BU_:  Airbag BAP_Tester ICAS1_Gateway ICAS1_KommunikationsServer LE1 LE2 Motor_BEV Schaltbetaetigung

BU_:  Airbag BAP_Tester ICAS1_Gateway ICAS1_KommunikationsServer LE1 LE2 Motor_BEV Schaltbetaetigung

BO_ 252 ESC_51: 48 ICAS1_Gateway
 SG_ ESC_51_CRC  : 0|8@1+ (1.000000,0.000000) [0.000000|255.000000] "" Motor_BEV
 SG_ ESC_51_BZ  : 8|4@1+ (1.000000,0.000000) [0.000000|15.000000] "" Motor_BEV
 SG_ ESC_aktBr_Modus  : 12|2@1+ (1.000000,0.000000) [0.000000|3.000000] "" Vector__XXX
 SG_ ESC_Blending_Solldruck  : 14|10@1+ (0.250000,0.000000) [0.000000|250.000000] "Unit_Bar" Vector__XXX
 SG_ ESC_aktBr_Volumenstrom  : 24|16@1+ (0.007812,-252.000000) [-252.000000|252.000000] "Unit_MilliLiterPerSec" Vector__XXX
 SG_ ESC_EBKV_Kraftblending_Modus  : 40|2@1+ (1.000000,0.000000) [0.000000|3.000000] "" Vector__XXX
 SG_ ESC_Bremsdruck_Modell  : 42|10@1+ (0.250000,0.000000) [0.000000|250.000000] "Unit_Bar" Motor_BEV
 SG_ ESC_Bremsdruck_02  : 52|10@1+ (0.300000,-30.000000) [-30.000000|276.600000] "Unit_Bar" Vector__XXX
 SG_ ESC_QBit_Bremsdruck_02  : 62|1@1+ (1.000000,0.000000) [0.000000|1.000000] "" Vector__XXX
 SG_ ESP_HL_Radgeschw_02  : 64|16@1+ (0.007500,0.000000) [0.000000|491.490000] "Unit_KiloMeterPerHour" Airbag LE1 LE2 Motor_BEV
 SG_ ESP_HR_Radgeschw_02  : 80|16@1+ (0.007500,0.000000) [0.000000|491.490000] "Unit_KiloMeterPerHour" Airbag LE1 LE2 Motor_BEV
 SG_ ESP_VL_Radgeschw_02  : 96|16@1+ (0.007500,0.000000) [0.000000|491.490000] "Unit_KiloMeterPerHour" Airbag LE1 LE2 Motor_BEV
 SG_ ESP_VR_Radgeschw_02  : 112|16@1+ (0.007500,0.000000) [0.000000|491.490000] "Unit_KiloMeterPerHour" Airbag LE1 LE2 Motor_BEV
 SG_ ESP_FZR_uebersteuern  : 128|8@1+ (0.004000,0.000000) [0.000000|1.000000] "" Vector__XXX
 SG_ ESP_FZR_untersteuern  : 136|8@1+ (0.004000,0.000000) [0.000000|1.000000] "" Vector__XXX
 SG_ ESC_Anf_Mindestreku  : 144|1@1+ (1.000000,0.000000) [0.000000|1.000000] "" Motor_BEV
 SG_ ESC_GMV_aktiv  : 145|3@1+ (1.000000,0.000000) [0.000000|7.000000] "" Vector__XXX
 SG_ ESC_GMV_nicht_verfuegbar  : 148|1@1+ (1.000000,0.000000) [0.000000|1.000000] "" Vector__XXX
 SG_ ESC_Status_vRef_Stuetzeingriff  : 149|1@1+ (1.000000,0.000000) [0.000000|1.000000] "" Motor_BEV
 SG_ FDR_Allradverteilung_aktiv  : 150|1@1+ (1.000000,0.000000) [0.000000|1.000000] "" Vector__XXX
 SG_ FDR_Anf_Allradbetrieb  : 151|1@1+ (1.000000,0.000000) [0.000000|1.000000] "" Vector__XXX
 SG_ ESP_HL_Bremsmoment  : 152|8@1+ (20.000000,0.000000) [0.000000|5060.000000] "Unit_NewtoMeter" Motor_BEV
 SG_ ESP_HR_Bremsmoment  : 160|8@1+ (20.000000,0.000000) [0.000000|5060.000000] "Unit_NewtoMeter" Motor_BEV
 SG_ ESP_VR_Bremsmoment  : 168|8@1+ (40.000000,0.000000) [0.000000|10120.000000] "Unit_NewtoMeter" Motor_BEV
 SG_ ESP_VL_Bremsmoment  : 176|8@1+ (40.000000,0.000000) [0.000000|10120.000000] "Unit_NewtoMeter" Motor_BEV
 SG_ ESP_FDR_uebersteuern  : 184|8@1+ (0.004000,0.000000) [0.000000|1.000000] "" Motor_BEV
 SG_ ESP_FDR_untersteuern  : 192|8@1+ (0.004000,0.000000) [0.000000|1.000000] "" Motor_BEV
 SG_ TSMomBegrenzung  : 268|12@1+ (3.000000,-12279.000000) [-12279.000000|0.000000] "" Motor_BEV
 SG_ ESC_Allrad_Anteil_max_sek  : 280|9@1+ (0.200000,0.000000) [0.000000|100.000000] "Unit_PerCent" Motor_BEV
 SG_ ESC_Allrad_Anteil_min_sek  : 289|9@1+ (0.200000,0.000000) [0.000000|100.000000] "Unit_PerCent" Motor_BEV
 SG_ ESC_Status_Eingriff  : 298|2@1+ (1.000000,0.000000) [0.000000|3.000000] "" Motor_BEV
 SG_ ESC_Status_Eingriff_sek  : 300|2@1+ (1.000000,0.000000) [0.000000|3.000000] "" Motor_BEV
 SG_ ESC_MomRad_Eingriff  : 302|13@1+ (3.000000,-12279.000000) [-12279.000000|12279.000000] "Unit_None" Motor_BEV
 SG_ ESC_MomRad_Eingriff_sek  : 315|13@1+ (3.000000,-12279.000000) [-12279.000000|12279.000000] "Unit_None" Motor_BEV
 SG_ ESC_Achsdrehzahl_Max  : 328|14@1+ (0.400000,-800.000000) [-800.000000|5752.400000] "Unit_MinutInver" Motor_BEV
 SG_ ESC_Achsdrehzahl_Min  : 342|14@1+ (0.400000,-800.000000) [-800.000000|5752.400000] "Unit_MinutInver" Motor_BEV
 SG_ ESC_Achsdrehzahl_Max_sek  : 356|14@1+ (0.400000,-800.000000) [-800.000000|5752.400000] "Unit_MinutInver" Motor_BEV
 SG_ ESC_Achsdrehzahl_Min_sek  : 370|14@1+ (0.400000,-800.000000) [-800.000000|5752.400000] "Unit_MinutInver" Motor_BEV

BO_ 2463978647 ESC_52: 16 ICAS1_Gateway
 SG_ ESP_ACC_LDE  : 12|1@1+ (1.000000,0.000000) [0.000000|1.000000] "" Vector__XXX
 SG_ ESP_Allrad_Antrieb  : 13|1@1+ (1.000000,0.000000) [0.000000|1.000000] "" Vector__XXX
 SG_ ESP_Codierung_ADS  : 14|2@1+ (1.000000,0.000000) [0.000000|3.000000] "" Vector__XXX
 SG_ ESP_RTA_HL  : 16|8@1+ (0.048828,-6.201170) [-6.201170|6.152346] "Unit_PerCent" Motor_BEV
 SG_ ESP_RTA_HR  : 24|8@1+ (0.048828,-6.201170) [-6.201170|6.152346] "Unit_PerCent" Motor_BEV
 SG_ ESP_RTA_VR  : 32|8@1+ (0.048828,-6.201170) [-6.201170|6.152346] "Unit_PerCent" Motor_BEV
 SG_ OBD_Fehler_Radsensor_HL  : 40|4@1+ (1.000000,0.000000) [0.000000|15.000000] "" Motor_BEV
 SG_ OBD_Fehler_Radsensor_HR  : 44|4@1+ (1.000000,0.000000) [0.000000|15.000000] "" Motor_BEV
 SG_ OBD_Fehler_Radsensor_VL  : 48|4@1+ (1.000000,0.000000) [0.000000|15.000000] "" Motor_BEV
 SG_ OBD_Fehler_Radsensor_VR  : 52|4@1+ (1.000000,0.000000) [0.000000|15.000000] "" Motor_BEV
 SG_ ESP_Qualifizierung_Antriebsart  : 56|1@1+ (1.000000,0.000000) [0.000000|1.000000] "" Vector__XXX
 SG_ ESP_Offroad_Modus  : 57|1@1+ (1.000000,0.000000) [0.000000|1.000000] "" Vector__XXX
 SG_ ESP_MKB_ausloesbar  : 58|1@1+ (1.000000,0.000000) [0.000000|1.000000] "" Vector__XXX
 SG_ ESP_Stat_FallBack_eBKV  : 59|1@1+ (1.000000,0.000000) [0.000000|1.000000] "" Vector__XXX
 SG_ ESP_CM_Variante  : 60|1@1+ (1.000000,0.000000) [0.000000|1.000000] "" Vector__XXX
 SG_ ESP_OBD_Status  : 61|1@1+ (1.000000,0.000000) [0.000000|1.000000] "" Motor_BEV
 SG_ ESP_Rollenmodus_Deaktivieren  : 62|1@1+ (1.000000,0.000000) [0.000000|1.000000] "" Motor_BEV
 SG_ ESP_nachtr_Stopp_Anf  : 63|1@1+ (1.000000,0.000000) [0.000000|1.000000] "" Vector__XXX

BO_ 2527679683 ESC_ASM_01: 8 ICAS1_Gateway
 SG_ ESC_ASM_Ereignis  : 0|8@1+ (1.000000,0.000000) [1.000000|254.000000] "Unit_None" Airbag
 SG_ ESC_ASM_Zeitstempel  : 8|8@1+ (0.080000,0.000000) [0.000000|20.320000] "Unit_Secon" Airbag
 SG_ ESC_ASM_Data_1  : 16|8@1+ (1.000000,0.000000) [0.000000|255.000000] "" Airbag
 SG_ ESC_ASM_Data_2  : 24|8@1+ (1.000000,0.000000) [0.000000|255.000000] "" Airbag
 SG_ ESC_ASM_Data_3  : 32|8@1+ (1.000000,0.000000) [0.000000|255.000000] "" Airbag
 SG_ ESC_ASM_Data_4  : 40|8@1+ (1.000000,0.000000) [0.000000|255.000000] "" Airbag
 SG_ ESC_ASM_Data_5  : 48|8@1+ (1.000000,0.000000) [0.000000|255.000000] "" Airbag
 SG_ ESC_ASM_Data_6  : 56|8@1+ (1.000000,0.000000) [0.000000|255.000000] "" Airbag

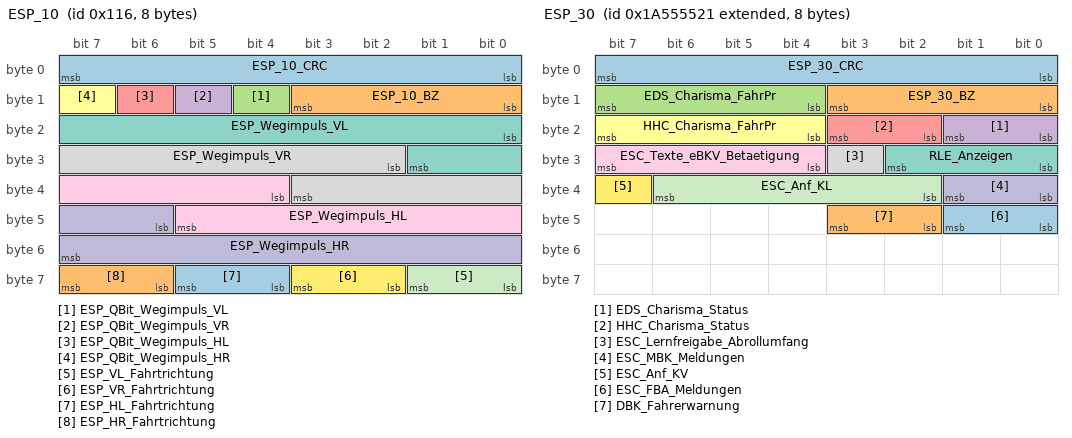
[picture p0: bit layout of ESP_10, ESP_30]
BO_ 278 ESP_10: 8 ICAS1_Gateway
 SG_ ESP_10_CRC  : 0|8@1+ (1.000000,0.000000) [0.000000|255.000000] "" Vector__XXX
 SG_ ESP_10_BZ  : 8|4@1+ (1.000000,0.000000) [0.000000|15.000000] "" Vector__XXX
 SG_ ESP_QBit_Wegimpuls_VL  : 12|1@1+ (1.000000,0.000000) [0.000000|1.000000] "" Motor_BEV
 SG_ ESP_QBit_Wegimpuls_VR  : 13|1@1+ (1.000000,0.000000) [0.000000|1.000000] "" Motor_BEV
 SG_ ESP_QBit_Wegimpuls_HL  : 14|1@1+ (1.000000,0.000000) [0.000000|1.000000] "" Motor_BEV
 SG_ ESP_QBit_Wegimpuls_HR  : 15|1@1+ (1.000000,0.000000) [0.000000|1.000000] "" Motor_BEV
 SG_ ESP_Wegimpuls_VL  : 16|10@1+ (1.000000,0.000000) [0.000000|1000.000000] "" Motor_BEV
 SG_ ESP_Wegimpuls_VR  : 26|10@1+ (1.000000,0.000000) [0.000000|1000.000000] "" Motor_BEV
 SG_ ESP_Wegimpuls_HL  : 36|10@1+ (1.000000,0.000000) [0.000000|1000.000000] "" Motor_BEV
 SG_ ESP_Wegimpuls_HR  : 46|10@1+ (1.000000,0.000000) [0.000000|1000.000000] "" Motor_BEV
 SG_ ESP_VL_Fahrtrichtung  : 56|2@1+ (1.000000,0.000000) [0.000000|3.000000] "" Motor_BEV
 SG_ ESP_VR_Fahrtrichtung  : 58|2@1+ (1.000000,0.000000) [0.000000|3.000000] "" Motor_BEV
 SG_ ESP_HL_Fahrtrichtung  : 60|2@1+ (1.000000,0.000000) [0.000000|3.000000] "" Motor_BEV
 SG_ ESP_HR_Fahrtrichtung  : 62|2@1+ (1.000000,0.000000) [0.000000|3.000000] "" Motor_BEV

BO_ 1629 ESP_20: 8 ICAS1_Gateway
 SG_ ESP_20_CRC  : 0|8@1+ (1.000000,0.000000) [0.000000|255.000000] "" Vector__XXX
 SG_ ESP_20_BZ  : 8|4@1+ (1.000000,0.000000) [0.000000|15.000000] "" Vector__XXX
 SG_ BR_Systemart  : 12|2@1+ (1.000000,0.000000) [0.000000|3.000000] "" Vector__XXX
 SG_ ESP_SpannungsAnf_02  : 14|2@1+ (1.000000,0.000000) [0.000000|3.000000] "" Vector__XXX
 SG_ ESP_Zaehnezahl  : 16|8@1+ (1.000000,0.000000) [0.000000|255.000000] "" Vector__XXX
 SG_ ESP_Charisma_FahrPr  : 24|4@1+ (1.000000,0.000000) [0.000000|15.000000] "" Vector__XXX
 SG_ ESP_Charisma_Status  : 28|2@1+ (1.000000,0.000000) [0.000000|3.000000] "" Vector__XXX
 SG_ ESP_Wiederstart_Anz_01  : 30|1@1+ (1.000000,0.000000) [0.000000|1.000000] "" Vector__XXX
 SG_ ESP_Wiederstart_Anz_02  : 31|1@1+ (1.000000,0.000000) [0.000000|1.000000] "" Vector__XXX
 SG_ ESP_Wiederstart_Anz_03  : 32|1@1+ (1.000000,0.000000) [0.000000|1.000000] "" Vector__XXX
 SG_ ESP_Wiederstart_Anz_04  : 33|1@1+ (1.000000,0.000000) [0.000000|1.000000] "" Vector__XXX
 SG_ ESP_Stoppverbot_Anz_01  : 34|1@1+ (1.000000,0.000000) [0.000000|1.000000] "" Vector__XXX
 SG_ ESP_Stoppverbot_Anz_02  : 35|1@1+ (1.000000,0.000000) [0.000000|1.000000] "" Vector__XXX
 SG_ ESP_Stoppverbot_Anz_03  : 36|1@1+ (1.000000,0.000000) [0.000000|1.000000] "" Vector__XXX
 SG_ ESP_Stoppverbot_Anz_04  : 37|1@1+ (1.000000,0.000000) [0.000000|1.000000] "" Vector__XXX
 SG_ ESP_Stoppverbot_Anz_05  : 38|1@1+ (1.000000,0.000000) [0.000000|1.000000] "" Vector__XXX
 SG_ ESP_Stoppverbot_Anz_06  : 39|1@1+ (1.000000,0.000000) [0.000000|1.000000] "" Vector__XXX
 SG_ ESP_Stoppverbot_Anz_07  : 40|1@1+ (1.000000,0.000000) [0.000000|1.000000] "" Vector__XXX
 SG_ ESP_Stoppverbot_Anz_Std  : 41|1@1+ (1.000000,0.000000) [0.000000|1.000000] "" Vector__XXX
 SG_ ESP_Dachrelingsensor  : 42|2@1+ (1.000000,0.000000) [0.000000|3.000000] "" Vector__XXX
 SG_ ESP_Stoppverbot_Anz_08  : 44|1@1+ (1.000000,0.000000) [0.000000|1.000000] "" Vector__XXX
 SG_ HDC_Charisma_FahrPr  : 45|4@1+ (1.000000,0.000000) [0.000000|15.000000] "" Vector__XXX
 SG_ HDC_Charisma_Status  : 49|2@1+ (1.000000,0.000000) [0.000000|3.000000] "" Vector__XXX
 SG_ BR_QBit_Reifenumfang  : 51|1@1+ (1.000000,0.000000) [0.000000|1.000000] "" LE1 LE2
 SG_ BR_Reifenumfang  : 52|12@1+ (1.000000,0.000000) [0.000000|4095.000000] "Unit_MilliMeter" LE1 LE2

BO_ 253 ESP_21: 8 ICAS1_Gateway
 SG_ ESP_21_CRC  : 0|8@1+ (1.000000,0.000000) [0.000000|255.000000] "" Airbag LE1 LE2 Motor_BEV
 SG_ ESP_21_BZ  : 8|4@1+ (1.000000,0.000000) [0.000000|15.000000] "" Airbag LE1 LE2 Motor_BEV
 SG_ BR_Eingriffsmoment  : 12|10@1+ (1.000000,-509.000000) [-509.000000|509.000000] "" Vector__XXX
 SG_ ESP_PLA_Bremseingriff  : 22|1@1+ (1.000000,0.000000) [0.000000|1.000000] "" Vector__XXX
 SG_ ESP_Diagnose  : 23|1@1+ (1.000000,0.000000) [0.000000|1.000000] "" Vector__XXX
 SG_ ESC_Reku_Freigabe  : 24|1@1+ (1.000000,0.000000) [0.000000|1.000000] "" Motor_BEV
 SG_ ESC_v_Signal_Qualifier_High_Low  : 25|3@1+ (1.000000,0.000000) [0.000000|7.000000] "" Airbag
 SG_ ESP_Vorsteuerung  : 28|1@1+ (1.000000,0.000000) [0.000000|1.000000] "" Motor_BEV
 SG_ ESP_AWV3_Brems_aktiv  : 29|1@1+ (1.000000,0.000000) [0.000000|1.000000] "" Vector__XXX
 SG_ OBD_Schlechtweg  : 30|1@1+ (1.000000,0.000000) [0.000000|1.000000] "" Vector__XXX
 SG_ OBD_QBit_Schlechtweg  : 31|1@1+ (1.000000,0.000000) [0.000000|1.000000] "" Vector__XXX
 SG_ ESP_v_Signal  : 32|16@1+ (0.010000,0.000000) [0.000000|655.320000] "Unit_KiloMeterPerHour" Airbag LE1 LE2 Motor_BEV
 SG_ ASR_Tastung_passiv  : 48|1@1+ (1.000000,0.000000) [0.000000|1.000000] "" Airbag Motor_BEV
 SG_ ESP_Tastung_passiv  : 49|1@1+ (1.000000,0.000000) [0.000000|1.000000] "" Airbag Motor_BEV
 SG_ ESP_Systemstatus  : 50|1@1+ (1.000000,0.000000) [0.000000|1.000000] "" Motor_BEV
 SG_ ASR_Schalteingriff  : 51|2@1+ (1.000000,0.000000) [0.000000|3.000000] "" Vector__XXX
 SG_ ESP_Haltebestaetigung  : 53|1@1+ (1.000000,0.000000) [0.000000|1.000000] "" Vector__XXX
 SG_ ESP_MKB_Abbruch_Geschw  : 54|1@1+ (1.000000,0.000000) [0.000000|1.000000] "" Vector__XXX
 SG_ ESP_QBit_v_Signal  : 55|1@1+ (1.000000,0.000000) [0.000000|1.000000] "" LE1 LE2 Motor_BEV
 SG_ ABS_Bremsung  : 56|1@1+ (1.000000,0.000000) [0.000000|1.000000] "" Airbag Motor_BEV
 SG_ ASR_Anf  : 57|1@1+ (1.000000,0.000000) [0.000000|1.000000] "" Vector__XXX
 SG_ MSR_Anf  : 58|1@1+ (1.000000,0.000000) [0.000000|1.000000] "" Vector__XXX
 SG_ EBV_Eingriff  : 59|1@1+ (1.000000,0.000000) [0.000000|1.000000] "" Vector__XXX
 SG_ EDS_Eingriff  : 60|1@1+ (1.000000,0.000000) [0.000000|1.000000] "" Motor_BEV
 SG_ ESP_Eingriff  : 61|1@1+ (1.000000,0.000000) [0.000000|1.000000] "" Airbag Motor_BEV
 SG_ ESP_ASP  : 62|1@1+ (1.000000,0.000000) [0.000000|1.000000] "" Vector__XXX
 SG_ ESP_Anhaltevorgang_ACC_aktiv  : 63|1@1+ (1.000000,0.000000) [0.000000|1.000000] "" Vector__XXX

BO_ 795 ESP_24: 8 ICAS1_Gateway
 SG_ ESP_24_CRC  : 0|8@1+ (1.000000,0.000000) [0.000000|255.000000] "" Vector__XXX
 SG_ ESP_24_BZ  : 8|4@1+ (1.000000,0.000000) [0.000000|15.000000] "" Vector__XXX
 SG_ ESP_Lampe  : 12|1@1+ (1.000000,0.000000) [0.000000|1.000000] "" Motor_BEV
 SG_ ABS_Lampe  : 13|1@1+ (1.000000,0.000000) [0.000000|1.000000] "" Vector__XXX
 SG_ BK_Lampe_02  : 14|2@1+ (1.000000,0.000000) [0.000000|3.000000] "" Vector__XXX
 SG_ TC_Lampe  : 16|1@1+ (1.000000,0.000000) [0.000000|1.000000] "" Vector__XXX
 SG_ ESP_m_Raddrehz  : 17|15@1+ (0.002000,0.000000) [0.000000|65.278000] "Unit_Hertz" Vector__XXX
 SG_ ESP_Textanzeigen_03  : 32|5@1+ (1.000000,0.000000) [0.000000|31.000000] "" Vector__XXX
 SG_ ESP_Meldungen  : 37|3@1+ (1.000000,0.000000) [0.000000|7.000000] "" Vector__XXX
 SG_ ESP_Wegimp_VA  : 40|11@1+ (1.000000,0.000000) [0.000000|2047.000000] "" Vector__XXX
 SG_ ESP_Fehlerstatus_Wegimp  : 51|1@1+ (1.000000,0.000000) [0.000000|1.000000] "" Vector__XXX
 SG_ ESP_Wegimp_Ueberlauf  : 52|1@1+ (1.000000,0.000000) [0.000000|1.000000] "" Vector__XXX
 SG_ ESP_QBit_Wegimp_VA  : 53|1@1+ (1.000000,0.000000) [0.000000|1.000000] "" Vector__XXX
 SG_ ESP_HDC_FktLampe  : 54|1@1+ (1.000000,0.000000) [0.000000|1.000000] "" Vector__XXX
 SG_ ESP_Off_Lampe  : 55|1@1+ (1.000000,0.000000) [0.000000|1.000000] "" Airbag
 SG_ ESP_HDC_Regelgeschw  : 56|7@1+ (0.320000,0.000000) [0.320000|39.680000] "Unit_KiloMeterPerHour" Vector__XXX
 SG_ ESP_BKV_Warnung  : 63|1@1+ (1.000000,0.000000) [0.000000|1.000000] "" Vector__XXX

BO_ 2589283617 ESP_30: 8 ICAS1_Gateway
 SG_ ESP_30_CRC  : 0|8@1+ (1.000000,0.000000) [0.000000|255.000000] "" Vector__XXX
 SG_ ESP_30_BZ  : 8|4@1+ (1.000000,0.000000) [0.000000|15.000000] "" Vector__XXX
 SG_ EDS_Charisma_FahrPr  : 12|4@1+ (1.000000,0.000000) [0.000000|15.000000] "" Vector__XXX
 SG_ EDS_Charisma_Status  : 16|2@1+ (1.000000,0.000000) [0.000000|3.000000] "" Vector__XXX
 SG_ HHC_Charisma_Status  : 18|2@1+ (1.000000,0.000000) [0.000000|3.000000] "" Vector__XXX
 SG_ HHC_Charisma_FahrPr  : 20|4@1+ (1.000000,0.000000) [0.000000|15.000000] "" Vector__XXX
 SG_ RLE_Anzeigen  : 24|3@1+ (1.000000,0.000000) [0.000000|7.000000] "" Vector__XXX
 SG_ ESC_Lernfreigabe_Abrollumfang  : 27|1@1+ (1.000000,0.000000) [0.000000|1.000000] "" Vector__XXX
 SG_ ESC_Texte_eBKV_Betaetigung  : 28|4@1+ (1.000000,0.000000) [0.000000|15.000000] "" Vector__XXX
 SG_ ESC_MBK_Meldungen  : 32|2@1+ (1.000000,0.000000) [0.000000|3.000000] "" Vector__XXX
 SG_ ESC_Anf_KL  : 34|5@1+ (3.225806,0.000000) [0.000000|100.000000] "Unit_PerCent" Motor_BEV
 SG_ ESC_Anf_KV  : 39|1@1+ (1.000000,0.000000) [0.000000|1.000000] "" Motor_BEV
 SG_ ESC_FBA_Meldungen  : 40|2@1+ (1.000000,0.000000) [0.000000|3.000000] "" Vector__XXX
 SG_ DBK_Fahrerwarnung  : 42|2@1+ (1.000000,0.000000) [0.000000|3.000000] "" Vector__XXX

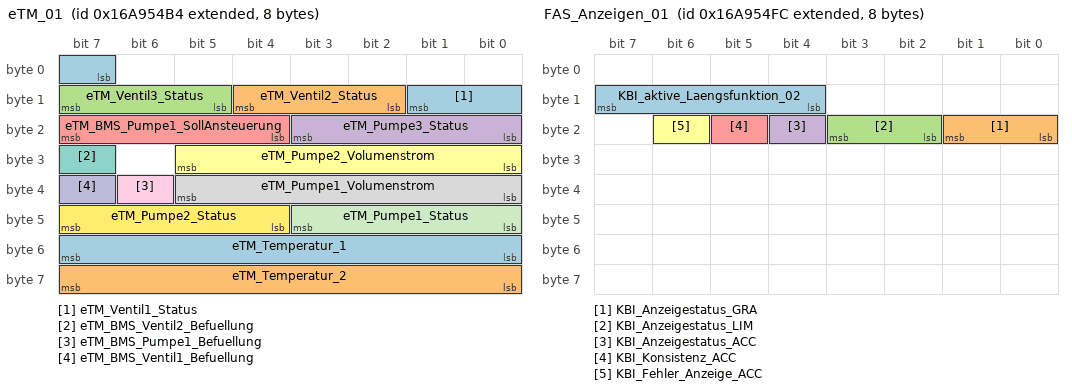
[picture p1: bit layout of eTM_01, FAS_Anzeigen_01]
BO_ 2527679668 eTM_01: 8 Motor_BEV
 SG_ eTM_Ventil1_Status  : 7|3@1+ (1.000000,0.000000) [0.000000|7.000000] "" ICAS1_Gateway
 SG_ eTM_Ventil2_Status  : 10|3@1+ (1.000000,0.000000) [0.000000|7.000000] "" ICAS1_Gateway
 SG_ eTM_Ventil3_Status  : 13|3@1+ (1.000000,0.000000) [0.000000|7.000000] "" ICAS1_Gateway
 SG_ eTM_Pumpe3_Status  : 16|4@1+ (10.000000,0.000000) [0.000000|130.000000] "Unit_PerCent" ICAS1_Gateway
 SG_ eTM_BMS_Pumpe1_SollAnsteuerung  : 20|4@1+ (10.000000,0.000000) [0.000000|130.000000] "Unit_PerCent" ICAS1_Gateway
 SG_ eTM_Pumpe2_Volumenstrom  : 24|6@1+ (0.500000,0.000000) [0.000000|30.500000] "Unit_LiterPerMinut" ICAS1_Gateway LE1 LE2
 SG_ eTM_BMS_Ventil2_Befuellung  : 31|1@1+ (1.000000,0.000000) [0.000000|1.000000] "" ICAS1_Gateway
 SG_ eTM_Pumpe1_Volumenstrom  : 32|6@1+ (0.500000,0.000000) [0.000000|30.500000] "Unit_LiterPerMinut" ICAS1_Gateway LE1 LE2
 SG_ eTM_BMS_Pumpe1_Befuellung  : 38|1@1+ (1.000000,0.000000) [0.000000|1.000000] "" ICAS1_Gateway
 SG_ eTM_BMS_Ventil1_Befuellung  : 39|1@1+ (1.000000,0.000000) [0.000000|1.000000] "" ICAS1_Gateway
 SG_ eTM_Pumpe1_Status  : 40|4@1+ (10.000000,0.000000) [0.000000|130.000000] "Unit_PerCent" ICAS1_Gateway LE1 LE2
 SG_ eTM_Pumpe2_Status  : 44|4@1+ (10.000000,0.000000) [0.000000|130.000000] "Unit_PerCent" ICAS1_Gateway LE1 LE2
 SG_ eTM_Temperatur_1  : 48|8@1+ (0.750000,-40.000000) [-40.000000|149.750000] "Unit_DegreCelsi" ICAS1_Gateway LE1 LE2
 SG_ eTM_Temperatur_2  : 56|8@1+ (0.750000,-40.000000) [-40.000000|149.750000] "Unit_DegreCelsi" ICAS1_Gateway LE1 LE2

BO_ 2527679740 FAS_Anzeigen_01: 8 ICAS1_KommunikationsServer
 SG_ KBI_aktive_Laengsfunktion_02  : 12|4@1+ (1.000000,0.000000) [0.000000|15.000000] "" Motor_BEV
 SG_ KBI_Anzeigestatus_GRA  : 16|2@1+ (1.000000,0.000000) [0.000000|3.000000] "" Motor_BEV
 SG_ KBI_Anzeigestatus_LIM  : 18|2@1+ (1.000000,0.000000) [0.000000|3.000000] "" Motor_BEV
 SG_ KBI_Anzeigestatus_ACC  : 20|1@1+ (1.000000,0.000000) [0.000000|1.000000] "" Vector__XXX
 SG_ KBI_Konsistenz_ACC  : 21|1@1+ (1.000000,0.000000) [0.000000|1.000000] "" Vector__XXX
 SG_ KBI_Fehler_Anzeige_ACC  : 22|1@1+ (1.000000,0.000000) [0.000000|1.000000] "" Vector__XXX

BO_ 2589283684 FoD_01: 8 ICAS1_Gateway
 SG_ GRA_FoD_Status  : 58|2@1+ (1.000000,0.000000) [0.000000|3.000000] "" Vector__XXX
 SG_ FoD_Transmission_Info  : 60|2@1+ (1.000000,0.000000) [0.000000|3.000000] "" Motor_BEV

BO_ 2549875574 FoD_MO_01_Req: 8 ICAS1_Gateway
 SG_ FoD_MO_01_Req_Data  : 0|64@1+ (1.000000,0.000000) [0.000000|18446744073709551616.000000] "" Motor_BEV

BO_ 2550006646 FoD_MO_01_Resp: 8 Motor_BEV
 SG_ FoD_MO_01_Resp_Data  : 0|64@1+ (1.000000,0.000000) [0.000000|18446744073709551616.000000] "" ICAS1_Gateway

BO_ 987 Gateway_72: 8 ICAS1_Gateway
 SG_ BCM_01_alt  : 0|1@1+ (1.000000,0.000000) [0.000000|1.000000] "" Airbag
 SG_ SMLS_01_alt  : 1|1@1+ (1.000000,0.000000) [0.000000|1.000000] "" Vector__XXX
 SG_ ZV_02_alt  : 2|1@1+ (1.000000,0.000000) [0.000000|1.000000] "" Vector__XXX
 SG_ Wischer_01_alt  : 3|1@1+ (1.000000,0.000000) [0.000000|1.000000] "" Vector__XXX
 SG_ Anhaenger_01_alt  : 4|1@1+ (1.000000,0.000000) [0.000000|1.000000] "" Airbag
 SG_ Klima_Sensor_02_alt  : 5|1@1+ (1.000000,0.000000) [0.000000|1.000000] "" Vector__XXX
 SG_ Verdeck_01_alt  : 6|1@1+ (1.000000,0.000000) [0.000000|1.000000] "" Vector__XXX
 SG_ Klima_11_alt  : 7|1@1+ (1.000000,0.000000) [0.000000|1.000000] "" Vector__XXX
 SG_ WFS_01_alt  : 8|1@1+ (1.000000,0.000000) [0.000000|1.000000] "" Vector__XXX
 SG_ Licht_Anf_01_alt  : 9|1@1+ (1.000000,0.000000) [0.000000|1.000000] "" Vector__XXX
 SG_ ZV_verriegelt_extern_soll  : 10|1@1+ (1.000000,0.000000) [0.000000|1.000000] "" Vector__XXX
 SG_ BH_Lichthupe  : 11|1@1+ (1.000000,0.000000) [0.000000|1.000000] "" Vector__XXX
 SG_ WFS_Klemmenfreigabe  : 12|1@1+ (1.000000,0.000000) [0.000000|1.000000] "" Vector__XXX
 SG_ ZV_Tankklappe_offen  : 13|1@1+ (1.000000,0.000000) [0.000000|1.000000] "" Vector__XXX
 SG_ AAG_Anhaenger_abgesteckt  : 14|1@1+ (1.000000,0.000000) [0.000000|1.000000] "" Vector__XXX
 SG_ BCM1_LDS_Stellung  : 15|3@1+ (1.000000,0.000000) [0.000000|7.000000] "" Vector__XXX
 SG_ VS_Verdeck_Anf  : 18|1@1+ (1.000000,0.000000) [0.000000|1.000000] "" Vector__XXX
 SG_ VS_VD_entriegelt  : 19|1@1+ (1.000000,0.000000) [0.000000|1.000000] "" Vector__XXX
 SG_ ZV_HFS_offen  : 20|1@1+ (1.000000,0.000000) [0.000000|1.000000] "" Vector__XXX
 SG_ ZV_HBFS_offen  : 21|1@1+ (1.000000,0.000000) [0.000000|1.000000] "" Vector__XXX
 SG_ VS_VD_offen_ver  : 22|1@1+ (1.000000,0.000000) [0.000000|1.000000] "" Vector__XXX
 SG_ VS_VD_zu_ver  : 23|1@1+ (1.000000,0.000000) [0.000000|1.000000] "" Vector__XXX
 SG_ ZV_BT_offen  : 24|1@1+ (1.000000,0.000000) [0.000000|1.000000] "" Vector__XXX
 SG_ BCM1_Rueckfahrlicht_Schalter  : 25|1@1+ (1.000000,0.000000) [0.000000|1.000000] "" Airbag Motor_BEV
 SG_ ZV_FT_offen  : 26|1@1+ (1.000000,0.000000) [0.000000|1.000000] "" Vector__XXX
 SG_ Wischer_vorne_aktiv  : 27|1@1+ (1.000000,0.000000) [0.000000|1.000000] "" Vector__XXX
 SG_ AAG_Anhaenger_erkannt  : 28|1@1+ (1.000000,0.000000) [0.000000|1.000000] "" Airbag
 SG_ BCM1_MH_Schalter  : 29|1@1+ (1.000000,0.000000) [0.000000|1.000000] "" Vector__XXX
 SG_ ZV_HD_offen  : 30|1@1+ (1.000000,0.000000) [0.000000|1.000000] "" Vector__XXX
 SG_ Waschen_vorne_aktiv  : 31|1@1+ (1.000000,0.000000) [0.000000|1.000000] "" Vector__XXX
 SG_ KL_Thermomanagement  : 32|2@1+ (1.000000,0.000000) [0.000000|3.000000] "" Vector__XXX
 SG_ WFS_Schluessel_Fahrberecht  : 34|4@1+ (1.000000,0.000000) [0.000000|15.000000] "" Vector__XXX
 SG_ BCM_Rueckfahrlicht_Anf  : 38|1@1+ (1.000000,0.000000) [0.000000|1.000000] "" Vector__XXX
 SG_ WWSs_01_alt  : 39|1@1+ (1.000000,0.000000) [0.000000|1.000000] "" Vector__XXX
 SG_ BCM_Tankklappensteller_Fehler  : 40|1@1+ (1.000000,0.000000) [0.000000|1.000000] "" Vector__XXX
 SG_ AAG_LED_aktiv  : 41|1@1+ (1.000000,0.000000) [0.000000|1.000000] "" Vector__XXX
 SG_ ZV_verriegelt_soll  : 42|2@1+ (1.000000,0.000000) [0.000000|3.000000] "" Vector__XXX
 SG_ ZV_Schluessel_Zugang  : 44|4@1+ (1.000000,0.000000) [0.000000|15.000000] "" Vector__XXX
 SG_ WFS_ID_Geb_autorisiert_in_Kl15  : 48|1@1+ (1.000000,0.000000) [0.000000|1.000000] "" Vector__XXX
 SG_ BH_Fernlicht  : 49|1@1+ (1.000000,0.000000) [0.000000|1.000000] "" Vector__XXX
 SG_ BH_Blinker_li  : 50|1@1+ (1.000000,0.000000) [0.000000|1.000000] "" Vector__XXX
 SG_ BH_Blinker_re  : 51|1@1+ (1.000000,0.000000) [0.000000|1.000000] "" Vector__XXX
 SG_ BCM1_OBD_FStatus_ATemp  : 52|4@1+ (1.000000,0.000000) [0.000000|15.000000] "" Vector__XXX
 SG_ BCM1_Aussen_Temp_ungef  : 56|8@1+ (0.500000,-50.000000) [-50.000000|76.000000] "Unit_DegreCelsi" Vector__XXX

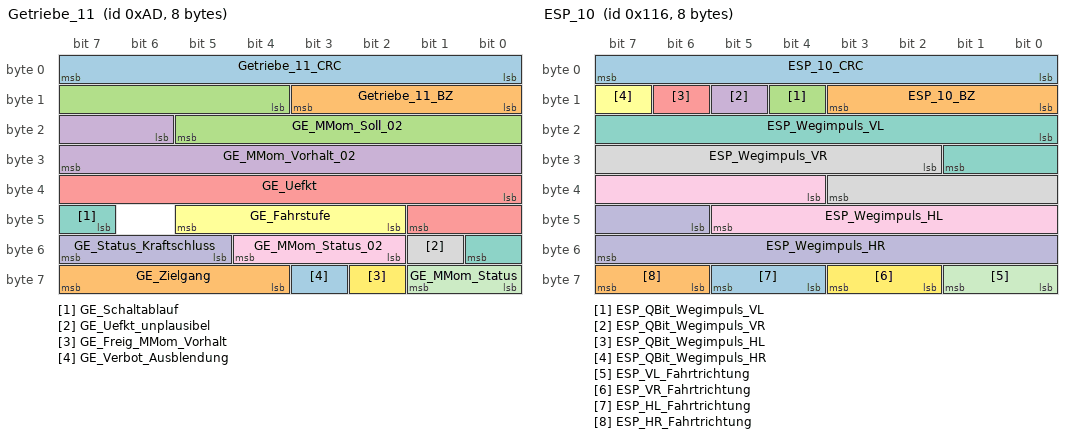
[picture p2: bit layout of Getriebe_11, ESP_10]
BO_ 173 Getriebe_11: 8 Motor_BEV
 SG_ Getriebe_11_CRC  : 0|8@1+ (1.000000,0.000000) [0.000000|255.000000] "" ICAS1_Gateway
 SG_ Getriebe_11_BZ  : 8|4@1+ (1.000000,0.000000) [0.000000|15.000000] "" ICAS1_Gateway
 SG_ GE_MMom_Soll_02  : 12|10@1+ (1.000000,-509.000000) [-509.000000|509.000000] "" ICAS1_Gateway
 SG_ GE_MMom_Vorhalt_02  : 22|10@1+ (1.000000,-509.000000) [-509.000000|509.000000] "" ICAS1_Gateway
 SG_ GE_Uefkt  : 32|10@1+ (0.100000,0.000000) [0.000000|102.200000] "" ICAS1_Gateway
 SG_ GE_Fahrstufe  : 42|4@1+ (1.000000,0.000000) [0.000000|15.000000] "" ICAS1_Gateway
 SG_ GE_Schaltablauf  : 47|2@1+ (1.000000,0.000000) [0.000000|3.000000] "" ICAS1_Gateway
 SG_ GE_Uefkt_unplausibel  : 49|1@1+ (1.000000,0.000000) [0.000000|1.000000] "" ICAS1_Gateway
 SG_ GE_MMom_Status_02  : 50|3@1+ (1.000000,0.000000) [0.000000|7.000000] "" ICAS1_Gateway
 SG_ GE_Status_Kraftschluss  : 53|3@1+ (1.000000,0.000000) [0.000000|7.000000] "" ICAS1_Gateway
 SG_ GE_MMom_Status  : 56|2@1+ (1.000000,0.000000) [0.000000|3.000000] "" ICAS1_Gateway
 SG_ GE_Freig_MMom_Vorhalt  : 58|1@1+ (1.000000,0.000000) [0.000000|1.000000] "" ICAS1_Gateway
 SG_ GE_Verbot_Ausblendung  : 59|1@1+ (1.000000,0.000000) [0.000000|1.000000] "" ICAS1_Gateway
 SG_ GE_Zielgang  : 60|4@1+ (1.000000,0.000000) [0.000000|15.000000] "" ICAS1_Gateway

BU_:  Airbag BAP_Tester ICAS1_Gateway ICAS1_KommunikationsServer LE1 LE2 Motor_BEV Schaltbetaetigung

BO_ 252 ESC_51: 48 ICAS1_Gateway
 SG_ ESC_51_CRC  : 0|8@1+ (1.000000,0.000000) [0.000000|255.000000] "" Motor_BEV
 SG_ ESC_51_BZ  : 8|4@1+ (1.000000,0.000000) [0.000000|15.000000] "" Motor_BEV
 SG_ ESC_aktBr_Modus  : 12|2@1+ (1.000000,0.000000) [0.000000|3.000000] "" Vector__XXX
 SG_ ESC_Blending_Solldruck  : 14|10@1+ (0.250000,0.000000) [0.000000|250.000000] "Unit_Bar" Vector__XXX
 SG_ ESC_aktBr_Volumenstrom  : 24|16@1+ (0.007812,-252.000000) [-252.000000|252.000000] "Unit_MilliLiterPerSec" Vector__XXX
 SG_ ESC_EBKV_Kraftblending_Modus  : 40|2@1+ (1.000000,0.000000) [0.000000|3.000000] "" Vector__XXX
 SG_ ESC_Bremsdruck_Modell  : 42|10@1+ (0.250000,0.000000) [0.000000|250.000000] "Unit_Bar" Motor_BEV
 SG_ ESC_Bremsdruck_02  : 52|10@1+ (0.300000,-30.000000) [-30.000000|276.600000] "Unit_Bar" Vector__XXX
 SG_ ESC_QBit_Bremsdruck_02  : 62|1@1+ (1.000000,0.000000) [0.000000|1.000000] "" Vector__XXX
 SG_ ESP_HL_Radgeschw_02  : 64|16@1+ (0.007500,0.000000) [0.000000|491.490000] "Unit_KiloMeterPerHour" Airbag LE1 LE2 Motor_BEV
 SG_ ESP_HR_Radgeschw_02  : 80|16@1+ (0.007500,0.000000) [0.000000|491.490000] "Unit_KiloMeterPerHour" Airbag LE1 LE2 Motor_BEV
 SG_ ESP_VL_Radgeschw_02  : 96|16@1+ (0.007500,0.000000) [0.000000|491.490000] "Unit_KiloMeterPerHour" Airbag LE1 LE2 Motor_BEV
 SG_ ESP_VR_Radgeschw_02  : 112|16@1+ (0.007500,0.000000) [0.000000|491.490000] "Unit_KiloMeterPerHour" Airbag LE1 LE2 Motor_BEV
 SG_ ESP_FZR_uebersteuern  : 128|8@1+ (0.004000,0.000000) [0.000000|1.000000] "" Vector__XXX
 SG_ ESP_FZR_untersteuern  : 136|8@1+ (0.004000,0.000000) [0.000000|1.000000] "" Vector__XXX
 SG_ ESC_Anf_Mindestreku  : 144|1@1+ (1.000000,0.000000) [0.000000|1.000000] "" Motor_BEV
 SG_ ESC_GMV_aktiv  : 145|3@1+ (1.000000,0.000000) [0.000000|7.000000] "" Vector__XXX
 SG_ ESC_GMV_nicht_verfuegbar  : 148|1@1+ (1.000000,0.000000) [0.000000|1.000000] "" Vector__XXX
 SG_ ESC_Status_vRef_Stuetzeingriff  : 149|1@1+ (1.000000,0.000000) [0.000000|1.000000] "" Motor_BEV
 SG_ FDR_Allradverteilung_aktiv  : 150|1@1+ (1.000000,0.000000) [0.000000|1.000000] "" Vector__XXX
 SG_ FDR_Anf_Allradbetrieb  : 151|1@1+ (1.000000,0.000000) [0.000000|1.000000] "" Vector__XXX
 SG_ ESP_HL_Bremsmoment  : 152|8@1+ (20.000000,0.000000) [0.000000|5060.000000] "Unit_NewtoMeter" Motor_BEV
 SG_ ESP_HR_Bremsmoment  : 160|8@1+ (20.000000,0.000000) [0.000000|5060.000000] "Unit_NewtoMeter" Motor_BEV
 SG_ ESP_VR_Bremsmoment  : 168|8@1+ (40.000000,0.000000) [0.000000|10120.000000] "Unit_NewtoMeter" Motor_BEV
 SG_ ESP_VL_Bremsmoment  : 176|8@1+ (40.000000,0.000000) [0.000000|10120.000000] "Unit_NewtoMeter" Motor_BEV
 SG_ ESP_FDR_uebersteuern  : 184|8@1+ (0.004000,0.000000) [0.000000|1.000000] "" Motor_BEV
 SG_ ESP_FDR_untersteuern  : 192|8@1+ (0.004000,0.000000) [0.000000|1.000000] "" Motor_BEV
 SG_ TSMomBegrenzung  : 268|12@1+ (3.000000,-12279.000000) [-12279.000000|0.000000] "" Motor_BEV
 SG_ ESC_Allrad_Anteil_max_sek  : 280|9@1+ (0.200000,0.000000) [0.000000|100.000000] "Unit_PerCent" Motor_BEV
 SG_ ESC_Allrad_Anteil_min_sek  : 289|9@1+ (0.200000,0.000000) [0.000000|100.000000] "Unit_PerCent" Motor_BEV
 SG_ ESC_Status_Eingriff  : 298|2@1+ (1.000000,0.000000) [0.000000|3.000000] "" Motor_BEV
 SG_ ESC_Status_Eingriff_sek  : 300|2@1+ (1.000000,0.000000) [0.000000|3.000000] "" Motor_BEV
 SG_ ESC_MomRad_Eingriff  : 302|13@1+ (3.000000,-12279.000000) [-12279.000000|12279.000000] "Unit_None" Motor_BEV
 SG_ ESC_MomRad_Eingriff_sek  : 315|13@1+ (3.000000,-12279.000000) [-12279.000000|12279.000000] "Unit_None" Motor_BEV
 SG_ ESC_Achsdrehzahl_Max  : 328|14@1+ (0.400000,-800.000000) [-800.000000|5752.400000] "Unit_MinutInver" Motor_BEV
 SG_ ESC_Achsdrehzahl_Min  : 342|14@1+ (0.400000,-800.000000) [-800.000000|5752.400000] "Unit_MinutInver" Motor_BEV
 SG_ ESC_Achsdrehzahl_Max_sek  : 356|14@1+ (0.400000,-800.000000) [-800.000000|5752.400000] "Unit_MinutInver" Motor_BEV
 SG_ ESC_Achsdrehzahl_Min_sek  : 370|14@1+ (0.400000,-800.000000) [-800.000000|5752.400000] "Unit_MinutInver" Motor_BEV

BO_ 2463978647 ESC_52: 16 ICAS1_Gateway
 SG_ ESP_ACC_LDE  : 12|1@1+ (1.000000,0.000000) [0.000000|1.000000] "" Vector__XXX
 SG_ ESP_Allrad_Antrieb  : 13|1@1+ (1.000000,0.000000) [0.000000|1.000000] "" Vector__XXX
 SG_ ESP_Codierung_ADS  : 14|2@1+ (1.000000,0.000000) [0.000000|3.000000] "" Vector__XXX
 SG_ ESP_RTA_HL  : 16|8@1+ (0.048828,-6.201170) [-6.201170|6.152346] "Unit_PerCent" Motor_BEV
 SG_ ESP_RTA_HR  : 24|8@1+ (0.048828,-6.201170) [-6.201170|6.152346] "Unit_PerCent" Motor_BEV
 SG_ ESP_RTA_VR  : 32|8@1+ (0.048828,-6.201170) [-6.201170|6.152346] "Unit_PerCent" Motor_BEV
 SG_ OBD_Fehler_Radsensor_HL  : 40|4@1+ (1.000000,0.000000) [0.000000|15.000000] "" Motor_BEV
 SG_ OBD_Fehler_Radsensor_HR  : 44|4@1+ (1.000000,0.000000) [0.000000|15.000000] "" Motor_BEV
 SG_ OBD_Fehler_Radsensor_VL  : 48|4@1+ (1.000000,0.000000) [0.000000|15.000000] "" Motor_BEV
 SG_ OBD_Fehler_Radsensor_VR  : 52|4@1+ (1.000000,0.000000) [0.000000|15.000000] "" Motor_BEV
 SG_ ESP_Qualifizierung_Antriebsart  : 56|1@1+ (1.000000,0.000000) [0.000000|1.000000] "" Vector__XXX
 SG_ ESP_Offroad_Modus  : 57|1@1+ (1.000000,0.000000) [0.000000|1.000000] "" Vector__XXX
 SG_ ESP_MKB_ausloesbar  : 58|1@1+ (1.000000,0.000000) [0.000000|1.000000] "" Vector__XXX
 SG_ ESP_Stat_FallBack_eBKV  : 59|1@1+ (1.000000,0.000000) [0.000000|1.000000] "" Vector__XXX
 SG_ ESP_CM_Variante  : 60|1@1+ (1.000000,0.000000) [0.000000|1.000000] "" Vector__XXX
 SG_ ESP_OBD_Status  : 61|1@1+ (1.000000,0.000000) [0.000000|1.000000] "" Motor_BEV
 SG_ ESP_Rollenmodus_Deaktivieren  : 62|1@1+ (1.000000,0.000000) [0.000000|1.000000] "" Motor_BEV
 SG_ ESP_nachtr_Stopp_Anf  : 63|1@1+ (1.000000,0.000000) [0.000000|1.000000] "" Vector__XXX

BO_ 2527679683 ESC_ASM_01: 8 ICAS1_Gateway
 SG_ ESC_ASM_Ereignis  : 0|8@1+ (1.000000,0.000000) [1.000000|254.000000] "Unit_None" Airbag
 SG_ ESC_ASM_Zeitstempel  : 8|8@1+ (0.080000,0.000000) [0.000000|20.320000] "Unit_Secon" Airbag
 SG_ ESC_ASM_Data_1  : 16|8@1+ (1.000000,0.000000) [0.000000|255.000000] "" Airbag
 SG_ ESC_ASM_Data_2  : 24|8@1+ (1.000000,0.000000) [0.000000|255.000000] "" Airbag
 SG_ ESC_ASM_Data_3  : 32|8@1+ (1.000000,0.000000) [0.000000|255.000000] "" Airbag
 SG_ ESC_ASM_Data_4  : 40|8@1+ (1.000000,0.000000) [0.000000|255.000000] "" Airbag
 SG_ ESC_ASM_Data_5  : 48|8@1+ (1.000000,0.000000) [0.000000|255.000000] "" Airbag
 SG_ ESC_ASM_Data_6  : 56|8@1+ (1.000000,0.000000) [0.000000|255.000000] "" Airbag

BO_ 278 ESP_10: 8 ICAS1_Gateway
 SG_ ESP_10_CRC  : 0|8@1+ (1.000000,0.000000) [0.000000|255.000000] "" Vector__XXX
 SG_ ESP_10_BZ  : 8|4@1+ (1.000000,0.000000) [0.000000|15.000000] "" Vector__XXX
 SG_ ESP_QBit_Wegimpuls_VL  : 12|1@1+ (1.000000,0.000000) [0.000000|1.000000] "" Motor_BEV
 SG_ ESP_QBit_Wegimpuls_VR  : 13|1@1+ (1.000000,0.000000) [0.000000|1.000000] "" Motor_BEV
 SG_ ESP_QBit_Wegimpuls_HL  : 14|1@1+ (1.000000,0.000000) [0.000000|1.000000] "" Motor_BEV
 SG_ ESP_QBit_Wegimpuls_HR  : 15|1@1+ (1.000000,0.000000) [0.000000|1.000000] "" Motor_BEV
 SG_ ESP_Wegimpuls_VL  : 16|10@1+ (1.000000,0.000000) [0.000000|1000.000000] "" Motor_BEV
 SG_ ESP_Wegimpuls_VR  : 26|10@1+ (1.000000,0.000000) [0.000000|1000.000000] "" Motor_BEV
 SG_ ESP_Wegimpuls_HL  : 36|10@1+ (1.000000,0.000000) [0.000000|1000.000000] "" Motor_BEV
 SG_ ESP_Wegimpuls_HR  : 46|10@1+ (1.000000,0.000000) [0.000000|1000.000000] "" Motor_BEV
 SG_ ESP_VL_Fahrtrichtung  : 56|2@1+ (1.000000,0.000000) [0.000000|3.000000] "" Motor_BEV
 SG_ ESP_VR_Fahrtrichtung  : 58|2@1+ (1.000000,0.000000) [0.000000|3.000000] "" Motor_BEV
 SG_ ESP_HL_Fahrtrichtung  : 60|2@1+ (1.000000,0.000000) [0.000000|3.000000] "" Motor_BEV
 SG_ ESP_HR_Fahrtrichtung  : 62|2@1+ (1.000000,0.000000) [0.000000|3.000000] "" Motor_BEV

BO_ 1629 ESP_20: 8 ICAS1_Gateway
 SG_ ESP_20_CRC  : 0|8@1+ (1.000000,0.000000) [0.000000|255.000000] "" Vector__XXX
 SG_ ESP_20_BZ  : 8|4@1+ (1.000000,0.000000) [0.000000|15.000000] "" Vector__XXX
 SG_ BR_Systemart  : 12|2@1+ (1.000000,0.000000) [0.000000|3.000000] "" Vector__XXX
 SG_ ESP_SpannungsAnf_02  : 14|2@1+ (1.000000,0.000000) [0.000000|3.000000] "" Vector__XXX
 SG_ ESP_Zaehnezahl  : 16|8@1+ (1.000000,0.000000) [0.000000|255.000000] "" Vector__XXX
 SG_ ESP_Charisma_FahrPr  : 24|4@1+ (1.000000,0.000000) [0.000000|15.000000] "" Vector__XXX
 SG_ ESP_Charisma_Status  : 28|2@1+ (1.000000,0.000000) [0.000000|3.000000] "" Vector__XXX
 SG_ ESP_Wiederstart_Anz_01  : 30|1@1+ (1.000000,0.000000) [0.000000|1.000000] "" Vector__XXX
 SG_ ESP_Wiederstart_Anz_02  : 31|1@1+ (1.000000,0.000000) [0.000000|1.000000] "" Vector__XXX
 SG_ ESP_Wiederstart_Anz_03  : 32|1@1+ (1.000000,0.000000) [0.000000|1.000000] "" Vector__XXX
 SG_ ESP_Wiederstart_Anz_04  : 33|1@1+ (1.000000,0.000000) [0.000000|1.000000] "" Vector__XXX
 SG_ ESP_Stoppverbot_Anz_01  : 34|1@1+ (1.000000,0.000000) [0.000000|1.000000] "" Vector__XXX
 SG_ ESP_Stoppverbot_Anz_02  : 35|1@1+ (1.000000,0.000000) [0.000000|1.000000] "" Vector__XXX
 SG_ ESP_Stoppverbot_Anz_03  : 36|1@1+ (1.000000,0.000000) [0.000000|1.000000] "" Vector__XXX
 SG_ ESP_Stoppverbot_Anz_04  : 37|1@1+ (1.000000,0.000000) [0.000000|1.000000] "" Vector__XXX
 SG_ ESP_Stoppverbot_Anz_05  : 38|1@1+ (1.000000,0.000000) [0.000000|1.000000] "" Vector__XXX
 SG_ ESP_Stoppverbot_Anz_06  : 39|1@1+ (1.000000,0.000000) [0.000000|1.000000] "" Vector__XXX
 SG_ ESP_Stoppverbot_Anz_07  : 40|1@1+ (1.000000,0.000000) [0.000000|1.000000] "" Vector__XXX
 SG_ ESP_Stoppverbot_Anz_Std  : 41|1@1+ (1.000000,0.000000) [0.000000|1.000000] "" Vector__XXX
 SG_ ESP_Dachrelingsensor  : 42|2@1+ (1.000000,0.000000) [0.000000|3.000000] "" Vector__XXX
 SG_ ESP_Stoppverbot_Anz_08  : 44|1@1+ (1.000000,0.000000) [0.000000|1.000000] "" Vector__XXX
 SG_ HDC_Charisma_FahrPr  : 45|4@1+ (1.000000,0.000000) [0.000000|15.000000] "" Vector__XXX
 SG_ HDC_Charisma_Status  : 49|2@1+ (1.000000,0.000000) [0.000000|3.000000] "" Vector__XXX
 SG_ BR_QBit_Reifenumfang  : 51|1@1+ (1.000000,0.000000) [0.000000|1.000000] "" LE1 LE2
 SG_ BR_Reifenumfang  : 52|12@1+ (1.000000,0.000000) [0.000000|4095.000000] "Unit_MilliMeter" LE1 LE2

BO_ 253 ESP_21: 8 ICAS1_Gateway
 SG_ ESP_21_CRC  : 0|8@1+ (1.000000,0.000000) [0.000000|255.000000] "" Airbag LE1 LE2 Motor_BEV
 SG_ ESP_21_BZ  : 8|4@1+ (1.000000,0.000000) [0.000000|15.000000] "" Airbag LE1 LE2 Motor_BEV
 SG_ BR_Eingriffsmoment  : 12|10@1+ (1.000000,-509.000000) [-509.000000|509.000000] "" Vector__XXX
 SG_ ESP_PLA_Bremseingriff  : 22|1@1+ (1.000000,0.000000) [0.000000|1.000000] "" Vector__XXX
 SG_ ESP_Diagnose  : 23|1@1+ (1.000000,0.000000) [0.000000|1.000000] "" Vector__XXX
 SG_ ESC_Reku_Freigabe  : 24|1@1+ (1.000000,0.000000) [0.000000|1.000000] "" Motor_BEV
 SG_ ESC_v_Signal_Qualifier_High_Low  : 25|3@1+ (1.000000,0.000000) [0.000000|7.000000] "" Airbag
 SG_ ESP_Vorsteuerung  : 28|1@1+ (1.000000,0.000000) [0.000000|1.000000] "" Motor_BEV
 SG_ ESP_AWV3_Brems_aktiv  : 29|1@1+ (1.000000,0.000000) [0.000000|1.000000] "" Vector__XXX
 SG_ OBD_Schlechtweg  : 30|1@1+ (1.000000,0.000000) [0.000000|1.000000] "" Vector__XXX
 SG_ OBD_QBit_Schlechtweg  : 31|1@1+ (1.000000,0.000000) [0.000000|1.000000] "" Vector__XXX
 SG_ ESP_v_Signal  : 32|16@1+ (0.010000,0.000000) [0.000000|655.320000] "Unit_KiloMeterPerHour" Airbag LE1 LE2 Motor_BEV
 SG_ ASR_Tastung_passiv  : 48|1@1+ (1.000000,0.000000) [0.000000|1.000000] "" Airbag Motor_BEV
 SG_ ESP_Tastung_passiv  : 49|1@1+ (1.000000,0.000000) [0.000000|1.000000] "" Airbag Motor_BEV
 SG_ ESP_Systemstatus  : 50|1@1+ (1.000000,0.000000) [0.000000|1.000000] "" Motor_BEV
 SG_ ASR_Schalteingriff  : 51|2@1+ (1.000000,0.000000) [0.000000|3.000000] "" Vector__XXX
 SG_ ESP_Haltebestaetigung  : 53|1@1+ (1.000000,0.000000) [0.000000|1.000000] "" Vector__XXX
 SG_ ESP_MKB_Abbruch_Geschw  : 54|1@1+ (1.000000,0.000000) [0.000000|1.000000] "" Vector__XXX
 SG_ ESP_QBit_v_Signal  : 55|1@1+ (1.000000,0.000000) [0.000000|1.000000] "" LE1 LE2 Motor_BEV
 SG_ ABS_Bremsung  : 56|1@1+ (1.000000,0.000000) [0.000000|1.000000] "" Airbag Motor_BEV
 SG_ ASR_Anf  : 57|1@1+ (1.000000,0.000000) [0.000000|1.000000] "" Vector__XXX
 SG_ MSR_Anf  : 58|1@1+ (1.000000,0.000000) [0.000000|1.000000] "" Vector__XXX
 SG_ EBV_Eingriff  : 59|1@1+ (1.000000,0.000000) [0.000000|1.000000] "" Vector__XXX
 SG_ EDS_Eingriff  : 60|1@1+ (1.000000,0.000000) [0.000000|1.000000] "" Motor_BEV
 SG_ ESP_Eingriff  : 61|1@1+ (1.000000,0.000000) [0.000000|1.000000] "" Airbag Motor_BEV
 SG_ ESP_ASP  : 62|1@1+ (1.000000,0.000000) [0.000000|1.000000] "" Vector__XXX
 SG_ ESP_Anhaltevorgang_ACC_aktiv  : 63|1@1+ (1.000000,0.000000) [0.000000|1.000000] "" Vector__XXX

BO_ 795 ESP_24: 8 ICAS1_Gateway
 SG_ ESP_24_CRC  : 0|8@1+ (1.000000,0.000000) [0.000000|255.000000] "" Vector__XXX
 SG_ ESP_24_BZ  : 8|4@1+ (1.000000,0.000000) [0.000000|15.000000] "" Vector__XXX
 SG_ ESP_Lampe  : 12|1@1+ (1.000000,0.000000) [0.000000|1.000000] "" Motor_BEV
 SG_ ABS_Lampe  : 13|1@1+ (1.000000,0.000000) [0.000000|1.000000] "" Vector__XXX
 SG_ BK_Lampe_02  : 14|2@1+ (1.000000,0.000000) [0.000000|3.000000] "" Vector__XXX
 SG_ TC_Lampe  : 16|1@1+ (1.000000,0.000000) [0.000000|1.000000] "" Vector__XXX
 SG_ ESP_m_Raddrehz  : 17|15@1+ (0.002000,0.000000) [0.000000|65.278000] "Unit_Hertz" Vector__XXX
 SG_ ESP_Textanzeigen_03  : 32|5@1+ (1.000000,0.000000) [0.000000|31.000000] "" Vector__XXX
 SG_ ESP_Meldungen  : 37|3@1+ (1.000000,0.000000) [0.000000|7.000000] "" Vector__XXX
 SG_ ESP_Wegimp_VA  : 40|11@1+ (1.000000,0.000000) [0.000000|2047.000000] "" Vector__XXX
 SG_ ESP_Fehlerstatus_Wegimp  : 51|1@1+ (1.000000,0.000000) [0.000000|1.000000] "" Vector__XXX
 SG_ ESP_Wegimp_Ueberlauf  : 52|1@1+ (1.000000,0.000000) [0.000000|1.000000] "" Vector__XXX
 SG_ ESP_QBit_Wegimp_VA  : 53|1@1+ (1.000000,0.000000) [0.000000|1.000000] "" Vector__XXX
 SG_ ESP_HDC_FktLampe  : 54|1@1+ (1.000000,0.000000) [0.000000|1.000000] "" Vector__XXX
 SG_ ESP_Off_Lampe  : 55|1@1+ (1.000000,0.000000) [0.000000|1.000000] "" Airbag
 SG_ ESP_HDC_Regelgeschw  : 56|7@1+ (0.320000,0.000000) [0.320000|39.680000] "Unit_KiloMeterPerHour" Vector__XXX
 SG_ ESP_BKV_Warnung  : 63|1@1+ (1.000000,0.000000) [0.000000|1.000000] "" Vector__XXX

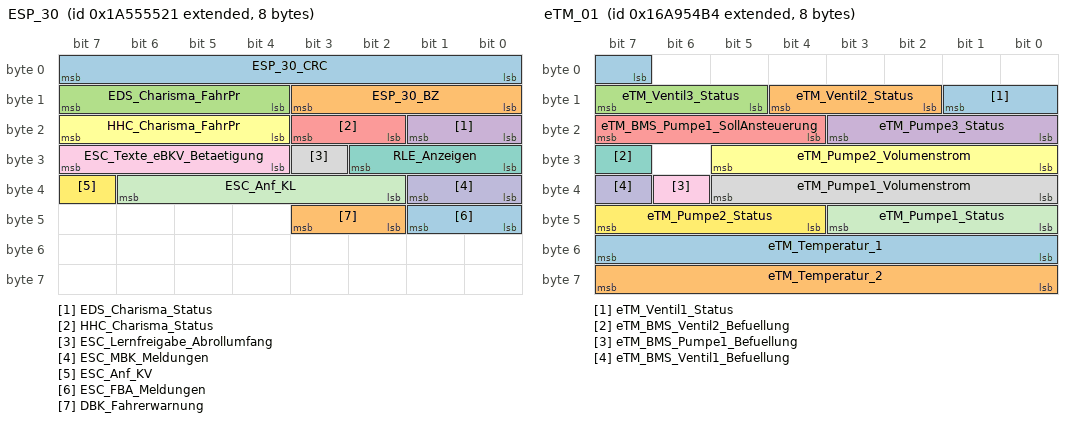
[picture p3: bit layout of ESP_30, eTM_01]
BO_ 2589283617 ESP_30: 8 ICAS1_Gateway
 SG_ ESP_30_CRC  : 0|8@1+ (1.000000,0.000000) [0.000000|255.000000] "" Vector__XXX
 SG_ ESP_30_BZ  : 8|4@1+ (1.000000,0.000000) [0.000000|15.000000] "" Vector__XXX
 SG_ EDS_Charisma_FahrPr  : 12|4@1+ (1.000000,0.000000) [0.000000|15.000000] "" Vector__XXX
 SG_ EDS_Charisma_Status  : 16|2@1+ (1.000000,0.000000) [0.000000|3.000000] "" Vector__XXX
 SG_ HHC_Charisma_Status  : 18|2@1+ (1.000000,0.000000) [0.000000|3.000000] "" Vector__XXX
 SG_ HHC_Charisma_FahrPr  : 20|4@1+ (1.000000,0.000000) [0.000000|15.000000] "" Vector__XXX
 SG_ RLE_Anzeigen  : 24|3@1+ (1.000000,0.000000) [0.000000|7.000000] "" Vector__XXX
 SG_ ESC_Lernfreigabe_Abrollumfang  : 27|1@1+ (1.000000,0.000000) [0.000000|1.000000] "" Vector__XXX
 SG_ ESC_Texte_eBKV_Betaetigung  : 28|4@1+ (1.000000,0.000000) [0.000000|15.000000] "" Vector__XXX
 SG_ ESC_MBK_Meldungen  : 32|2@1+ (1.000000,0.000000) [0.000000|3.000000] "" Vector__XXX
 SG_ ESC_Anf_KL  : 34|5@1+ (3.225806,0.000000) [0.000000|100.000000] "Unit_PerCent" Motor_BEV
 SG_ ESC_Anf_KV  : 39|1@1+ (1.000000,0.000000) [0.000000|1.000000] "" Motor_BEV
 SG_ ESC_FBA_Meldungen  : 40|2@1+ (1.000000,0.000000) [0.000000|3.000000] "" Vector__XXX
 SG_ DBK_Fahrerwarnung  : 42|2@1+ (1.000000,0.000000) [0.000000|3.000000] "" Vector__XXX

BO_ 2527679668 eTM_01: 8 Motor_BEV
 SG_ eTM_Ventil1_Status  : 7|3@1+ (1.000000,0.000000) [0.000000|7.000000] "" ICAS1_Gateway
 SG_ eTM_Ventil2_Status  : 10|3@1+ (1.000000,0.000000) [0.000000|7.000000] "" ICAS1_Gateway
 SG_ eTM_Ventil3_Status  : 13|3@1+ (1.000000,0.000000) [0.000000|7.000000] "" ICAS1_Gateway
 SG_ eTM_Pumpe3_Status  : 16|4@1+ (10.000000,0.000000) [0.000000|130.000000] "Unit_PerCent" ICAS1_Gateway
 SG_ eTM_BMS_Pumpe1_SollAnsteuerung  : 20|4@1+ (10.000000,0.000000) [0.000000|130.000000] "Unit_PerCent" ICAS1_Gateway
 SG_ eTM_Pumpe2_Volumenstrom  : 24|6@1+ (0.500000,0.000000) [0.000000|30.500000] "Unit_LiterPerMinut" ICAS1_Gateway LE1 LE2
 SG_ eTM_BMS_Ventil2_Befuellung  : 31|1@1+ (1.000000,0.000000) [0.000000|1.000000] "" ICAS1_Gateway
 SG_ eTM_Pumpe1_Volumenstrom  : 32|6@1+ (0.500000,0.000000) [0.000000|30.500000] "Unit_LiterPerMinut" ICAS1_Gateway LE1 LE2
 SG_ eTM_BMS_Pumpe1_Befuellung  : 38|1@1+ (1.000000,0.000000) [0.000000|1.000000] "" ICAS1_Gateway
 SG_ eTM_BMS_Ventil1_Befuellung  : 39|1@1+ (1.000000,0.000000) [0.000000|1.000000] "" ICAS1_Gateway
 SG_ eTM_Pumpe1_Status  : 40|4@1+ (10.000000,0.000000) [0.000000|130.000000] "Unit_PerCent" ICAS1_Gateway LE1 LE2
 SG_ eTM_Pumpe2_Status  : 44|4@1+ (10.000000,0.000000) [0.000000|130.000000] "Unit_PerCent" ICAS1_Gateway LE1 LE2
 SG_ eTM_Temperatur_1  : 48|8@1+ (0.750000,-40.000000) [-40.000000|149.750000] "Unit_DegreCelsi" ICAS1_Gateway LE1 LE2
 SG_ eTM_Temperatur_2  : 56|8@1+ (0.750000,-40.000000) [-40.000000|149.750000] "Unit_DegreCelsi" ICAS1_Gateway LE1 LE2

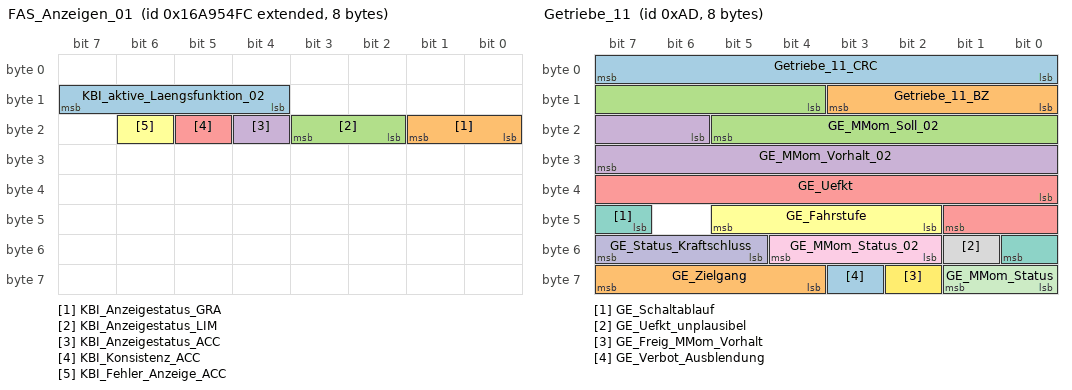
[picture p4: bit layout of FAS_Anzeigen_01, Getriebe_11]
BO_ 2527679740 FAS_Anzeigen_01: 8 ICAS1_KommunikationsServer
 SG_ KBI_aktive_Laengsfunktion_02  : 12|4@1+ (1.000000,0.000000) [0.000000|15.000000] "" Motor_BEV
 SG_ KBI_Anzeigestatus_GRA  : 16|2@1+ (1.000000,0.000000) [0.000000|3.000000] "" Motor_BEV
 SG_ KBI_Anzeigestatus_LIM  : 18|2@1+ (1.000000,0.000000) [0.000000|3.000000] "" Motor_BEV
 SG_ KBI_Anzeigestatus_ACC  : 20|1@1+ (1.000000,0.000000) [0.000000|1.000000] "" Vector__XXX
 SG_ KBI_Konsistenz_ACC  : 21|1@1+ (1.000000,0.000000) [0.000000|1.000000] "" Vector__XXX
 SG_ KBI_Fehler_Anzeige_ACC  : 22|1@1+ (1.000000,0.000000) [0.000000|1.000000] "" Vector__XXX

BO_ 2589283684 FoD_01: 8 ICAS1_Gateway
 SG_ GRA_FoD_Status  : 58|2@1+ (1.000000,0.000000) [0.000000|3.000000] "" Vector__XXX
 SG_ FoD_Transmission_Info  : 60|2@1+ (1.000000,0.000000) [0.000000|3.000000] "" Motor_BEV

BO_ 2549875574 FoD_MO_01_Req: 8 ICAS1_Gateway
 SG_ FoD_MO_01_Req_Data  : 0|64@1+ (1.000000,0.000000) [0.000000|18446744073709551616.000000] "" Motor_BEV

BO_ 2550006646 FoD_MO_01_Resp: 8 Motor_BEV
 SG_ FoD_MO_01_Resp_Data  : 0|64@1+ (1.000000,0.000000) [0.000000|18446744073709551616.000000] "" ICAS1_Gateway

BO_ 987 Gateway_72: 8 ICAS1_Gateway
 SG_ BCM_01_alt  : 0|1@1+ (1.000000,0.000000) [0.000000|1.000000] "" Airbag
 SG_ SMLS_01_alt  : 1|1@1+ (1.000000,0.000000) [0.000000|1.000000] "" Vector__XXX
 SG_ ZV_02_alt  : 2|1@1+ (1.000000,0.000000) [0.000000|1.000000] "" Vector__XXX
 SG_ Wischer_01_alt  : 3|1@1+ (1.000000,0.000000) [0.000000|1.000000] "" Vector__XXX
 SG_ Anhaenger_01_alt  : 4|1@1+ (1.000000,0.000000) [0.000000|1.000000] "" Airbag
 SG_ Klima_Sensor_02_alt  : 5|1@1+ (1.000000,0.000000) [0.000000|1.000000] "" Vector__XXX
 SG_ Verdeck_01_alt  : 6|1@1+ (1.000000,0.000000) [0.000000|1.000000] "" Vector__XXX
 SG_ Klima_11_alt  : 7|1@1+ (1.000000,0.000000) [0.000000|1.000000] "" Vector__XXX
 SG_ WFS_01_alt  : 8|1@1+ (1.000000,0.000000) [0.000000|1.000000] "" Vector__XXX
 SG_ Licht_Anf_01_alt  : 9|1@1+ (1.000000,0.000000) [0.000000|1.000000] "" Vector__XXX
 SG_ ZV_verriegelt_extern_soll  : 10|1@1+ (1.000000,0.000000) [0.000000|1.000000] "" Vector__XXX
 SG_ BH_Lichthupe  : 11|1@1+ (1.000000,0.000000) [0.000000|1.000000] "" Vector__XXX
 SG_ WFS_Klemmenfreigabe  : 12|1@1+ (1.000000,0.000000) [0.000000|1.000000] "" Vector__XXX
 SG_ ZV_Tankklappe_offen  : 13|1@1+ (1.000000,0.000000) [0.000000|1.000000] "" Vector__XXX
 SG_ AAG_Anhaenger_abgesteckt  : 14|1@1+ (1.000000,0.000000) [0.000000|1.000000] "" Vector__XXX
 SG_ BCM1_LDS_Stellung  : 15|3@1+ (1.000000,0.000000) [0.000000|7.000000] "" Vector__XXX
 SG_ VS_Verdeck_Anf  : 18|1@1+ (1.000000,0.000000) [0.000000|1.000000] "" Vector__XXX
 SG_ VS_VD_entriegelt  : 19|1@1+ (1.000000,0.000000) [0.000000|1.000000] "" Vector__XXX
 SG_ ZV_HFS_offen  : 20|1@1+ (1.000000,0.000000) [0.000000|1.000000] "" Vector__XXX
 SG_ ZV_HBFS_offen  : 21|1@1+ (1.000000,0.000000) [0.000000|1.000000] "" Vector__XXX
 SG_ VS_VD_offen_ver  : 22|1@1+ (1.000000,0.000000) [0.000000|1.000000] "" Vector__XXX
 SG_ VS_VD_zu_ver  : 23|1@1+ (1.000000,0.000000) [0.000000|1.000000] "" Vector__XXX
 SG_ ZV_BT_offen  : 24|1@1+ (1.000000,0.000000) [0.000000|1.000000] "" Vector__XXX
 SG_ BCM1_Rueckfahrlicht_Schalter  : 25|1@1+ (1.000000,0.000000) [0.000000|1.000000] "" Airbag Motor_BEV
 SG_ ZV_FT_offen  : 26|1@1+ (1.000000,0.000000) [0.000000|1.000000] "" Vector__XXX
 SG_ Wischer_vorne_aktiv  : 27|1@1+ (1.000000,0.000000) [0.000000|1.000000] "" Vector__XXX
 SG_ AAG_Anhaenger_erkannt  : 28|1@1+ (1.000000,0.000000) [0.000000|1.000000] "" Airbag
 SG_ BCM1_MH_Schalter  : 29|1@1+ (1.000000,0.000000) [0.000000|1.000000] "" Vector__XXX
 SG_ ZV_HD_offen  : 30|1@1+ (1.000000,0.000000) [0.000000|1.000000] "" Vector__XXX
 SG_ Waschen_vorne_aktiv  : 31|1@1+ (1.000000,0.000000) [0.000000|1.000000] "" Vector__XXX
 SG_ KL_Thermomanagement  : 32|2@1+ (1.000000,0.000000) [0.000000|3.000000] "" Vector__XXX
 SG_ WFS_Schluessel_Fahrberecht  : 34|4@1+ (1.000000,0.000000) [0.000000|15.000000] "" Vector__XXX
 SG_ BCM_Rueckfahrlicht_Anf  : 38|1@1+ (1.000000,0.000000) [0.000000|1.000000] "" Vector__XXX
 SG_ WWSs_01_alt  : 39|1@1+ (1.000000,0.000000) [0.000000|1.000000] "" Vector__XXX
 SG_ BCM_Tankklappensteller_Fehler  : 40|1@1+ (1.000000,0.000000) [0.000000|1.000000] "" Vector__XXX
 SG_ AAG_LED_aktiv  : 41|1@1+ (1.000000,0.000000) [0.000000|1.000000] "" Vector__XXX
 SG_ ZV_verriegelt_soll  : 42|2@1+ (1.000000,0.000000) [0.000000|3.000000] "" Vector__XXX
 SG_ ZV_Schluessel_Zugang  : 44|4@1+ (1.000000,0.000000) [0.000000|15.000000] "" Vector__XXX
 SG_ WFS_ID_Geb_autorisiert_in_Kl15  : 48|1@1+ (1.000000,0.000000) [0.000000|1.000000] "" Vector__XXX
 SG_ BH_Fernlicht  : 49|1@1+ (1.000000,0.000000) [0.000000|1.000000] "" Vector__XXX
 SG_ BH_Blinker_li  : 50|1@1+ (1.000000,0.000000) [0.000000|1.000000] "" Vector__XXX
 SG_ BH_Blinker_re  : 51|1@1+ (1.000000,0.000000) [0.000000|1.000000] "" Vector__XXX
 SG_ BCM1_OBD_FStatus_ATemp  : 52|4@1+ (1.000000,0.000000) [0.000000|15.000000] "" Vector__XXX
 SG_ BCM1_Aussen_Temp_ungef  : 56|8@1+ (0.500000,-50.000000) [-50.000000|76.000000] "Unit_DegreCelsi" Vector__XXX

BO_ 173 Getriebe_11: 8 Motor_BEV
 SG_ Getriebe_11_CRC  : 0|8@1+ (1.000000,0.000000) [0.000000|255.000000] "" ICAS1_Gateway
 SG_ Getriebe_11_BZ  : 8|4@1+ (1.000000,0.000000) [0.000000|15.000000] "" ICAS1_Gateway
 SG_ GE_MMom_Soll_02  : 12|10@1+ (1.000000,-509.000000) [-509.000000|509.000000] "" ICAS1_Gateway
 SG_ GE_MMom_Vorhalt_02  : 22|10@1+ (1.000000,-509.000000) [-509.000000|509.000000] "" ICAS1_Gateway
 SG_ GE_Uefkt  : 32|10@1+ (0.100000,0.000000) [0.000000|102.200000] "" ICAS1_Gateway
 SG_ GE_Fahrstufe  : 42|4@1+ (1.000000,0.000000) [0.000000|15.000000] "" ICAS1_Gateway
 SG_ GE_Schaltablauf  : 47|2@1+ (1.000000,0.000000) [0.000000|3.000000] "" ICAS1_Gateway
 SG_ GE_Uefkt_unplausibel  : 49|1@1+ (1.000000,0.000000) [0.000000|1.000000] "" ICAS1_Gateway
 SG_ GE_MMom_Status_02  : 50|3@1+ (1.000000,0.000000) [0.000000|7.000000] "" ICAS1_Gateway
 SG_ GE_Status_Kraftschluss  : 53|3@1+ (1.000000,0.000000) [0.000000|7.000000] "" ICAS1_Gateway
 SG_ GE_MMom_Status  : 56|2@1+ (1.000000,0.000000) [0.000000|3.000000] "" ICAS1_Gateway
 SG_ GE_Freig_MMom_Vorhalt  : 58|1@1+ (1.000000,0.000000) [0.000000|1.000000] "" ICAS1_Gateway
 SG_ GE_Verbot_Ausblendung  : 59|1@1+ (1.000000,0.000000) [0.000000|1.000000] "" ICAS1_Gateway
 SG_ GE_Zielgang  : 60|4@1+ (1.000000,0.000000) [0.000000|15.000000] "" ICAS1_Gateway

BU_:  Airbag BAP_Tester ICAS1_Gateway ICAS1_KommunikationsServer LE1 LE2 Motor_BEV Schaltbetaetigung

BO_ 252 ESC_51: 48 ICAS1_Gateway
 SG_ ESC_51_CRC  : 0|8@1+ (1.000000,0.000000) [0.000000|255.000000] "" Motor_BEV
 SG_ ESC_51_BZ  : 8|4@1+ (1.000000,0.000000) [0.000000|15.000000] "" Motor_BEV
 SG_ ESC_aktBr_Modus  : 12|2@1+ (1.000000,0.000000) [0.000000|3.000000] "" Vector__XXX
 SG_ ESC_Blending_Solldruck  : 14|10@1+ (0.250000,0.000000) [0.000000|250.000000] "Unit_Bar" Vector__XXX
 SG_ ESC_aktBr_Volumenstrom  : 24|16@1+ (0.007812,-252.000000) [-252.000000|252.000000] "Unit_MilliLiterPerSec" Vector__XXX
 SG_ ESC_EBKV_Kraftblending_Modus  : 40|2@1+ (1.000000,0.000000) [0.000000|3.000000] "" Vector__XXX
 SG_ ESC_Bremsdruck_Modell  : 42|10@1+ (0.250000,0.000000) [0.000000|250.000000] "Unit_Bar" Motor_BEV
 SG_ ESC_Bremsdruck_02  : 52|10@1+ (0.300000,-30.000000) [-30.000000|276.600000] "Unit_Bar" Vector__XXX
 SG_ ESC_QBit_Bremsdruck_02  : 62|1@1+ (1.000000,0.000000) [0.000000|1.000000] "" Vector__XXX
 SG_ ESP_HL_Radgeschw_02  : 64|16@1+ (0.007500,0.000000) [0.000000|491.490000] "Unit_KiloMeterPerHour" Airbag LE1 LE2 Motor_BEV
 SG_ ESP_HR_Radgeschw_02  : 80|16@1+ (0.007500,0.000000) [0.000000|491.490000] "Unit_KiloMeterPerHour" Airbag LE1 LE2 Motor_BEV
 SG_ ESP_VL_Radgeschw_02  : 96|16@1+ (0.007500,0.000000) [0.000000|491.490000] "Unit_KiloMeterPerHour" Airbag LE1 LE2 Motor_BEV
 SG_ ESP_VR_Radgeschw_02  : 112|16@1+ (0.007500,0.000000) [0.000000|491.490000] "Unit_KiloMeterPerHour" Airbag LE1 LE2 Motor_BEV
 SG_ ESP_FZR_uebersteuern  : 128|8@1+ (0.004000,0.000000) [0.000000|1.000000] "" Vector__XXX
 SG_ ESP_FZR_untersteuern  : 136|8@1+ (0.004000,0.000000) [0.000000|1.000000] "" Vector__XXX
 SG_ ESC_Anf_Mindestreku  : 144|1@1+ (1.000000,0.000000) [0.000000|1.000000] "" Motor_BEV
 SG_ ESC_GMV_aktiv  : 145|3@1+ (1.000000,0.000000) [0.000000|7.000000] "" Vector__XXX
 SG_ ESC_GMV_nicht_verfuegbar  : 148|1@1+ (1.000000,0.000000) [0.000000|1.000000] "" Vector__XXX
 SG_ ESC_Status_vRef_Stuetzeingriff  : 149|1@1+ (1.000000,0.000000) [0.000000|1.000000] "" Motor_BEV
 SG_ FDR_Allradverteilung_aktiv  : 150|1@1+ (1.000000,0.000000) [0.000000|1.000000] "" Vector__XXX
 SG_ FDR_Anf_Allradbetrieb  : 151|1@1+ (1.000000,0.000000) [0.000000|1.000000] "" Vector__XXX
 SG_ ESP_HL_Bremsmoment  : 152|8@1+ (20.000000,0.000000) [0.000000|5060.000000] "Unit_NewtoMeter" Motor_BEV
 SG_ ESP_HR_Bremsmoment  : 160|8@1+ (20.000000,0.000000) [0.000000|5060.000000] "Unit_NewtoMeter" Motor_BEV
 SG_ ESP_VR_Bremsmoment  : 168|8@1+ (40.000000,0.000000) [0.000000|10120.000000] "Unit_NewtoMeter" Motor_BEV
 SG_ ESP_VL_Bremsmoment  : 176|8@1+ (40.000000,0.000000) [0.000000|10120.000000] "Unit_NewtoMeter" Motor_BEV
 SG_ ESP_FDR_uebersteuern  : 184|8@1+ (0.004000,0.000000) [0.000000|1.000000] "" Motor_BEV
 SG_ ESP_FDR_untersteuern  : 192|8@1+ (0.004000,0.000000) [0.000000|1.000000] "" Motor_BEV
 SG_ TSMomBegrenzung  : 268|12@1+ (3.000000,-12279.000000) [-12279.000000|0.000000] "" Motor_BEV
 SG_ ESC_Allrad_Anteil_max_sek  : 280|9@1+ (0.200000,0.000000) [0.000000|100.000000] "Unit_PerCent" Motor_BEV
 SG_ ESC_Allrad_Anteil_min_sek  : 289|9@1+ (0.200000,0.000000) [0.000000|100.000000] "Unit_PerCent" Motor_BEV
 SG_ ESC_Status_Eingriff  : 298|2@1+ (1.000000,0.000000) [0.000000|3.000000] "" Motor_BEV
 SG_ ESC_Status_Eingriff_sek  : 300|2@1+ (1.000000,0.000000) [0.000000|3.000000] "" Motor_BEV
 SG_ ESC_MomRad_Eingriff  : 302|13@1+ (3.000000,-12279.000000) [-12279.000000|12279.000000] "Unit_None" Motor_BEV
 SG_ ESC_MomRad_Eingriff_sek  : 315|13@1+ (3.000000,-12279.000000) [-12279.000000|12279.000000] "Unit_None" Motor_BEV
 SG_ ESC_Achsdrehzahl_Max  : 328|14@1+ (0.400000,-800.000000) [-800.000000|5752.400000] "Unit_MinutInver" Motor_BEV
 SG_ ESC_Achsdrehzahl_Min  : 342|14@1+ (0.400000,-800.000000) [-800.000000|5752.400000] "Unit_MinutInver" Motor_BEV
 SG_ ESC_Achsdrehzahl_Max_sek  : 356|14@1+ (0.400000,-800.000000) [-800.000000|5752.400000] "Unit_MinutInver" Motor_BEV
 SG_ ESC_Achsdrehzahl_Min_sek  : 370|14@1+ (0.400000,-800.000000) [-800.000000|5752.400000] "Unit_MinutInver" Motor_BEV

BO_ 2463978647 ESC_52: 16 ICAS1_Gateway
 SG_ ESP_ACC_LDE  : 12|1@1+ (1.000000,0.000000) [0.000000|1.000000] "" Vector__XXX
 SG_ ESP_Allrad_Antrieb  : 13|1@1+ (1.000000,0.000000) [0.000000|1.000000] "" Vector__XXX
 SG_ ESP_Codierung_ADS  : 14|2@1+ (1.000000,0.000000) [0.000000|3.000000] "" Vector__XXX
 SG_ ESP_RTA_HL  : 16|8@1+ (0.048828,-6.201170) [-6.201170|6.152346] "Unit_PerCent" Motor_BEV
 SG_ ESP_RTA_HR  : 24|8@1+ (0.048828,-6.201170) [-6.201170|6.152346] "Unit_PerCent" Motor_BEV
 SG_ ESP_RTA_VR  : 32|8@1+ (0.048828,-6.201170) [-6.201170|6.152346] "Unit_PerCent" Motor_BEV
 SG_ OBD_Fehler_Radsensor_HL  : 40|4@1+ (1.000000,0.000000) [0.000000|15.000000] "" Motor_BEV
 SG_ OBD_Fehler_Radsensor_HR  : 44|4@1+ (1.000000,0.000000) [0.000000|15.000000] "" Motor_BEV
 SG_ OBD_Fehler_Radsensor_VL  : 48|4@1+ (1.000000,0.000000) [0.000000|15.000000] "" Motor_BEV
 SG_ OBD_Fehler_Radsensor_VR  : 52|4@1+ (1.000000,0.000000) [0.000000|15.000000] "" Motor_BEV
 SG_ ESP_Qualifizierung_Antriebsart  : 56|1@1+ (1.000000,0.000000) [0.000000|1.000000] "" Vector__XXX
 SG_ ESP_Offroad_Modus  : 57|1@1+ (1.000000,0.000000) [0.000000|1.000000] "" Vector__XXX
 SG_ ESP_MKB_ausloesbar  : 58|1@1+ (1.000000,0.000000) [0.000000|1.000000] "" Vector__XXX
 SG_ ESP_Stat_FallBack_eBKV  : 59|1@1+ (1.000000,0.000000) [0.000000|1.000000] "" Vector__XXX
 SG_ ESP_CM_Variante  : 60|1@1+ (1.000000,0.000000) [0.000000|1.000000] "" Vector__XXX
 SG_ ESP_OBD_Status  : 61|1@1+ (1.000000,0.000000) [0.000000|1.000000] "" Motor_BEV
 SG_ ESP_Rollenmodus_Deaktivieren  : 62|1@1+ (1.000000,0.000000) [0.000000|1.000000] "" Motor_BEV
 SG_ ESP_nachtr_Stopp_Anf  : 63|1@1+ (1.000000,0.000000) [0.000000|1.000000] "" Vector__XXX

BO_ 2527679683 ESC_ASM_01: 8 ICAS1_Gateway
 SG_ ESC_ASM_Ereignis  : 0|8@1+ (1.000000,0.000000) [1.000000|254.000000] "Unit_None" Airbag
 SG_ ESC_ASM_Zeitstempel  : 8|8@1+ (0.080000,0.000000) [0.000000|20.320000] "Unit_Secon" Airbag
 SG_ ESC_ASM_Data_1  : 16|8@1+ (1.000000,0.000000) [0.000000|255.000000] "" Airbag
 SG_ ESC_ASM_Data_2  : 24|8@1+ (1.000000,0.000000) [0.000000|255.000000] "" Airbag
 SG_ ESC_ASM_Data_3  : 32|8@1+ (1.000000,0.000000) [0.000000|255.000000] "" Airbag
 SG_ ESC_ASM_Data_4  : 40|8@1+ (1.000000,0.000000) [0.000000|255.000000] "" Airbag
 SG_ ESC_ASM_Data_5  : 48|8@1+ (1.000000,0.000000) [0.000000|255.000000] "" Airbag
 SG_ ESC_ASM_Data_6  : 56|8@1+ (1.000000,0.000000) [0.000000|255.000000] "" Airbag

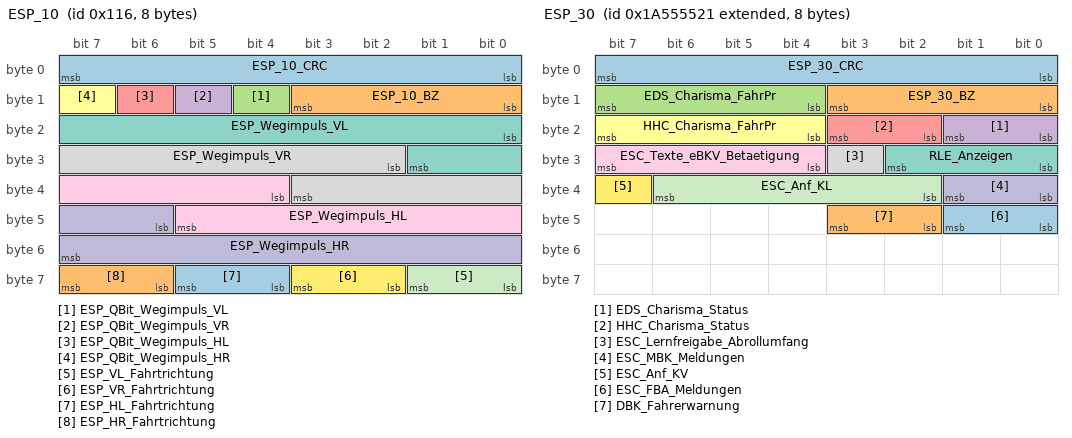
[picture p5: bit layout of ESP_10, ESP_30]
BO_ 278 ESP_10: 8 ICAS1_Gateway
 SG_ ESP_10_CRC  : 0|8@1+ (1.000000,0.000000) [0.000000|255.000000] "" Vector__XXX
 SG_ ESP_10_BZ  : 8|4@1+ (1.000000,0.000000) [0.000000|15.000000] "" Vector__XXX
 SG_ ESP_QBit_Wegimpuls_VL  : 12|1@1+ (1.000000,0.000000) [0.000000|1.000000] "" Motor_BEV
 SG_ ESP_QBit_Wegimpuls_VR  : 13|1@1+ (1.000000,0.000000) [0.000000|1.000000] "" Motor_BEV
 SG_ ESP_QBit_Wegimpuls_HL  : 14|1@1+ (1.000000,0.000000) [0.000000|1.000000] "" Motor_BEV
 SG_ ESP_QBit_Wegimpuls_HR  : 15|1@1+ (1.000000,0.000000) [0.000000|1.000000] "" Motor_BEV
 SG_ ESP_Wegimpuls_VL  : 16|10@1+ (1.000000,0.000000) [0.000000|1000.000000] "" Motor_BEV
 SG_ ESP_Wegimpuls_VR  : 26|10@1+ (1.000000,0.000000) [0.000000|1000.000000] "" Motor_BEV
 SG_ ESP_Wegimpuls_HL  : 36|10@1+ (1.000000,0.000000) [0.000000|1000.000000] "" Motor_BEV
 SG_ ESP_Wegimpuls_HR  : 46|10@1+ (1.000000,0.000000) [0.000000|1000.000000] "" Motor_BEV
 SG_ ESP_VL_Fahrtrichtung  : 56|2@1+ (1.000000,0.000000) [0.000000|3.000000] "" Motor_BEV
 SG_ ESP_VR_Fahrtrichtung  : 58|2@1+ (1.000000,0.000000) [0.000000|3.000000] "" Motor_BEV
 SG_ ESP_HL_Fahrtrichtung  : 60|2@1+ (1.000000,0.000000) [0.000000|3.000000] "" Motor_BEV
 SG_ ESP_HR_Fahrtrichtung  : 62|2@1+ (1.000000,0.000000) [0.000000|3.000000] "" Motor_BEV

BO_ 1629 ESP_20: 8 ICAS1_Gateway
 SG_ ESP_20_CRC  : 0|8@1+ (1.000000,0.000000) [0.000000|255.000000] "" Vector__XXX
 SG_ ESP_20_BZ  : 8|4@1+ (1.000000,0.000000) [0.000000|15.000000] "" Vector__XXX
 SG_ BR_Systemart  : 12|2@1+ (1.000000,0.000000) [0.000000|3.000000] "" Vector__XXX
 SG_ ESP_SpannungsAnf_02  : 14|2@1+ (1.000000,0.000000) [0.000000|3.000000] "" Vector__XXX
 SG_ ESP_Zaehnezahl  : 16|8@1+ (1.000000,0.000000) [0.000000|255.000000] "" Vector__XXX
 SG_ ESP_Charisma_FahrPr  : 24|4@1+ (1.000000,0.000000) [0.000000|15.000000] "" Vector__XXX
 SG_ ESP_Charisma_Status  : 28|2@1+ (1.000000,0.000000) [0.000000|3.000000] "" Vector__XXX
 SG_ ESP_Wiederstart_Anz_01  : 30|1@1+ (1.000000,0.000000) [0.000000|1.000000] "" Vector__XXX
 SG_ ESP_Wiederstart_Anz_02  : 31|1@1+ (1.000000,0.000000) [0.000000|1.000000] "" Vector__XXX
 SG_ ESP_Wiederstart_Anz_03  : 32|1@1+ (1.000000,0.000000) [0.000000|1.000000] "" Vector__XXX
 SG_ ESP_Wiederstart_Anz_04  : 33|1@1+ (1.000000,0.000000) [0.000000|1.000000] "" Vector__XXX
 SG_ ESP_Stoppverbot_Anz_01  : 34|1@1+ (1.000000,0.000000) [0.000000|1.000000] "" Vector__XXX
 SG_ ESP_Stoppverbot_Anz_02  : 35|1@1+ (1.000000,0.000000) [0.000000|1.000000] "" Vector__XXX
 SG_ ESP_Stoppverbot_Anz_03  : 36|1@1+ (1.000000,0.000000) [0.000000|1.000000] "" Vector__XXX
 SG_ ESP_Stoppverbot_Anz_04  : 37|1@1+ (1.000000,0.000000) [0.000000|1.000000] "" Vector__XXX
 SG_ ESP_Stoppverbot_Anz_05  : 38|1@1+ (1.000000,0.000000) [0.000000|1.000000] "" Vector__XXX
 SG_ ESP_Stoppverbot_Anz_06  : 39|1@1+ (1.000000,0.000000) [0.000000|1.000000] "" Vector__XXX
 SG_ ESP_Stoppverbot_Anz_07  : 40|1@1+ (1.000000,0.000000) [0.000000|1.000000] "" Vector__XXX
 SG_ ESP_Stoppverbot_Anz_Std  : 41|1@1+ (1.000000,0.000000) [0.000000|1.000000] "" Vector__XXX
 SG_ ESP_Dachrelingsensor  : 42|2@1+ (1.000000,0.000000) [0.000000|3.000000] "" Vector__XXX
 SG_ ESP_Stoppverbot_Anz_08  : 44|1@1+ (1.000000,0.000000) [0.000000|1.000000] "" Vector__XXX
 SG_ HDC_Charisma_FahrPr  : 45|4@1+ (1.000000,0.000000) [0.000000|15.000000] "" Vector__XXX
 SG_ HDC_Charisma_Status  : 49|2@1+ (1.000000,0.000000) [0.000000|3.000000] "" Vector__XXX
 SG_ BR_QBit_Reifenumfang  : 51|1@1+ (1.000000,0.000000) [0.000000|1.000000] "" LE1 LE2
 SG_ BR_Reifenumfang  : 52|12@1+ (1.000000,0.000000) [0.000000|4095.000000] "Unit_MilliMeter" LE1 LE2

BO_ 253 ESP_21: 8 ICAS1_Gateway
 SG_ ESP_21_CRC  : 0|8@1+ (1.000000,0.000000) [0.000000|255.000000] "" Airbag LE1 LE2 Motor_BEV
 SG_ ESP_21_BZ  : 8|4@1+ (1.000000,0.000000) [0.000000|15.000000] "" Airbag LE1 LE2 Motor_BEV
 SG_ BR_Eingriffsmoment  : 12|10@1+ (1.000000,-509.000000) [-509.000000|509.000000] "" Vector__XXX
 SG_ ESP_PLA_Bremseingriff  : 22|1@1+ (1.000000,0.000000) [0.000000|1.000000] "" Vector__XXX
 SG_ ESP_Diagnose  : 23|1@1+ (1.000000,0.000000) [0.000000|1.000000] "" Vector__XXX
 SG_ ESC_Reku_Freigabe  : 24|1@1+ (1.000000,0.000000) [0.000000|1.000000] "" Motor_BEV
 SG_ ESC_v_Signal_Qualifier_High_Low  : 25|3@1+ (1.000000,0.000000) [0.000000|7.000000] "" Airbag
 SG_ ESP_Vorsteuerung  : 28|1@1+ (1.000000,0.000000) [0.000000|1.000000] "" Motor_BEV
 SG_ ESP_AWV3_Brems_aktiv  : 29|1@1+ (1.000000,0.000000) [0.000000|1.000000] "" Vector__XXX
 SG_ OBD_Schlechtweg  : 30|1@1+ (1.000000,0.000000) [0.000000|1.000000] "" Vector__XXX
 SG_ OBD_QBit_Schlechtweg  : 31|1@1+ (1.000000,0.000000) [0.000000|1.000000] "" Vector__XXX
 SG_ ESP_v_Signal  : 32|16@1+ (0.010000,0.000000) [0.000000|655.320000] "Unit_KiloMeterPerHour" Airbag LE1 LE2 Motor_BEV
 SG_ ASR_Tastung_passiv  : 48|1@1+ (1.000000,0.000000) [0.000000|1.000000] "" Airbag Motor_BEV
 SG_ ESP_Tastung_passiv  : 49|1@1+ (1.000000,0.000000) [0.000000|1.000000] "" Airbag Motor_BEV
 SG_ ESP_Systemstatus  : 50|1@1+ (1.000000,0.000000) [0.000000|1.000000] "" Motor_BEV
 SG_ ASR_Schalteingriff  : 51|2@1+ (1.000000,0.000000) [0.000000|3.000000] "" Vector__XXX
 SG_ ESP_Haltebestaetigung  : 53|1@1+ (1.000000,0.000000) [0.000000|1.000000] "" Vector__XXX
 SG_ ESP_MKB_Abbruch_Geschw  : 54|1@1+ (1.000000,0.000000) [0.000000|1.000000] "" Vector__XXX
 SG_ ESP_QBit_v_Signal  : 55|1@1+ (1.000000,0.000000) [0.000000|1.000000] "" LE1 LE2 Motor_BEV
 SG_ ABS_Bremsung  : 56|1@1+ (1.000000,0.000000) [0.000000|1.000000] "" Airbag Motor_BEV
 SG_ ASR_Anf  : 57|1@1+ (1.000000,0.000000) [0.000000|1.000000] "" Vector__XXX
 SG_ MSR_Anf  : 58|1@1+ (1.000000,0.000000) [0.000000|1.000000] "" Vector__XXX
 SG_ EBV_Eingriff  : 59|1@1+ (1.000000,0.000000) [0.000000|1.000000] "" Vector__XXX
 SG_ EDS_Eingriff  : 60|1@1+ (1.000000,0.000000) [0.000000|1.000000] "" Motor_BEV
 SG_ ESP_Eingriff  : 61|1@1+ (1.000000,0.000000) [0.000000|1.000000] "" Airbag Motor_BEV
 SG_ ESP_ASP  : 62|1@1+ (1.000000,0.000000) [0.000000|1.000000] "" Vector__XXX
 SG_ ESP_Anhaltevorgang_ACC_aktiv  : 63|1@1+ (1.000000,0.000000) [0.000000|1.000000] "" Vector__XXX

BO_ 795 ESP_24: 8 ICAS1_Gateway
 SG_ ESP_24_CRC  : 0|8@1+ (1.000000,0.000000) [0.000000|255.000000] "" Vector__XXX
 SG_ ESP_24_BZ  : 8|4@1+ (1.000000,0.000000) [0.000000|15.000000] "" Vector__XXX
 SG_ ESP_Lampe  : 12|1@1+ (1.000000,0.000000) [0.000000|1.000000] "" Motor_BEV
 SG_ ABS_Lampe  : 13|1@1+ (1.000000,0.000000) [0.000000|1.000000] "" Vector__XXX
 SG_ BK_Lampe_02  : 14|2@1+ (1.000000,0.000000) [0.000000|3.000000] "" Vector__XXX
 SG_ TC_Lampe  : 16|1@1+ (1.000000,0.000000) [0.000000|1.000000] "" Vector__XXX
 SG_ ESP_m_Raddrehz  : 17|15@1+ (0.002000,0.000000) [0.000000|65.278000] "Unit_Hertz" Vector__XXX
 SG_ ESP_Textanzeigen_03  : 32|5@1+ (1.000000,0.000000) [0.000000|31.000000] "" Vector__XXX
 SG_ ESP_Meldungen  : 37|3@1+ (1.000000,0.000000) [0.000000|7.000000] "" Vector__XXX
 SG_ ESP_Wegimp_VA  : 40|11@1+ (1.000000,0.000000) [0.000000|2047.000000] "" Vector__XXX
 SG_ ESP_Fehlerstatus_Wegimp  : 51|1@1+ (1.000000,0.000000) [0.000000|1.000000] "" Vector__XXX
 SG_ ESP_Wegimp_Ueberlauf  : 52|1@1+ (1.000000,0.000000) [0.000000|1.000000] "" Vector__XXX
 SG_ ESP_QBit_Wegimp_VA  : 53|1@1+ (1.000000,0.000000) [0.000000|1.000000] "" Vector__XXX
 SG_ ESP_HDC_FktLampe  : 54|1@1+ (1.000000,0.000000) [0.000000|1.000000] "" Vector__XXX
 SG_ ESP_Off_Lampe  : 55|1@1+ (1.000000,0.000000) [0.000000|1.000000] "" Airbag
 SG_ ESP_HDC_Regelgeschw  : 56|7@1+ (0.320000,0.000000) [0.320000|39.680000] "Unit_KiloMeterPerHour" Vector__XXX
 SG_ ESP_BKV_Warnung  : 63|1@1+ (1.000000,0.000000) [0.000000|1.000000] "" Vector__XXX

BO_ 2589283617 ESP_30: 8 ICAS1_Gateway
 SG_ ESP_30_CRC  : 0|8@1+ (1.000000,0.000000) [0.000000|255.000000] "" Vector__XXX
 SG_ ESP_30_BZ  : 8|4@1+ (1.000000,0.000000) [0.000000|15.000000] "" Vector__XXX
 SG_ EDS_Charisma_FahrPr  : 12|4@1+ (1.000000,0.000000) [0.000000|15.000000] "" Vector__XXX
 SG_ EDS_Charisma_Status  : 16|2@1+ (1.000000,0.000000) [0.000000|3.000000] "" Vector__XXX
 SG_ HHC_Charisma_Status  : 18|2@1+ (1.000000,0.000000) [0.000000|3.000000] "" Vector__XXX
 SG_ HHC_Charisma_FahrPr  : 20|4@1+ (1.000000,0.000000) [0.000000|15.000000] "" Vector__XXX
 SG_ RLE_Anzeigen  : 24|3@1+ (1.000000,0.000000) [0.000000|7.000000] "" Vector__XXX
 SG_ ESC_Lernfreigabe_Abrollumfang  : 27|1@1+ (1.000000,0.000000) [0.000000|1.000000] "" Vector__XXX
 SG_ ESC_Texte_eBKV_Betaetigung  : 28|4@1+ (1.000000,0.000000) [0.000000|15.000000] "" Vector__XXX
 SG_ ESC_MBK_Meldungen  : 32|2@1+ (1.000000,0.000000) [0.000000|3.000000] "" Vector__XXX
 SG_ ESC_Anf_KL  : 34|5@1+ (3.225806,0.000000) [0.000000|100.000000] "Unit_PerCent" Motor_BEV
 SG_ ESC_Anf_KV  : 39|1@1+ (1.000000,0.000000) [0.000000|1.000000] "" Motor_BEV
 SG_ ESC_FBA_Meldungen  : 40|2@1+ (1.000000,0.000000) [0.000000|3.000000] "" Vector__XXX
 SG_ DBK_Fahrerwarnung  : 42|2@1+ (1.000000,0.000000) [0.000000|3.000000] "" Vector__XXX

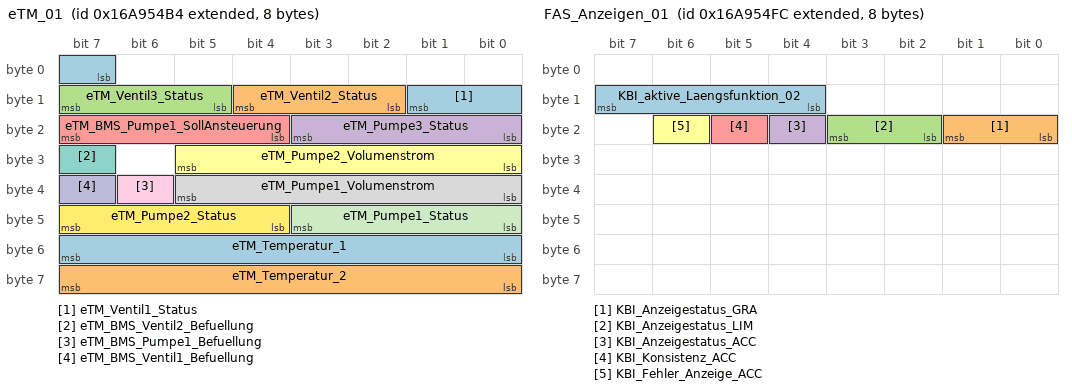
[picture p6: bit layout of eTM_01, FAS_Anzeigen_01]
BO_ 2527679668 eTM_01: 8 Motor_BEV
 SG_ eTM_Ventil1_Status  : 7|3@1+ (1.000000,0.000000) [0.000000|7.000000] "" ICAS1_Gateway
 SG_ eTM_Ventil2_Status  : 10|3@1+ (1.000000,0.000000) [0.000000|7.000000] "" ICAS1_Gateway
 SG_ eTM_Ventil3_Status  : 13|3@1+ (1.000000,0.000000) [0.000000|7.000000] "" ICAS1_Gateway
 SG_ eTM_Pumpe3_Status  : 16|4@1+ (10.000000,0.000000) [0.000000|130.000000] "Unit_PerCent" ICAS1_Gateway
 SG_ eTM_BMS_Pumpe1_SollAnsteuerung  : 20|4@1+ (10.000000,0.000000) [0.000000|130.000000] "Unit_PerCent" ICAS1_Gateway
 SG_ eTM_Pumpe2_Volumenstrom  : 24|6@1+ (0.500000,0.000000) [0.000000|30.500000] "Unit_LiterPerMinut" ICAS1_Gateway LE1 LE2
 SG_ eTM_BMS_Ventil2_Befuellung  : 31|1@1+ (1.000000,0.000000) [0.000000|1.000000] "" ICAS1_Gateway
 SG_ eTM_Pumpe1_Volumenstrom  : 32|6@1+ (0.500000,0.000000) [0.000000|30.500000] "Unit_LiterPerMinut" ICAS1_Gateway LE1 LE2
 SG_ eTM_BMS_Pumpe1_Befuellung  : 38|1@1+ (1.000000,0.000000) [0.000000|1.000000] "" ICAS1_Gateway
 SG_ eTM_BMS_Ventil1_Befuellung  : 39|1@1+ (1.000000,0.000000) [0.000000|1.000000] "" ICAS1_Gateway
 SG_ eTM_Pumpe1_Status  : 40|4@1+ (10.000000,0.000000) [0.000000|130.000000] "Unit_PerCent" ICAS1_Gateway LE1 LE2
 SG_ eTM_Pumpe2_Status  : 44|4@1+ (10.000000,0.000000) [0.000000|130.000000] "Unit_PerCent" ICAS1_Gateway LE1 LE2
 SG_ eTM_Temperatur_1  : 48|8@1+ (0.750000,-40.000000) [-40.000000|149.750000] "Unit_DegreCelsi" ICAS1_Gateway LE1 LE2
 SG_ eTM_Temperatur_2  : 56|8@1+ (0.750000,-40.000000) [-40.000000|149.750000] "Unit_DegreCelsi" ICAS1_Gateway LE1 LE2

BO_ 2527679740 FAS_Anzeigen_01: 8 ICAS1_KommunikationsServer
 SG_ KBI_aktive_Laengsfunktion_02  : 12|4@1+ (1.000000,0.000000) [0.000000|15.000000] "" Motor_BEV
 SG_ KBI_Anzeigestatus_GRA  : 16|2@1+ (1.000000,0.000000) [0.000000|3.000000] "" Motor_BEV
 SG_ KBI_Anzeigestatus_LIM  : 18|2@1+ (1.000000,0.000000) [0.000000|3.000000] "" Motor_BEV
 SG_ KBI_Anzeigestatus_ACC  : 20|1@1+ (1.000000,0.000000) [0.000000|1.000000] "" Vector__XXX
 SG_ KBI_Konsistenz_ACC  : 21|1@1+ (1.000000,0.000000) [0.000000|1.000000] "" Vector__XXX
 SG_ KBI_Fehler_Anzeige_ACC  : 22|1@1+ (1.000000,0.000000) [0.000000|1.000000] "" Vector__XXX

BO_ 2589283684 FoD_01: 8 ICAS1_Gateway
 SG_ GRA_FoD_Status  : 58|2@1+ (1.000000,0.000000) [0.000000|3.000000] "" Vector__XXX
 SG_ FoD_Transmission_Info  : 60|2@1+ (1.000000,0.000000) [0.000000|3.000000] "" Motor_BEV

BO_ 2549875574 FoD_MO_01_Req: 8 ICAS1_Gateway
 SG_ FoD_MO_01_Req_Data  : 0|64@1+ (1.000000,0.000000) [0.000000|18446744073709551616.000000] "" Motor_BEV

BO_ 2550006646 FoD_MO_01_Resp: 8 Motor_BEV
 SG_ FoD_MO_01_Resp_Data  : 0|64@1+ (1.000000,0.000000) [0.000000|18446744073709551616.000000] "" ICAS1_Gateway

BO_ 987 Gateway_72: 8 ICAS1_Gateway
 SG_ BCM_01_alt  : 0|1@1+ (1.000000,0.000000) [0.000000|1.000000] "" Airbag
 SG_ SMLS_01_alt  : 1|1@1+ (1.000000,0.000000) [0.000000|1.000000] "" Vector__XXX
 SG_ ZV_02_alt  : 2|1@1+ (1.000000,0.000000) [0.000000|1.000000] "" Vector__XXX
 SG_ Wischer_01_alt  : 3|1@1+ (1.000000,0.000000) [0.000000|1.000000] "" Vector__XXX
 SG_ Anhaenger_01_alt  : 4|1@1+ (1.000000,0.000000) [0.000000|1.000000] "" Airbag
 SG_ Klima_Sensor_02_alt  : 5|1@1+ (1.000000,0.000000) [0.000000|1.000000] "" Vector__XXX
 SG_ Verdeck_01_alt  : 6|1@1+ (1.000000,0.000000) [0.000000|1.000000] "" Vector__XXX
 SG_ Klima_11_alt  : 7|1@1+ (1.000000,0.000000) [0.000000|1.000000] "" Vector__XXX
 SG_ WFS_01_alt  : 8|1@1+ (1.000000,0.000000) [0.000000|1.000000] "" Vector__XXX
 SG_ Licht_Anf_01_alt  : 9|1@1+ (1.000000,0.000000) [0.000000|1.000000] "" Vector__XXX
 SG_ ZV_verriegelt_extern_soll  : 10|1@1+ (1.000000,0.000000) [0.000000|1.000000] "" Vector__XXX
 SG_ BH_Lichthupe  : 11|1@1+ (1.000000,0.000000) [0.000000|1.000000] "" Vector__XXX
 SG_ WFS_Klemmenfreigabe  : 12|1@1+ (1.000000,0.000000) [0.000000|1.000000] "" Vector__XXX
 SG_ ZV_Tankklappe_offen  : 13|1@1+ (1.000000,0.000000) [0.000000|1.000000] "" Vector__XXX
 SG_ AAG_Anhaenger_abgesteckt  : 14|1@1+ (1.000000,0.000000) [0.000000|1.000000] "" Vector__XXX
 SG_ BCM1_LDS_Stellung  : 15|3@1+ (1.000000,0.000000) [0.000000|7.000000] "" Vector__XXX
 SG_ VS_Verdeck_Anf  : 18|1@1+ (1.000000,0.000000) [0.000000|1.000000] "" Vector__XXX
 SG_ VS_VD_entriegelt  : 19|1@1+ (1.000000,0.000000) [0.000000|1.000000] "" Vector__XXX
 SG_ ZV_HFS_offen  : 20|1@1+ (1.000000,0.000000) [0.000000|1.000000] "" Vector__XXX
 SG_ ZV_HBFS_offen  : 21|1@1+ (1.000000,0.000000) [0.000000|1.000000] "" Vector__XXX
 SG_ VS_VD_offen_ver  : 22|1@1+ (1.000000,0.000000) [0.000000|1.000000] "" Vector__XXX
 SG_ VS_VD_zu_ver  : 23|1@1+ (1.000000,0.000000) [0.000000|1.000000] "" Vector__XXX
 SG_ ZV_BT_offen  : 24|1@1+ (1.000000,0.000000) [0.000000|1.000000] "" Vector__XXX
 SG_ BCM1_Rueckfahrlicht_Schalter  : 25|1@1+ (1.000000,0.000000) [0.000000|1.000000] "" Airbag Motor_BEV
 SG_ ZV_FT_offen  : 26|1@1+ (1.000000,0.000000) [0.000000|1.000000] "" Vector__XXX
 SG_ Wischer_vorne_aktiv  : 27|1@1+ (1.000000,0.000000) [0.000000|1.000000] "" Vector__XXX
 SG_ AAG_Anhaenger_erkannt  : 28|1@1+ (1.000000,0.000000) [0.000000|1.000000] "" Airbag
 SG_ BCM1_MH_Schalter  : 29|1@1+ (1.000000,0.000000) [0.000000|1.000000] "" Vector__XXX
 SG_ ZV_HD_offen  : 30|1@1+ (1.000000,0.000000) [0.000000|1.000000] "" Vector__XXX
 SG_ Waschen_vorne_aktiv  : 31|1@1+ (1.000000,0.000000) [0.000000|1.000000] "" Vector__XXX
 SG_ KL_Thermomanagement  : 32|2@1+ (1.000000,0.000000) [0.000000|3.000000] "" Vector__XXX
 SG_ WFS_Schluessel_Fahrberecht  : 34|4@1+ (1.000000,0.000000) [0.000000|15.000000] "" Vector__XXX
 SG_ BCM_Rueckfahrlicht_Anf  : 38|1@1+ (1.000000,0.000000) [0.000000|1.000000] "" Vector__XXX
 SG_ WWSs_01_alt  : 39|1@1+ (1.000000,0.000000) [0.000000|1.000000] "" Vector__XXX
 SG_ BCM_Tankklappensteller_Fehler  : 40|1@1+ (1.000000,0.000000) [0.000000|1.000000] "" Vector__XXX
 SG_ AAG_LED_aktiv  : 41|1@1+ (1.000000,0.000000) [0.000000|1.000000] "" Vector__XXX
 SG_ ZV_verriegelt_soll  : 42|2@1+ (1.000000,0.000000) [0.000000|3.000000] "" Vector__XXX
 SG_ ZV_Schluessel_Zugang  : 44|4@1+ (1.000000,0.000000) [0.000000|15.000000] "" Vector__XXX
 SG_ WFS_ID_Geb_autorisiert_in_Kl15  : 48|1@1+ (1.000000,0.000000) [0.000000|1.000000] "" Vector__XXX
 SG_ BH_Fernlicht  : 49|1@1+ (1.000000,0.000000) [0.000000|1.000000] "" Vector__XXX
 SG_ BH_Blinker_li  : 50|1@1+ (1.000000,0.000000) [0.000000|1.000000] "" Vector__XXX
 SG_ BH_Blinker_re  : 51|1@1+ (1.000000,0.000000) [0.000000|1.000000] "" Vector__XXX
 SG_ BCM1_OBD_FStatus_ATemp  : 52|4@1+ (1.000000,0.000000) [0.000000|15.000000] "" Vector__XXX
 SG_ BCM1_Aussen_Temp_ungef  : 56|8@1+ (0.500000,-50.000000) [-50.000000|76.000000] "Unit_DegreCelsi" Vector__XXX

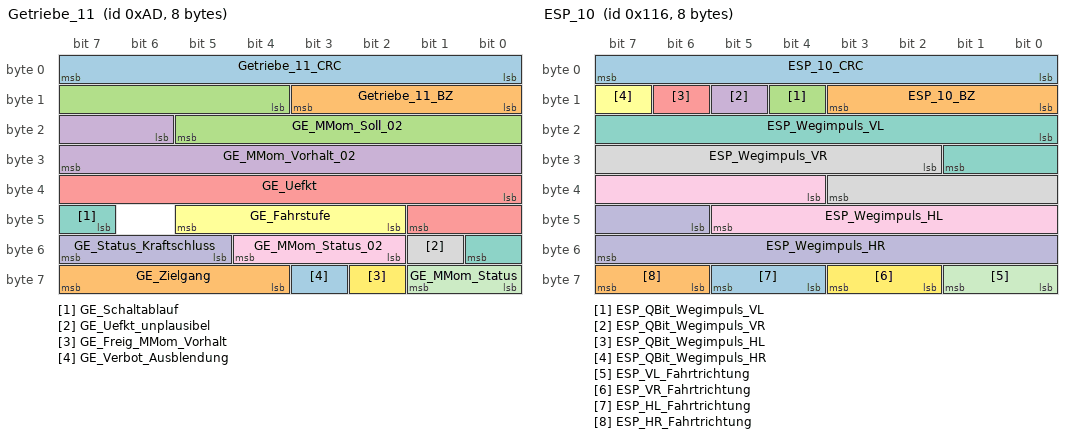
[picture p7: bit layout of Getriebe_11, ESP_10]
BO_ 173 Getriebe_11: 8 Motor_BEV
 SG_ Getriebe_11_CRC  : 0|8@1+ (1.000000,0.000000) [0.000000|255.000000] "" ICAS1_Gateway
 SG_ Getriebe_11_BZ  : 8|4@1+ (1.000000,0.000000) [0.000000|15.000000] "" ICAS1_Gateway
 SG_ GE_MMom_Soll_02  : 12|10@1+ (1.000000,-509.000000) [-509.000000|509.000000] "" ICAS1_Gateway
 SG_ GE_MMom_Vorhalt_02  : 22|10@1+ (1.000000,-509.000000) [-509.000000|509.000000] "" ICAS1_Gateway
 SG_ GE_Uefkt  : 32|10@1+ (0.100000,0.000000) [0.000000|102.200000] "" ICAS1_Gateway
 SG_ GE_Fahrstufe  : 42|4@1+ (1.000000,0.000000) [0.000000|15.000000] "" ICAS1_Gateway
 SG_ GE_Schaltablauf  : 47|2@1+ (1.000000,0.000000) [0.000000|3.000000] "" ICAS1_Gateway
 SG_ GE_Uefkt_unplausibel  : 49|1@1+ (1.000000,0.000000) [0.000000|1.000000] "" ICAS1_Gateway
 SG_ GE_MMom_Status_02  : 50|3@1+ (1.000000,0.000000) [0.000000|7.000000] "" ICAS1_Gateway
 SG_ GE_Status_Kraftschluss  : 53|3@1+ (1.000000,0.000000) [0.000000|7.000000] "" ICAS1_Gateway
 SG_ GE_MMom_Status  : 56|2@1+ (1.000000,0.000000) [0.000000|3.000000] "" ICAS1_Gateway
 SG_ GE_Freig_MMom_Vorhalt  : 58|1@1+ (1.000000,0.000000) [0.000000|1.000000] "" ICAS1_Gateway
 SG_ GE_Verbot_Ausblendung  : 59|1@1+ (1.000000,0.000000) [0.000000|1.000000] "" ICAS1_Gateway
 SG_ GE_Zielgang  : 60|4@1+ (1.000000,0.000000) [0.000000|15.000000] "" ICAS1_Gateway

BU_:  Airbag BAP_Tester ICAS1_Gateway ICAS1_KommunikationsServer LE1 LE2 Motor_BEV Schaltbetaetigung

BO_ 252 ESC_51: 48 ICAS1_Gateway
 SG_ ESC_51_CRC  : 0|8@1+ (1.000000,0.000000) [0.000000|255.000000] "" Motor_BEV
 SG_ ESC_51_BZ  : 8|4@1+ (1.000000,0.000000) [0.000000|15.000000] "" Motor_BEV
 SG_ ESC_aktBr_Modus  : 12|2@1+ (1.000000,0.000000) [0.000000|3.000000] "" Vector__XXX
 SG_ ESC_Blending_Solldruck  : 14|10@1+ (0.250000,0.000000) [0.000000|250.000000] "Unit_Bar" Vector__XXX
 SG_ ESC_aktBr_Volumenstrom  : 24|16@1+ (0.007812,-252.000000) [-252.000000|252.000000] "Unit_MilliLiterPerSec" Vector__XXX
 SG_ ESC_EBKV_Kraftblending_Modus  : 40|2@1+ (1.000000,0.000000) [0.000000|3.000000] "" Vector__XXX
 SG_ ESC_Bremsdruck_Modell  : 42|10@1+ (0.250000,0.000000) [0.000000|250.000000] "Unit_Bar" Motor_BEV
 SG_ ESC_Bremsdruck_02  : 52|10@1+ (0.300000,-30.000000) [-30.000000|276.600000] "Unit_Bar" Vector__XXX
 SG_ ESC_QBit_Bremsdruck_02  : 62|1@1+ (1.000000,0.000000) [0.000000|1.000000] "" Vector__XXX
 SG_ ESP_HL_Radgeschw_02  : 64|16@1+ (0.007500,0.000000) [0.000000|491.490000] "Unit_KiloMeterPerHour" Airbag LE1 LE2 Motor_BEV
 SG_ ESP_HR_Radgeschw_02  : 80|16@1+ (0.007500,0.000000) [0.000000|491.490000] "Unit_KiloMeterPerHour" Airbag LE1 LE2 Motor_BEV
 SG_ ESP_VL_Radgeschw_02  : 96|16@1+ (0.007500,0.000000) [0.000000|491.490000] "Unit_KiloMeterPerHour" Airbag LE1 LE2 Motor_BEV
 SG_ ESP_VR_Radgeschw_02  : 112|16@1+ (0.007500,0.000000) [0.000000|491.490000] "Unit_KiloMeterPerHour" Airbag LE1 LE2 Motor_BEV
 SG_ ESP_FZR_uebersteuern  : 128|8@1+ (0.004000,0.000000) [0.000000|1.000000] "" Vector__XXX
 SG_ ESP_FZR_untersteuern  : 136|8@1+ (0.004000,0.000000) [0.000000|1.000000] "" Vector__XXX
 SG_ ESC_Anf_Mindestreku  : 144|1@1+ (1.000000,0.000000) [0.000000|1.000000] "" Motor_BEV
 SG_ ESC_GMV_aktiv  : 145|3@1+ (1.000000,0.000000) [0.000000|7.000000] "" Vector__XXX
 SG_ ESC_GMV_nicht_verfuegbar  : 148|1@1+ (1.000000,0.000000) [0.000000|1.000000] "" Vector__XXX
 SG_ ESC_Status_vRef_Stuetzeingriff  : 149|1@1+ (1.000000,0.000000) [0.000000|1.000000] "" Motor_BEV
 SG_ FDR_Allradverteilung_aktiv  : 150|1@1+ (1.000000,0.000000) [0.000000|1.000000] "" Vector__XXX
 SG_ FDR_Anf_Allradbetrieb  : 151|1@1+ (1.000000,0.000000) [0.000000|1.000000] "" Vector__XXX
 SG_ ESP_HL_Bremsmoment  : 152|8@1+ (20.000000,0.000000) [0.000000|5060.000000] "Unit_NewtoMeter" Motor_BEV
 SG_ ESP_HR_Bremsmoment  : 160|8@1+ (20.000000,0.000000) [0.000000|5060.000000] "Unit_NewtoMeter" Motor_BEV
 SG_ ESP_VR_Bremsmoment  : 168|8@1+ (40.000000,0.000000) [0.000000|10120.000000] "Unit_NewtoMeter" Motor_BEV
 SG_ ESP_VL_Bremsmoment  : 176|8@1+ (40.000000,0.000000) [0.000000|10120.000000] "Unit_NewtoMeter" Motor_BEV
 SG_ ESP_FDR_uebersteuern  : 184|8@1+ (0.004000,0.000000) [0.000000|1.000000] "" Motor_BEV
 SG_ ESP_FDR_untersteuern  : 192|8@1+ (0.004000,0.000000) [0.000000|1.000000] "" Motor_BEV
 SG_ TSMomBegrenzung  : 268|12@1+ (3.000000,-12279.000000) [-12279.000000|0.000000] "" Motor_BEV
 SG_ ESC_Allrad_Anteil_max_sek  : 280|9@1+ (0.200000,0.000000) [0.000000|100.000000] "Unit_PerCent" Motor_BEV
 SG_ ESC_Allrad_Anteil_min_sek  : 289|9@1+ (0.200000,0.000000) [0.000000|100.000000] "Unit_PerCent" Motor_BEV
 SG_ ESC_Status_Eingriff  : 298|2@1+ (1.000000,0.000000) [0.000000|3.000000] "" Motor_BEV
 SG_ ESC_Status_Eingriff_sek  : 300|2@1+ (1.000000,0.000000) [0.000000|3.000000] "" Motor_BEV
 SG_ ESC_MomRad_Eingriff  : 302|13@1+ (3.000000,-12279.000000) [-12279.000000|12279.000000] "Unit_None" Motor_BEV
 SG_ ESC_MomRad_Eingriff_sek  : 315|13@1+ (3.000000,-12279.000000) [-12279.000000|12279.000000] "Unit_None" Motor_BEV
 SG_ ESC_Achsdrehzahl_Max  : 328|14@1+ (0.400000,-800.000000) [-800.000000|5752.400000] "Unit_MinutInver" Motor_BEV
 SG_ ESC_Achsdrehzahl_Min  : 342|14@1+ (0.400000,-800.000000) [-800.000000|5752.400000] "Unit_MinutInver" Motor_BEV
 SG_ ESC_Achsdrehzahl_Max_sek  : 356|14@1+ (0.400000,-800.000000) [-800.000000|5752.400000] "Unit_MinutInver" Motor_BEV
 SG_ ESC_Achsdrehzahl_Min_sek  : 370|14@1+ (0.400000,-800.000000) [-800.000000|5752.400000] "Unit_MinutInver" Motor_BEV

BO_ 2463978647 ESC_52: 16 ICAS1_Gateway
 SG_ ESP_ACC_LDE  : 12|1@1+ (1.000000,0.000000) [0.000000|1.000000] "" Vector__XXX
 SG_ ESP_Allrad_Antrieb  : 13|1@1+ (1.000000,0.000000) [0.000000|1.000000] "" Vector__XXX
 SG_ ESP_Codierung_ADS  : 14|2@1+ (1.000000,0.000000) [0.000000|3.000000] "" Vector__XXX
 SG_ ESP_RTA_HL  : 16|8@1+ (0.048828,-6.201170) [-6.201170|6.152346] "Unit_PerCent" Motor_BEV
 SG_ ESP_RTA_HR  : 24|8@1+ (0.048828,-6.201170) [-6.201170|6.152346] "Unit_PerCent" Motor_BEV
 SG_ ESP_RTA_VR  : 32|8@1+ (0.048828,-6.201170) [-6.201170|6.152346] "Unit_PerCent" Motor_BEV
 SG_ OBD_Fehler_Radsensor_HL  : 40|4@1+ (1.000000,0.000000) [0.000000|15.000000] "" Motor_BEV
 SG_ OBD_Fehler_Radsensor_HR  : 44|4@1+ (1.000000,0.000000) [0.000000|15.000000] "" Motor_BEV
 SG_ OBD_Fehler_Radsensor_VL  : 48|4@1+ (1.000000,0.000000) [0.000000|15.000000] "" Motor_BEV
 SG_ OBD_Fehler_Radsensor_VR  : 52|4@1+ (1.000000,0.000000) [0.000000|15.000000] "" Motor_BEV
 SG_ ESP_Qualifizierung_Antriebsart  : 56|1@1+ (1.000000,0.000000) [0.000000|1.000000] "" Vector__XXX
 SG_ ESP_Offroad_Modus  : 57|1@1+ (1.000000,0.000000) [0.000000|1.000000] "" Vector__XXX
 SG_ ESP_MKB_ausloesbar  : 58|1@1+ (1.000000,0.000000) [0.000000|1.000000] "" Vector__XXX
 SG_ ESP_Stat_FallBack_eBKV  : 59|1@1+ (1.000000,0.000000) [0.000000|1.000000] "" Vector__XXX
 SG_ ESP_CM_Variante  : 60|1@1+ (1.000000,0.000000) [0.000000|1.000000] "" Vector__XXX
 SG_ ESP_OBD_Status  : 61|1@1+ (1.000000,0.000000) [0.000000|1.000000] "" Motor_BEV
 SG_ ESP_Rollenmodus_Deaktivieren  : 62|1@1+ (1.000000,0.000000) [0.000000|1.000000] "" Motor_BEV
 SG_ ESP_nachtr_Stopp_Anf  : 63|1@1+ (1.000000,0.000000) [0.000000|1.000000] "" Vector__XXX

BO_ 2527679683 ESC_ASM_01: 8 ICAS1_Gateway
 SG_ ESC_ASM_Ereignis  : 0|8@1+ (1.000000,0.000000) [1.000000|254.000000] "Unit_None" Airbag
 SG_ ESC_ASM_Zeitstempel  : 8|8@1+ (0.080000,0.000000) [0.000000|20.320000] "Unit_Secon" Airbag
 SG_ ESC_ASM_Data_1  : 16|8@1+ (1.000000,0.000000) [0.000000|255.000000] "" Airbag
 SG_ ESC_ASM_Data_2  : 24|8@1+ (1.000000,0.000000) [0.000000|255.000000] "" Airbag
 SG_ ESC_ASM_Data_3  : 32|8@1+ (1.000000,0.000000) [0.000000|255.000000] "" Airbag
 SG_ ESC_ASM_Data_4  : 40|8@1+ (1.000000,0.000000) [0.000000|255.000000] "" Airbag
 SG_ ESC_ASM_Data_5  : 48|8@1+ (1.000000,0.000000) [0.000000|255.000000] "" Airbag
 SG_ ESC_ASM_Data_6  : 56|8@1+ (1.000000,0.000000) [0.000000|255.000000] "" Airbag

BO_ 278 ESP_10: 8 ICAS1_Gateway
 SG_ ESP_10_CRC  : 0|8@1+ (1.000000,0.000000) [0.000000|255.000000] "" Vector__XXX
 SG_ ESP_10_BZ  : 8|4@1+ (1.000000,0.000000) [0.000000|15.000000] "" Vector__XXX
 SG_ ESP_QBit_Wegimpuls_VL  : 12|1@1+ (1.000000,0.000000) [0.000000|1.000000] "" Motor_BEV
 SG_ ESP_QBit_Wegimpuls_VR  : 13|1@1+ (1.000000,0.000000) [0.000000|1.000000] "" Motor_BEV
 SG_ ESP_QBit_Wegimpuls_HL  : 14|1@1+ (1.000000,0.000000) [0.000000|1.000000] "" Motor_BEV
 SG_ ESP_QBit_Wegimpuls_HR  : 15|1@1+ (1.000000,0.000000) [0.000000|1.000000] "" Motor_BEV
 SG_ ESP_Wegimpuls_VL  : 16|10@1+ (1.000000,0.000000) [0.000000|1000.000000] "" Motor_BEV
 SG_ ESP_Wegimpuls_VR  : 26|10@1+ (1.000000,0.000000) [0.000000|1000.000000] "" Motor_BEV
 SG_ ESP_Wegimpuls_HL  : 36|10@1+ (1.000000,0.000000) [0.000000|1000.000000] "" Motor_BEV
 SG_ ESP_Wegimpuls_HR  : 46|10@1+ (1.000000,0.000000) [0.000000|1000.000000] "" Motor_BEV
 SG_ ESP_VL_Fahrtrichtung  : 56|2@1+ (1.000000,0.000000) [0.000000|3.000000] "" Motor_BEV
 SG_ ESP_VR_Fahrtrichtung  : 58|2@1+ (1.000000,0.000000) [0.000000|3.000000] "" Motor_BEV
 SG_ ESP_HL_Fahrtrichtung  : 60|2@1+ (1.000000,0.000000) [0.000000|3.000000] "" Motor_BEV
 SG_ ESP_HR_Fahrtrichtung  : 62|2@1+ (1.000000,0.000000) [0.000000|3.000000] "" Motor_BEV

BO_ 1629 ESP_20: 8 ICAS1_Gateway
 SG_ ESP_20_CRC  : 0|8@1+ (1.000000,0.000000) [0.000000|255.000000] "" Vector__XXX
 SG_ ESP_20_BZ  : 8|4@1+ (1.000000,0.000000) [0.000000|15.000000] "" Vector__XXX
 SG_ BR_Systemart  : 12|2@1+ (1.000000,0.000000) [0.000000|3.000000] "" Vector__XXX
 SG_ ESP_SpannungsAnf_02  : 14|2@1+ (1.000000,0.000000) [0.000000|3.000000] "" Vector__XXX
 SG_ ESP_Zaehnezahl  : 16|8@1+ (1.000000,0.000000) [0.000000|255.000000] "" Vector__XXX
 SG_ ESP_Charisma_FahrPr  : 24|4@1+ (1.000000,0.000000) [0.000000|15.000000] "" Vector__XXX
 SG_ ESP_Charisma_Status  : 28|2@1+ (1.000000,0.000000) [0.000000|3.000000] "" Vector__XXX
 SG_ ESP_Wiederstart_Anz_01  : 30|1@1+ (1.000000,0.000000) [0.000000|1.000000] "" Vector__XXX
 SG_ ESP_Wiederstart_Anz_02  : 31|1@1+ (1.000000,0.000000) [0.000000|1.000000] "" Vector__XXX
 SG_ ESP_Wiederstart_Anz_03  : 32|1@1+ (1.000000,0.000000) [0.000000|1.000000] "" Vector__XXX
 SG_ ESP_Wiederstart_Anz_04  : 33|1@1+ (1.000000,0.000000) [0.000000|1.000000] "" Vector__XXX
 SG_ ESP_Stoppverbot_Anz_01  : 34|1@1+ (1.000000,0.000000) [0.000000|1.000000] "" Vector__XXX
 SG_ ESP_Stoppverbot_Anz_02  : 35|1@1+ (1.000000,0.000000) [0.000000|1.000000] "" Vector__XXX
 SG_ ESP_Stoppverbot_Anz_03  : 36|1@1+ (1.000000,0.000000) [0.000000|1.000000] "" Vector__XXX
 SG_ ESP_Stoppverbot_Anz_04  : 37|1@1+ (1.000000,0.000000) [0.000000|1.000000] "" Vector__XXX
 SG_ ESP_Stoppverbot_Anz_05  : 38|1@1+ (1.000000,0.000000) [0.000000|1.000000] "" Vector__XXX
 SG_ ESP_Stoppverbot_Anz_06  : 39|1@1+ (1.000000,0.000000) [0.000000|1.000000] "" Vector__XXX
 SG_ ESP_Stoppverbot_Anz_07  : 40|1@1+ (1.000000,0.000000) [0.000000|1.000000] "" Vector__XXX
 SG_ ESP_Stoppverbot_Anz_Std  : 41|1@1+ (1.000000,0.000000) [0.000000|1.000000] "" Vector__XXX
 SG_ ESP_Dachrelingsensor  : 42|2@1+ (1.000000,0.000000) [0.000000|3.000000] "" Vector__XXX
 SG_ ESP_Stoppverbot_Anz_08  : 44|1@1+ (1.000000,0.000000) [0.000000|1.000000] "" Vector__XXX
 SG_ HDC_Charisma_FahrPr  : 45|4@1+ (1.000000,0.000000) [0.000000|15.000000] "" Vector__XXX
 SG_ HDC_Charisma_Status  : 49|2@1+ (1.000000,0.000000) [0.000000|3.000000] "" Vector__XXX
 SG_ BR_QBit_Reifenumfang  : 51|1@1+ (1.000000,0.000000) [0.000000|1.000000] "" LE1 LE2
 SG_ BR_Reifenumfang  : 52|12@1+ (1.000000,0.000000) [0.000000|4095.000000] "Unit_MilliMeter" LE1 LE2

BO_ 253 ESP_21: 8 ICAS1_Gateway
 SG_ ESP_21_CRC  : 0|8@1+ (1.000000,0.000000) [0.000000|255.000000] "" Airbag LE1 LE2 Motor_BEV
 SG_ ESP_21_BZ  : 8|4@1+ (1.000000,0.000000) [0.000000|15.000000] "" Airbag LE1 LE2 Motor_BEV
 SG_ BR_Eingriffsmoment  : 12|10@1+ (1.000000,-509.000000) [-509.000000|509.000000] "" Vector__XXX
 SG_ ESP_PLA_Bremseingriff  : 22|1@1+ (1.000000,0.000000) [0.000000|1.000000] "" Vector__XXX
 SG_ ESP_Diagnose  : 23|1@1+ (1.000000,0.000000) [0.000000|1.000000] "" Vector__XXX
 SG_ ESC_Reku_Freigabe  : 24|1@1+ (1.000000,0.000000) [0.000000|1.000000] "" Motor_BEV
 SG_ ESC_v_Signal_Qualifier_High_Low  : 25|3@1+ (1.000000,0.000000) [0.000000|7.000000] "" Airbag
 SG_ ESP_Vorsteuerung  : 28|1@1+ (1.000000,0.000000) [0.000000|1.000000] "" Motor_BEV
 SG_ ESP_AWV3_Brems_aktiv  : 29|1@1+ (1.000000,0.000000) [0.000000|1.000000] "" Vector__XXX
 SG_ OBD_Schlechtweg  : 30|1@1+ (1.000000,0.000000) [0.000000|1.000000] "" Vector__XXX
 SG_ OBD_QBit_Schlechtweg  : 31|1@1+ (1.000000,0.000000) [0.000000|1.000000] "" Vector__XXX
 SG_ ESP_v_Signal  : 32|16@1+ (0.010000,0.000000) [0.000000|655.320000] "Unit_KiloMeterPerHour" Airbag LE1 LE2 Motor_BEV
 SG_ ASR_Tastung_passiv  : 48|1@1+ (1.000000,0.000000) [0.000000|1.000000] "" Airbag Motor_BEV
 SG_ ESP_Tastung_passiv  : 49|1@1+ (1.000000,0.000000) [0.000000|1.000000] "" Airbag Motor_BEV
 SG_ ESP_Systemstatus  : 50|1@1+ (1.000000,0.000000) [0.000000|1.000000] "" Motor_BEV
 SG_ ASR_Schalteingriff  : 51|2@1+ (1.000000,0.000000) [0.000000|3.000000] "" Vector__XXX
 SG_ ESP_Haltebestaetigung  : 53|1@1+ (1.000000,0.000000) [0.000000|1.000000] "" Vector__XXX
 SG_ ESP_MKB_Abbruch_Geschw  : 54|1@1+ (1.000000,0.000000) [0.000000|1.000000] "" Vector__XXX
 SG_ ESP_QBit_v_Signal  : 55|1@1+ (1.000000,0.000000) [0.000000|1.000000] "" LE1 LE2 Motor_BEV
 SG_ ABS_Bremsung  : 56|1@1+ (1.000000,0.000000) [0.000000|1.000000] "" Airbag Motor_BEV
 SG_ ASR_Anf  : 57|1@1+ (1.000000,0.000000) [0.000000|1.000000] "" Vector__XXX
 SG_ MSR_Anf  : 58|1@1+ (1.000000,0.000000) [0.000000|1.000000] "" Vector__XXX
 SG_ EBV_Eingriff  : 59|1@1+ (1.000000,0.000000) [0.000000|1.000000] "" Vector__XXX
 SG_ EDS_Eingriff  : 60|1@1+ (1.000000,0.000000) [0.000000|1.000000] "" Motor_BEV
 SG_ ESP_Eingriff  : 61|1@1+ (1.000000,0.000000) [0.000000|1.000000] "" Airbag Motor_BEV
 SG_ ESP_ASP  : 62|1@1+ (1.000000,0.000000) [0.000000|1.000000] "" Vector__XXX
 SG_ ESP_Anhaltevorgang_ACC_aktiv  : 63|1@1+ (1.000000,0.000000) [0.000000|1.000000] "" Vector__XXX

BO_ 795 ESP_24: 8 ICAS1_Gateway
 SG_ ESP_24_CRC  : 0|8@1+ (1.000000,0.000000) [0.000000|255.000000] "" Vector__XXX
 SG_ ESP_24_BZ  : 8|4@1+ (1.000000,0.000000) [0.000000|15.000000] "" Vector__XXX
 SG_ ESP_Lampe  : 12|1@1+ (1.000000,0.000000) [0.000000|1.000000] "" Motor_BEV
 SG_ ABS_Lampe  : 13|1@1+ (1.000000,0.000000) [0.000000|1.000000] "" Vector__XXX
 SG_ BK_Lampe_02  : 14|2@1+ (1.000000,0.000000) [0.000000|3.000000] "" Vector__XXX
 SG_ TC_Lampe  : 16|1@1+ (1.000000,0.000000) [0.000000|1.000000] "" Vector__XXX
 SG_ ESP_m_Raddrehz  : 17|15@1+ (0.002000,0.000000) [0.000000|65.278000] "Unit_Hertz" Vector__XXX
 SG_ ESP_Textanzeigen_03  : 32|5@1+ (1.000000,0.000000) [0.000000|31.000000] "" Vector__XXX
 SG_ ESP_Meldungen  : 37|3@1+ (1.000000,0.000000) [0.000000|7.000000] "" Vector__XXX
 SG_ ESP_Wegimp_VA  : 40|11@1+ (1.000000,0.000000) [0.000000|2047.000000] "" Vector__XXX
 SG_ ESP_Fehlerstatus_Wegimp  : 51|1@1+ (1.000000,0.000000) [0.000000|1.000000] "" Vector__XXX
 SG_ ESP_Wegimp_Ueberlauf  : 52|1@1+ (1.000000,0.000000) [0.000000|1.000000] "" Vector__XXX
 SG_ ESP_QBit_Wegimp_VA  : 53|1@1+ (1.000000,0.000000) [0.000000|1.000000] "" Vector__XXX
 SG_ ESP_HDC_FktLampe  : 54|1@1+ (1.000000,0.000000) [0.000000|1.000000] "" Vector__XXX
 SG_ ESP_Off_Lampe  : 55|1@1+ (1.000000,0.000000) [0.000000|1.000000] "" Airbag
 SG_ ESP_HDC_Regelgeschw  : 56|7@1+ (0.320000,0.000000) [0.320000|39.680000] "Unit_KiloMeterPerHour" Vector__XXX
 SG_ ESP_BKV_Warnung  : 63|1@1+ (1.000000,0.000000) [0.000000|1.000000] "" Vector__XXX

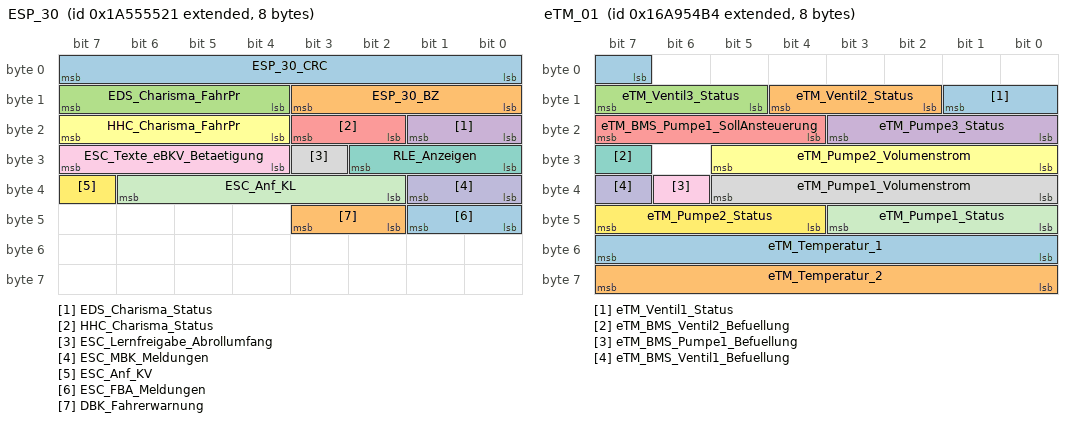
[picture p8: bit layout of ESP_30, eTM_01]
BO_ 2589283617 ESP_30: 8 ICAS1_Gateway
 SG_ ESP_30_CRC  : 0|8@1+ (1.000000,0.000000) [0.000000|255.000000] "" Vector__XXX
 SG_ ESP_30_BZ  : 8|4@1+ (1.000000,0.000000) [0.000000|15.000000] "" Vector__XXX
 SG_ EDS_Charisma_FahrPr  : 12|4@1+ (1.000000,0.000000) [0.000000|15.000000] "" Vector__XXX
 SG_ EDS_Charisma_Status  : 16|2@1+ (1.000000,0.000000) [0.000000|3.000000] "" Vector__XXX
 SG_ HHC_Charisma_Status  : 18|2@1+ (1.000000,0.000000) [0.000000|3.000000] "" Vector__XXX
 SG_ HHC_Charisma_FahrPr  : 20|4@1+ (1.000000,0.000000) [0.000000|15.000000] "" Vector__XXX
 SG_ RLE_Anzeigen  : 24|3@1+ (1.000000,0.000000) [0.000000|7.000000] "" Vector__XXX
 SG_ ESC_Lernfreigabe_Abrollumfang  : 27|1@1+ (1.000000,0.000000) [0.000000|1.000000] "" Vector__XXX
 SG_ ESC_Texte_eBKV_Betaetigung  : 28|4@1+ (1.000000,0.000000) [0.000000|15.000000] "" Vector__XXX
 SG_ ESC_MBK_Meldungen  : 32|2@1+ (1.000000,0.000000) [0.000000|3.000000] "" Vector__XXX
 SG_ ESC_Anf_KL  : 34|5@1+ (3.225806,0.000000) [0.000000|100.000000] "Unit_PerCent" Motor_BEV
 SG_ ESC_Anf_KV  : 39|1@1+ (1.000000,0.000000) [0.000000|1.000000] "" Motor_BEV
 SG_ ESC_FBA_Meldungen  : 40|2@1+ (1.000000,0.000000) [0.000000|3.000000] "" Vector__XXX
 SG_ DBK_Fahrerwarnung  : 42|2@1+ (1.000000,0.000000) [0.000000|3.000000] "" Vector__XXX

BO_ 2527679668 eTM_01: 8 Motor_BEV
 SG_ eTM_Ventil1_Status  : 7|3@1+ (1.000000,0.000000) [0.000000|7.000000] "" ICAS1_Gateway
 SG_ eTM_Ventil2_Status  : 10|3@1+ (1.000000,0.000000) [0.000000|7.000000] "" ICAS1_Gateway
 SG_ eTM_Ventil3_Status  : 13|3@1+ (1.000000,0.000000) [0.000000|7.000000] "" ICAS1_Gateway
 SG_ eTM_Pumpe3_Status  : 16|4@1+ (10.000000,0.000000) [0.000000|130.000000] "Unit_PerCent" ICAS1_Gateway
 SG_ eTM_BMS_Pumpe1_SollAnsteuerung  : 20|4@1+ (10.000000,0.000000) [0.000000|130.000000] "Unit_PerCent" ICAS1_Gateway
 SG_ eTM_Pumpe2_Volumenstrom  : 24|6@1+ (0.500000,0.000000) [0.000000|30.500000] "Unit_LiterPerMinut" ICAS1_Gateway LE1 LE2
 SG_ eTM_BMS_Ventil2_Befuellung  : 31|1@1+ (1.000000,0.000000) [0.000000|1.000000] "" ICAS1_Gateway
 SG_ eTM_Pumpe1_Volumenstrom  : 32|6@1+ (0.500000,0.000000) [0.000000|30.500000] "Unit_LiterPerMinut" ICAS1_Gateway LE1 LE2
 SG_ eTM_BMS_Pumpe1_Befuellung  : 38|1@1+ (1.000000,0.000000) [0.000000|1.000000] "" ICAS1_Gateway
 SG_ eTM_BMS_Ventil1_Befuellung  : 39|1@1+ (1.000000,0.000000) [0.000000|1.000000] "" ICAS1_Gateway
 SG_ eTM_Pumpe1_Status  : 40|4@1+ (10.000000,0.000000) [0.000000|130.000000] "Unit_PerCent" ICAS1_Gateway LE1 LE2
 SG_ eTM_Pumpe2_Status  : 44|4@1+ (10.000000,0.000000) [0.000000|130.000000] "Unit_PerCent" ICAS1_Gateway LE1 LE2
 SG_ eTM_Temperatur_1  : 48|8@1+ (0.750000,-40.000000) [-40.000000|149.750000] "Unit_DegreCelsi" ICAS1_Gateway LE1 LE2
 SG_ eTM_Temperatur_2  : 56|8@1+ (0.750000,-40.000000) [-40.000000|149.750000] "Unit_DegreCelsi" ICAS1_Gateway LE1 LE2

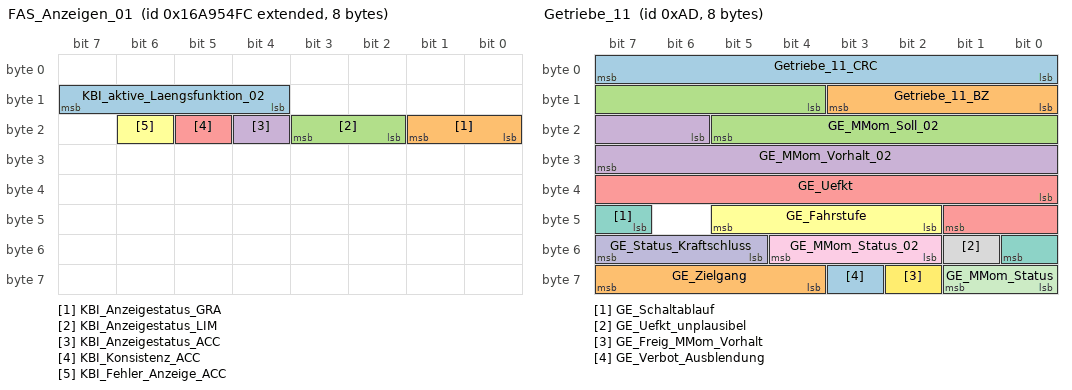
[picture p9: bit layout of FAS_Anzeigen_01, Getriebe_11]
BO_ 2527679740 FAS_Anzeigen_01: 8 ICAS1_KommunikationsServer
 SG_ KBI_aktive_Laengsfunktion_02  : 12|4@1+ (1.000000,0.000000) [0.000000|15.000000] "" Motor_BEV
 SG_ KBI_Anzeigestatus_GRA  : 16|2@1+ (1.000000,0.000000) [0.000000|3.000000] "" Motor_BEV
 SG_ KBI_Anzeigestatus_LIM  : 18|2@1+ (1.000000,0.000000) [0.000000|3.000000] "" Motor_BEV
 SG_ KBI_Anzeigestatus_ACC  : 20|1@1+ (1.000000,0.000000) [0.000000|1.000000] "" Vector__XXX
 SG_ KBI_Konsistenz_ACC  : 21|1@1+ (1.000000,0.000000) [0.000000|1.000000] "" Vector__XXX
 SG_ KBI_Fehler_Anzeige_ACC  : 22|1@1+ (1.000000,0.000000) [0.000000|1.000000] "" Vector__XXX

BO_ 2589283684 FoD_01: 8 ICAS1_Gateway
 SG_ GRA_FoD_Status  : 58|2@1+ (1.000000,0.000000) [0.000000|3.000000] "" Vector__XXX
 SG_ FoD_Transmission_Info  : 60|2@1+ (1.000000,0.000000) [0.000000|3.000000] "" Motor_BEV

BO_ 2549875574 FoD_MO_01_Req: 8 ICAS1_Gateway
 SG_ FoD_MO_01_Req_Data  : 0|64@1+ (1.000000,0.000000) [0.000000|18446744073709551616.000000] "" Motor_BEV

BO_ 2550006646 FoD_MO_01_Resp: 8 Motor_BEV
 SG_ FoD_MO_01_Resp_Data  : 0|64@1+ (1.000000,0.000000) [0.000000|18446744073709551616.000000] "" ICAS1_Gateway

BO_ 987 Gateway_72: 8 ICAS1_Gateway
 SG_ BCM_01_alt  : 0|1@1+ (1.000000,0.000000) [0.000000|1.000000] "" Airbag
 SG_ SMLS_01_alt  : 1|1@1+ (1.000000,0.000000) [0.000000|1.000000] "" Vector__XXX
 SG_ ZV_02_alt  : 2|1@1+ (1.000000,0.000000) [0.000000|1.000000] "" Vector__XXX
 SG_ Wischer_01_alt  : 3|1@1+ (1.000000,0.000000) [0.000000|1.000000] "" Vector__XXX
 SG_ Anhaenger_01_alt  : 4|1@1+ (1.000000,0.000000) [0.000000|1.000000] "" Airbag
 SG_ Klima_Sensor_02_alt  : 5|1@1+ (1.000000,0.000000) [0.000000|1.000000] "" Vector__XXX
 SG_ Verdeck_01_alt  : 6|1@1+ (1.000000,0.000000) [0.000000|1.000000] "" Vector__XXX
 SG_ Klima_11_alt  : 7|1@1+ (1.000000,0.000000) [0.000000|1.000000] "" Vector__XXX
 SG_ WFS_01_alt  : 8|1@1+ (1.000000,0.000000) [0.000000|1.000000] "" Vector__XXX
 SG_ Licht_Anf_01_alt  : 9|1@1+ (1.000000,0.000000) [0.000000|1.000000] "" Vector__XXX
 SG_ ZV_verriegelt_extern_soll  : 10|1@1+ (1.000000,0.000000) [0.000000|1.000000] "" Vector__XXX
 SG_ BH_Lichthupe  : 11|1@1+ (1.000000,0.000000) [0.000000|1.000000] "" Vector__XXX
 SG_ WFS_Klemmenfreigabe  : 12|1@1+ (1.000000,0.000000) [0.000000|1.000000] "" Vector__XXX
 SG_ ZV_Tankklappe_offen  : 13|1@1+ (1.000000,0.000000) [0.000000|1.000000] "" Vector__XXX
 SG_ AAG_Anhaenger_abgesteckt  : 14|1@1+ (1.000000,0.000000) [0.000000|1.000000] "" Vector__XXX
 SG_ BCM1_LDS_Stellung  : 15|3@1+ (1.000000,0.000000) [0.000000|7.000000] "" Vector__XXX
 SG_ VS_Verdeck_Anf  : 18|1@1+ (1.000000,0.000000) [0.000000|1.000000] "" Vector__XXX
 SG_ VS_VD_entriegelt  : 19|1@1+ (1.000000,0.000000) [0.000000|1.000000] "" Vector__XXX
 SG_ ZV_HFS_offen  : 20|1@1+ (1.000000,0.000000) [0.000000|1.000000] "" Vector__XXX
 SG_ ZV_HBFS_offen  : 21|1@1+ (1.000000,0.000000) [0.000000|1.000000] "" Vector__XXX
 SG_ VS_VD_offen_ver  : 22|1@1+ (1.000000,0.000000) [0.000000|1.000000] "" Vector__XXX
 SG_ VS_VD_zu_ver  : 23|1@1+ (1.000000,0.000000) [0.000000|1.000000] "" Vector__XXX
 SG_ ZV_BT_offen  : 24|1@1+ (1.000000,0.000000) [0.000000|1.000000] "" Vector__XXX
 SG_ BCM1_Rueckfahrlicht_Schalter  : 25|1@1+ (1.000000,0.000000) [0.000000|1.000000] "" Airbag Motor_BEV
 SG_ ZV_FT_offen  : 26|1@1+ (1.000000,0.000000) [0.000000|1.000000] "" Vector__XXX
 SG_ Wischer_vorne_aktiv  : 27|1@1+ (1.000000,0.000000) [0.000000|1.000000] "" Vector__XXX
 SG_ AAG_Anhaenger_erkannt  : 28|1@1+ (1.000000,0.000000) [0.000000|1.000000] "" Airbag
 SG_ BCM1_MH_Schalter  : 29|1@1+ (1.000000,0.000000) [0.000000|1.000000] "" Vector__XXX
 SG_ ZV_HD_offen  : 30|1@1+ (1.000000,0.000000) [0.000000|1.000000] "" Vector__XXX
 SG_ Waschen_vorne_aktiv  : 31|1@1+ (1.000000,0.000000) [0.000000|1.000000] "" Vector__XXX
 SG_ KL_Thermomanagement  : 32|2@1+ (1.000000,0.000000) [0.000000|3.000000] "" Vector__XXX
 SG_ WFS_Schluessel_Fahrberecht  : 34|4@1+ (1.000000,0.000000) [0.000000|15.000000] "" Vector__XXX
 SG_ BCM_Rueckfahrlicht_Anf  : 38|1@1+ (1.000000,0.000000) [0.000000|1.000000] "" Vector__XXX
 SG_ WWSs_01_alt  : 39|1@1+ (1.000000,0.000000) [0.000000|1.000000] "" Vector__XXX
 SG_ BCM_Tankklappensteller_Fehler  : 40|1@1+ (1.000000,0.000000) [0.000000|1.000000] "" Vector__XXX
 SG_ AAG_LED_aktiv  : 41|1@1+ (1.000000,0.000000) [0.000000|1.000000] "" Vector__XXX
 SG_ ZV_verriegelt_soll  : 42|2@1+ (1.000000,0.000000) [0.000000|3.000000] "" Vector__XXX
 SG_ ZV_Schluessel_Zugang  : 44|4@1+ (1.000000,0.000000) [0.000000|15.000000] "" Vector__XXX
 SG_ WFS_ID_Geb_autorisiert_in_Kl15  : 48|1@1+ (1.000000,0.000000) [0.000000|1.000000] "" Vector__XXX
 SG_ BH_Fernlicht  : 49|1@1+ (1.000000,0.000000) [0.000000|1.000000] "" Vector__XXX
 SG_ BH_Blinker_li  : 50|1@1+ (1.000000,0.000000) [0.000000|1.000000] "" Vector__XXX
 SG_ BH_Blinker_re  : 51|1@1+ (1.000000,0.000000) [0.000000|1.000000] "" Vector__XXX
 SG_ BCM1_OBD_FStatus_ATemp  : 52|4@1+ (1.000000,0.000000) [0.000000|15.000000] "" Vector__XXX
 SG_ BCM1_Aussen_Temp_ungef  : 56|8@1+ (0.500000,-50.000000) [-50.000000|76.000000] "Unit_DegreCelsi" Vector__XXX

BO_ 173 Getriebe_11: 8 Motor_BEV
 SG_ Getriebe_11_CRC  : 0|8@1+ (1.000000,0.000000) [0.000000|255.000000] "" ICAS1_Gateway
 SG_ Getriebe_11_BZ  : 8|4@1+ (1.000000,0.000000) [0.000000|15.000000] "" ICAS1_Gateway
 SG_ GE_MMom_Soll_02  : 12|10@1+ (1.000000,-509.000000) [-509.000000|509.000000] "" ICAS1_Gateway
 SG_ GE_MMom_Vorhalt_02  : 22|10@1+ (1.000000,-509.000000) [-509.000000|509.000000] "" ICAS1_Gateway
 SG_ GE_Uefkt  : 32|10@1+ (0.100000,0.000000) [0.000000|102.200000] "" ICAS1_Gateway
 SG_ GE_Fahrstufe  : 42|4@1+ (1.000000,0.000000) [0.000000|15.000000] "" ICAS1_Gateway
 SG_ GE_Schaltablauf  : 47|2@1+ (1.000000,0.000000) [0.000000|3.000000] "" ICAS1_Gateway
 SG_ GE_Uefkt_unplausibel  : 49|1@1+ (1.000000,0.000000) [0.000000|1.000000] "" ICAS1_Gateway
 SG_ GE_MMom_Status_02  : 50|3@1+ (1.000000,0.000000) [0.000000|7.000000] "" ICAS1_Gateway
 SG_ GE_Status_Kraftschluss  : 53|3@1+ (1.000000,0.000000) [0.000000|7.000000] "" ICAS1_Gateway
 SG_ GE_MMom_Status  : 56|2@1+ (1.000000,0.000000) [0.000000|3.000000] "" ICAS1_Gateway
 SG_ GE_Freig_MMom_Vorhalt  : 58|1@1+ (1.000000,0.000000) [0.000000|1.000000] "" ICAS1_Gateway
 SG_ GE_Verbot_Ausblendung  : 59|1@1+ (1.000000,0.000000) [0.000000|1.000000] "" ICAS1_Gateway
 SG_ GE_Zielgang  : 60|4@1+ (1.000000,0.000000) [0.000000|15.000000] "" ICAS1_Gateway

BU_:  Airbag BAP_Tester ICAS1_Gateway ICAS1_KommunikationsServer LE1 LE2 Motor_BEV Schaltbetaetigung

BO_ 252 ESC_51: 48 ICAS1_Gateway
 SG_ ESC_51_CRC  : 0|8@1+ (1.000000,0.000000) [0.000000|255.000000] "" Motor_BEV
 SG_ ESC_51_BZ  : 8|4@1+ (1.000000,0.000000) [0.000000|15.000000] "" Motor_BEV
 SG_ ESC_aktBr_Modus  : 12|2@1+ (1.000000,0.000000) [0.000000|3.000000] "" Vector__XXX
 SG_ ESC_Blending_Solldruck  : 14|10@1+ (0.250000,0.000000) [0.000000|250.000000] "Unit_Bar" Vector__XXX
 SG_ ESC_aktBr_Volumenstrom  : 24|16@1+ (0.007812,-252.000000) [-252.000000|252.000000] "Unit_MilliLiterPerSec" Vector__XXX
 SG_ ESC_EBKV_Kraftblending_Modus  : 40|2@1+ (1.000000,0.000000) [0.000000|3.000000] "" Vector__XXX
 SG_ ESC_Bremsdruck_Modell  : 42|10@1+ (0.250000,0.000000) [0.000000|250.000000] "Unit_Bar" Motor_BEV
 SG_ ESC_Bremsdruck_02  : 52|10@1+ (0.300000,-30.000000) [-30.000000|276.600000] "Unit_Bar" Vector__XXX
 SG_ ESC_QBit_Bremsdruck_02  : 62|1@1+ (1.000000,0.000000) [0.000000|1.000000] "" Vector__XXX
 SG_ ESP_HL_Radgeschw_02  : 64|16@1+ (0.007500,0.000000) [0.000000|491.490000] "Unit_KiloMeterPerHour" Airbag LE1 LE2 Motor_BEV
 SG_ ESP_HR_Radgeschw_02  : 80|16@1+ (0.007500,0.000000) [0.000000|491.490000] "Unit_KiloMeterPerHour" Airbag LE1 LE2 Motor_BEV
 SG_ ESP_VL_Radgeschw_02  : 96|16@1+ (0.007500,0.000000) [0.000000|491.490000] "Unit_KiloMeterPerHour" Airbag LE1 LE2 Motor_BEV
 SG_ ESP_VR_Radgeschw_02  : 112|16@1+ (0.007500,0.000000) [0.000000|491.490000] "Unit_KiloMeterPerHour" Airbag LE1 LE2 Motor_BEV
 SG_ ESP_FZR_uebersteuern  : 128|8@1+ (0.004000,0.000000) [0.000000|1.000000] "" Vector__XXX
 SG_ ESP_FZR_untersteuern  : 136|8@1+ (0.004000,0.000000) [0.000000|1.000000] "" Vector__XXX
 SG_ ESC_Anf_Mindestreku  : 144|1@1+ (1.000000,0.000000) [0.000000|1.000000] "" Motor_BEV
 SG_ ESC_GMV_aktiv  : 145|3@1+ (1.000000,0.000000) [0.000000|7.000000] "" Vector__XXX
 SG_ ESC_GMV_nicht_verfuegbar  : 148|1@1+ (1.000000,0.000000) [0.000000|1.000000] "" Vector__XXX
 SG_ ESC_Status_vRef_Stuetzeingriff  : 149|1@1+ (1.000000,0.000000) [0.000000|1.000000] "" Motor_BEV
 SG_ FDR_Allradverteilung_aktiv  : 150|1@1+ (1.000000,0.000000) [0.000000|1.000000] "" Vector__XXX
 SG_ FDR_Anf_Allradbetrieb  : 151|1@1+ (1.000000,0.000000) [0.000000|1.000000] "" Vector__XXX
 SG_ ESP_HL_Bremsmoment  : 152|8@1+ (20.000000,0.000000) [0.000000|5060.000000] "Unit_NewtoMeter" Motor_BEV
 SG_ ESP_HR_Bremsmoment  : 160|8@1+ (20.000000,0.000000) [0.000000|5060.000000] "Unit_NewtoMeter" Motor_BEV
 SG_ ESP_VR_Bremsmoment  : 168|8@1+ (40.000000,0.000000) [0.000000|10120.000000] "Unit_NewtoMeter" Motor_BEV
 SG_ ESP_VL_Bremsmoment  : 176|8@1+ (40.000000,0.000000) [0.000000|10120.000000] "Unit_NewtoMeter" Motor_BEV
 SG_ ESP_FDR_uebersteuern  : 184|8@1+ (0.004000,0.000000) [0.000000|1.000000] "" Motor_BEV
 SG_ ESP_FDR_untersteuern  : 192|8@1+ (0.004000,0.000000) [0.000000|1.000000] "" Motor_BEV
 SG_ TSMomBegrenzung  : 268|12@1+ (3.000000,-12279.000000) [-12279.000000|0.000000] "" Motor_BEV
 SG_ ESC_Allrad_Anteil_max_sek  : 280|9@1+ (0.200000,0.000000) [0.000000|100.000000] "Unit_PerCent" Motor_BEV
 SG_ ESC_Allrad_Anteil_min_sek  : 289|9@1+ (0.200000,0.000000) [0.000000|100.000000] "Unit_PerCent" Motor_BEV
 SG_ ESC_Status_Eingriff  : 298|2@1+ (1.000000,0.000000) [0.000000|3.000000] "" Motor_BEV
 SG_ ESC_Status_Eingriff_sek  : 300|2@1+ (1.000000,0.000000) [0.000000|3.000000] "" Motor_BEV
 SG_ ESC_MomRad_Eingriff  : 302|13@1+ (3.000000,-12279.000000) [-12279.000000|12279.000000] "Unit_None" Motor_BEV
 SG_ ESC_MomRad_Eingriff_sek  : 315|13@1+ (3.000000,-12279.000000) [-12279.000000|12279.000000] "Unit_None" Motor_BEV
 SG_ ESC_Achsdrehzahl_Max  : 328|14@1+ (0.400000,-800.000000) [-800.000000|5752.400000] "Unit_MinutInver" Motor_BEV
 SG_ ESC_Achsdrehzahl_Min  : 342|14@1+ (0.400000,-800.000000) [-800.000000|5752.400000] "Unit_MinutInver" Motor_BEV
 SG_ ESC_Achsdrehzahl_Max_sek  : 356|14@1+ (0.400000,-800.000000) [-800.000000|5752.400000] "Unit_MinutInver" Motor_BEV
 SG_ ESC_Achsdrehzahl_Min_sek  : 370|14@1+ (0.400000,-800.000000) [-800.000000|5752.400000] "Unit_MinutInver" Motor_BEV

BO_ 2463978647 ESC_52: 16 ICAS1_Gateway
 SG_ ESP_ACC_LDE  : 12|1@1+ (1.000000,0.000000) [0.000000|1.000000] "" Vector__XXX
 SG_ ESP_Allrad_Antrieb  : 13|1@1+ (1.000000,0.000000) [0.000000|1.000000] "" Vector__XXX
 SG_ ESP_Codierung_ADS  : 14|2@1+ (1.000000,0.000000) [0.000000|3.000000] "" Vector__XXX
 SG_ ESP_RTA_HL  : 16|8@1+ (0.048828,-6.201170) [-6.201170|6.152346] "Unit_PerCent" Motor_BEV
 SG_ ESP_RTA_HR  : 24|8@1+ (0.048828,-6.201170) [-6.201170|6.152346] "Unit_PerCent" Motor_BEV
 SG_ ESP_RTA_VR  : 32|8@1+ (0.048828,-6.201170) [-6.201170|6.152346] "Unit_PerCent" Motor_BEV
 SG_ OBD_Fehler_Radsensor_HL  : 40|4@1+ (1.000000,0.000000) [0.000000|15.000000] "" Motor_BEV
 SG_ OBD_Fehler_Radsensor_HR  : 44|4@1+ (1.000000,0.000000) [0.000000|15.000000] "" Motor_BEV
 SG_ OBD_Fehler_Radsensor_VL  : 48|4@1+ (1.000000,0.000000) [0.000000|15.000000] "" Motor_BEV
 SG_ OBD_Fehler_Radsensor_VR  : 52|4@1+ (1.000000,0.000000) [0.000000|15.000000] "" Motor_BEV
 SG_ ESP_Qualifizierung_Antriebsart  : 56|1@1+ (1.000000,0.000000) [0.000000|1.000000] "" Vector__XXX
 SG_ ESP_Offroad_Modus  : 57|1@1+ (1.000000,0.000000) [0.000000|1.000000] "" Vector__XXX
 SG_ ESP_MKB_ausloesbar  : 58|1@1+ (1.000000,0.000000) [0.000000|1.000000] "" Vector__XXX
 SG_ ESP_Stat_FallBack_eBKV  : 59|1@1+ (1.000000,0.000000) [0.000000|1.000000] "" Vector__XXX
 SG_ ESP_CM_Variante  : 60|1@1+ (1.000000,0.000000) [0.000000|1.000000] "" Vector__XXX
 SG_ ESP_OBD_Status  : 61|1@1+ (1.000000,0.000000) [0.000000|1.000000] "" Motor_BEV
 SG_ ESP_Rollenmodus_Deaktivieren  : 62|1@1+ (1.000000,0.000000) [0.000000|1.000000] "" Motor_BEV
 SG_ ESP_nachtr_Stopp_Anf  : 63|1@1+ (1.000000,0.000000) [0.000000|1.000000] "" Vector__XXX

BO_ 2527679683 ESC_ASM_01: 8 ICAS1_Gateway
 SG_ ESC_ASM_Ereignis  : 0|8@1+ (1.000000,0.000000) [1.000000|254.000000] "Unit_None" Airbag
 SG_ ESC_ASM_Zeitstempel  : 8|8@1+ (0.080000,0.000000) [0.000000|20.320000] "Unit_Secon" Airbag
 SG_ ESC_ASM_Data_1  : 16|8@1+ (1.000000,0.000000) [0.000000|255.000000] "" Airbag
 SG_ ESC_ASM_Data_2  : 24|8@1+ (1.000000,0.000000) [0.000000|255.000000] "" Airbag
 SG_ ESC_ASM_Data_3  : 32|8@1+ (1.000000,0.000000) [0.000000|255.000000] "" Airbag
 SG_ ESC_ASM_Data_4  : 40|8@1+ (1.000000,0.000000) [0.000000|255.000000] "" Airbag
 SG_ ESC_ASM_Data_5  : 48|8@1+ (1.000000,0.000000) [0.000000|255.000000] "" Airbag
 SG_ ESC_ASM_Data_6  : 56|8@1+ (1.000000,0.000000) [0.000000|255.000000] "" Airbag

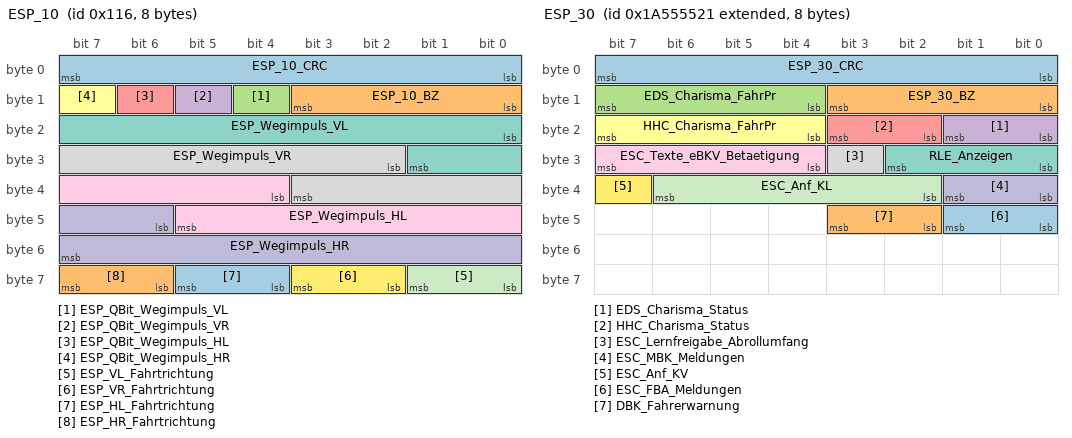
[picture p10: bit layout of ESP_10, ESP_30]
BO_ 278 ESP_10: 8 ICAS1_Gateway
 SG_ ESP_10_CRC  : 0|8@1+ (1.000000,0.000000) [0.000000|255.000000] "" Vector__XXX
 SG_ ESP_10_BZ  : 8|4@1+ (1.000000,0.000000) [0.000000|15.000000] "" Vector__XXX
 SG_ ESP_QBit_Wegimpuls_VL  : 12|1@1+ (1.000000,0.000000) [0.000000|1.000000] "" Motor_BEV
 SG_ ESP_QBit_Wegimpuls_VR  : 13|1@1+ (1.000000,0.000000) [0.000000|1.000000] "" Motor_BEV
 SG_ ESP_QBit_Wegimpuls_HL  : 14|1@1+ (1.000000,0.000000) [0.000000|1.000000] "" Motor_BEV
 SG_ ESP_QBit_Wegimpuls_HR  : 15|1@1+ (1.000000,0.000000) [0.000000|1.000000] "" Motor_BEV
 SG_ ESP_Wegimpuls_VL  : 16|10@1+ (1.000000,0.000000) [0.000000|1000.000000] "" Motor_BEV
 SG_ ESP_Wegimpuls_VR  : 26|10@1+ (1.000000,0.000000) [0.000000|1000.000000] "" Motor_BEV
 SG_ ESP_Wegimpuls_HL  : 36|10@1+ (1.000000,0.000000) [0.000000|1000.000000] "" Motor_BEV
 SG_ ESP_Wegimpuls_HR  : 46|10@1+ (1.000000,0.000000) [0.000000|1000.000000] "" Motor_BEV
 SG_ ESP_VL_Fahrtrichtung  : 56|2@1+ (1.000000,0.000000) [0.000000|3.000000] "" Motor_BEV
 SG_ ESP_VR_Fahrtrichtung  : 58|2@1+ (1.000000,0.000000) [0.000000|3.000000] "" Motor_BEV
 SG_ ESP_HL_Fahrtrichtung  : 60|2@1+ (1.000000,0.000000) [0.000000|3.000000] "" Motor_BEV
 SG_ ESP_HR_Fahrtrichtung  : 62|2@1+ (1.000000,0.000000) [0.000000|3.000000] "" Motor_BEV

BO_ 1629 ESP_20: 8 ICAS1_Gateway
 SG_ ESP_20_CRC  : 0|8@1+ (1.000000,0.000000) [0.000000|255.000000] "" Vector__XXX
 SG_ ESP_20_BZ  : 8|4@1+ (1.000000,0.000000) [0.000000|15.000000] "" Vector__XXX
 SG_ BR_Systemart  : 12|2@1+ (1.000000,0.000000) [0.000000|3.000000] "" Vector__XXX
 SG_ ESP_SpannungsAnf_02  : 14|2@1+ (1.000000,0.000000) [0.000000|3.000000] "" Vector__XXX
 SG_ ESP_Zaehnezahl  : 16|8@1+ (1.000000,0.000000) [0.000000|255.000000] "" Vector__XXX
 SG_ ESP_Charisma_FahrPr  : 24|4@1+ (1.000000,0.000000) [0.000000|15.000000] "" Vector__XXX
 SG_ ESP_Charisma_Status  : 28|2@1+ (1.000000,0.000000) [0.000000|3.000000] "" Vector__XXX
 SG_ ESP_Wiederstart_Anz_01  : 30|1@1+ (1.000000,0.000000) [0.000000|1.000000] "" Vector__XXX
 SG_ ESP_Wiederstart_Anz_02  : 31|1@1+ (1.000000,0.000000) [0.000000|1.000000] "" Vector__XXX
 SG_ ESP_Wiederstart_Anz_03  : 32|1@1+ (1.000000,0.000000) [0.000000|1.000000] "" Vector__XXX
 SG_ ESP_Wiederstart_Anz_04  : 33|1@1+ (1.000000,0.000000) [0.000000|1.000000] "" Vector__XXX
 SG_ ESP_Stoppverbot_Anz_01  : 34|1@1+ (1.000000,0.000000) [0.000000|1.000000] "" Vector__XXX
 SG_ ESP_Stoppverbot_Anz_02  : 35|1@1+ (1.000000,0.000000) [0.000000|1.000000] "" Vector__XXX
 SG_ ESP_Stoppverbot_Anz_03  : 36|1@1+ (1.000000,0.000000) [0.000000|1.000000] "" Vector__XXX
 SG_ ESP_Stoppverbot_Anz_04  : 37|1@1+ (1.000000,0.000000) [0.000000|1.000000] "" Vector__XXX
 SG_ ESP_Stoppverbot_Anz_05  : 38|1@1+ (1.000000,0.000000) [0.000000|1.000000] "" Vector__XXX
 SG_ ESP_Stoppverbot_Anz_06  : 39|1@1+ (1.000000,0.000000) [0.000000|1.000000] "" Vector__XXX
 SG_ ESP_Stoppverbot_Anz_07  : 40|1@1+ (1.000000,0.000000) [0.000000|1.000000] "" Vector__XXX
 SG_ ESP_Stoppverbot_Anz_Std  : 41|1@1+ (1.000000,0.000000) [0.000000|1.000000] "" Vector__XXX
 SG_ ESP_Dachrelingsensor  : 42|2@1+ (1.000000,0.000000) [0.000000|3.000000] "" Vector__XXX
 SG_ ESP_Stoppverbot_Anz_08  : 44|1@1+ (1.000000,0.000000) [0.000000|1.000000] "" Vector__XXX
 SG_ HDC_Charisma_FahrPr  : 45|4@1+ (1.000000,0.000000) [0.000000|15.000000] "" Vector__XXX
 SG_ HDC_Charisma_Status  : 49|2@1+ (1.000000,0.000000) [0.000000|3.000000] "" Vector__XXX
 SG_ BR_QBit_Reifenumfang  : 51|1@1+ (1.000000,0.000000) [0.000000|1.000000] "" LE1 LE2
 SG_ BR_Reifenumfang  : 52|12@1+ (1.000000,0.000000) [0.000000|4095.000000] "Unit_MilliMeter" LE1 LE2

BO_ 253 ESP_21: 8 ICAS1_Gateway
 SG_ ESP_21_CRC  : 0|8@1+ (1.000000,0.000000) [0.000000|255.000000] "" Airbag LE1 LE2 Motor_BEV
 SG_ ESP_21_BZ  : 8|4@1+ (1.000000,0.000000) [0.000000|15.000000] "" Airbag LE1 LE2 Motor_BEV
 SG_ BR_Eingriffsmoment  : 12|10@1+ (1.000000,-509.000000) [-509.000000|509.000000] "" Vector__XXX
 SG_ ESP_PLA_Bremseingriff  : 22|1@1+ (1.000000,0.000000) [0.000000|1.000000] "" Vector__XXX
 SG_ ESP_Diagnose  : 23|1@1+ (1.000000,0.000000) [0.000000|1.000000] "" Vector__XXX
 SG_ ESC_Reku_Freigabe  : 24|1@1+ (1.000000,0.000000) [0.000000|1.000000] "" Motor_BEV
 SG_ ESC_v_Signal_Qualifier_High_Low  : 25|3@1+ (1.000000,0.000000) [0.000000|7.000000] "" Airbag
 SG_ ESP_Vorsteuerung  : 28|1@1+ (1.000000,0.000000) [0.000000|1.000000] "" Motor_BEV
 SG_ ESP_AWV3_Brems_aktiv  : 29|1@1+ (1.000000,0.000000) [0.000000|1.000000] "" Vector__XXX
 SG_ OBD_Schlechtweg  : 30|1@1+ (1.000000,0.000000) [0.000000|1.000000] "" Vector__XXX
 SG_ OBD_QBit_Schlechtweg  : 31|1@1+ (1.000000,0.000000) [0.000000|1.000000] "" Vector__XXX
 SG_ ESP_v_Signal  : 32|16@1+ (0.010000,0.000000) [0.000000|655.320000] "Unit_KiloMeterPerHour" Airbag LE1 LE2 Motor_BEV
 SG_ ASR_Tastung_passiv  : 48|1@1+ (1.000000,0.000000) [0.000000|1.000000] "" Airbag Motor_BEV
 SG_ ESP_Tastung_passiv  : 49|1@1+ (1.000000,0.000000) [0.000000|1.000000] "" Airbag Motor_BEV
 SG_ ESP_Systemstatus  : 50|1@1+ (1.000000,0.000000) [0.000000|1.000000] "" Motor_BEV
 SG_ ASR_Schalteingriff  : 51|2@1+ (1.000000,0.000000) [0.000000|3.000000] "" Vector__XXX
 SG_ ESP_Haltebestaetigung  : 53|1@1+ (1.000000,0.000000) [0.000000|1.000000] "" Vector__XXX
 SG_ ESP_MKB_Abbruch_Geschw  : 54|1@1+ (1.000000,0.000000) [0.000000|1.000000] "" Vector__XXX
 SG_ ESP_QBit_v_Signal  : 55|1@1+ (1.000000,0.000000) [0.000000|1.000000] "" LE1 LE2 Motor_BEV
 SG_ ABS_Bremsung  : 56|1@1+ (1.000000,0.000000) [0.000000|1.000000] "" Airbag Motor_BEV
 SG_ ASR_Anf  : 57|1@1+ (1.000000,0.000000) [0.000000|1.000000] "" Vector__XXX
 SG_ MSR_Anf  : 58|1@1+ (1.000000,0.000000) [0.000000|1.000000] "" Vector__XXX
 SG_ EBV_Eingriff  : 59|1@1+ (1.000000,0.000000) [0.000000|1.000000] "" Vector__XXX
 SG_ EDS_Eingriff  : 60|1@1+ (1.000000,0.000000) [0.000000|1.000000] "" Motor_BEV
 SG_ ESP_Eingriff  : 61|1@1+ (1.000000,0.000000) [0.000000|1.000000] "" Airbag Motor_BEV
 SG_ ESP_ASP  : 62|1@1+ (1.000000,0.000000) [0.000000|1.000000] "" Vector__XXX
 SG_ ESP_Anhaltevorgang_ACC_aktiv  : 63|1@1+ (1.000000,0.000000) [0.000000|1.000000] "" Vector__XXX

BO_ 795 ESP_24: 8 ICAS1_Gateway
 SG_ ESP_24_CRC  : 0|8@1+ (1.000000,0.000000) [0.000000|255.000000] "" Vector__XXX
 SG_ ESP_24_BZ  : 8|4@1+ (1.000000,0.000000) [0.000000|15.000000] "" Vector__XXX
 SG_ ESP_Lampe  : 12|1@1+ (1.000000,0.000000) [0.000000|1.000000] "" Motor_BEV
 SG_ ABS_Lampe  : 13|1@1+ (1.000000,0.000000) [0.000000|1.000000] "" Vector__XXX
 SG_ BK_Lampe_02  : 14|2@1+ (1.000000,0.000000) [0.000000|3.000000] "" Vector__XXX
 SG_ TC_Lampe  : 16|1@1+ (1.000000,0.000000) [0.000000|1.000000] "" Vector__XXX
 SG_ ESP_m_Raddrehz  : 17|15@1+ (0.002000,0.000000) [0.000000|65.278000] "Unit_Hertz" Vector__XXX
 SG_ ESP_Textanzeigen_03  : 32|5@1+ (1.000000,0.000000) [0.000000|31.000000] "" Vector__XXX
 SG_ ESP_Meldungen  : 37|3@1+ (1.000000,0.000000) [0.000000|7.000000] "" Vector__XXX
 SG_ ESP_Wegimp_VA  : 40|11@1+ (1.000000,0.000000) [0.000000|2047.000000] "" Vector__XXX
 SG_ ESP_Fehlerstatus_Wegimp  : 51|1@1+ (1.000000,0.000000) [0.000000|1.000000] "" Vector__XXX
 SG_ ESP_Wegimp_Ueberlauf  : 52|1@1+ (1.000000,0.000000) [0.000000|1.000000] "" Vector__XXX
 SG_ ESP_QBit_Wegimp_VA  : 53|1@1+ (1.000000,0.000000) [0.000000|1.000000] "" Vector__XXX
 SG_ ESP_HDC_FktLampe  : 54|1@1+ (1.000000,0.000000) [0.000000|1.000000] "" Vector__XXX
 SG_ ESP_Off_Lampe  : 55|1@1+ (1.000000,0.000000) [0.000000|1.000000] "" Airbag
 SG_ ESP_HDC_Regelgeschw  : 56|7@1+ (0.320000,0.000000) [0.320000|39.680000] "Unit_KiloMeterPerHour" Vector__XXX
 SG_ ESP_BKV_Warnung  : 63|1@1+ (1.000000,0.000000) [0.000000|1.000000] "" Vector__XXX

BO_ 2589283617 ESP_30: 8 ICAS1_Gateway
 SG_ ESP_30_CRC  : 0|8@1+ (1.000000,0.000000) [0.000000|255.000000] "" Vector__XXX
 SG_ ESP_30_BZ  : 8|4@1+ (1.000000,0.000000) [0.000000|15.000000] "" Vector__XXX
 SG_ EDS_Charisma_FahrPr  : 12|4@1+ (1.000000,0.000000) [0.000000|15.000000] "" Vector__XXX
 SG_ EDS_Charisma_Status  : 16|2@1+ (1.000000,0.000000) [0.000000|3.000000] "" Vector__XXX
 SG_ HHC_Charisma_Status  : 18|2@1+ (1.000000,0.000000) [0.000000|3.000000] "" Vector__XXX
 SG_ HHC_Charisma_FahrPr  : 20|4@1+ (1.000000,0.000000) [0.000000|15.000000] "" Vector__XXX
 SG_ RLE_Anzeigen  : 24|3@1+ (1.000000,0.000000) [0.000000|7.000000] "" Vector__XXX
 SG_ ESC_Lernfreigabe_Abrollumfang  : 27|1@1+ (1.000000,0.000000) [0.000000|1.000000] "" Vector__XXX
 SG_ ESC_Texte_eBKV_Betaetigung  : 28|4@1+ (1.000000,0.000000) [0.000000|15.000000] "" Vector__XXX
 SG_ ESC_MBK_Meldungen  : 32|2@1+ (1.000000,0.000000) [0.000000|3.000000] "" Vector__XXX
 SG_ ESC_Anf_KL  : 34|5@1+ (3.225806,0.000000) [0.000000|100.000000] "Unit_PerCent" Motor_BEV
 SG_ ESC_Anf_KV  : 39|1@1+ (1.000000,0.000000) [0.000000|1.000000] "" Motor_BEV
 SG_ ESC_FBA_Meldungen  : 40|2@1+ (1.000000,0.000000) [0.000000|3.000000] "" Vector__XXX
 SG_ DBK_Fahrerwarnung  : 42|2@1+ (1.000000,0.000000) [0.000000|3.000000] "" Vector__XXX

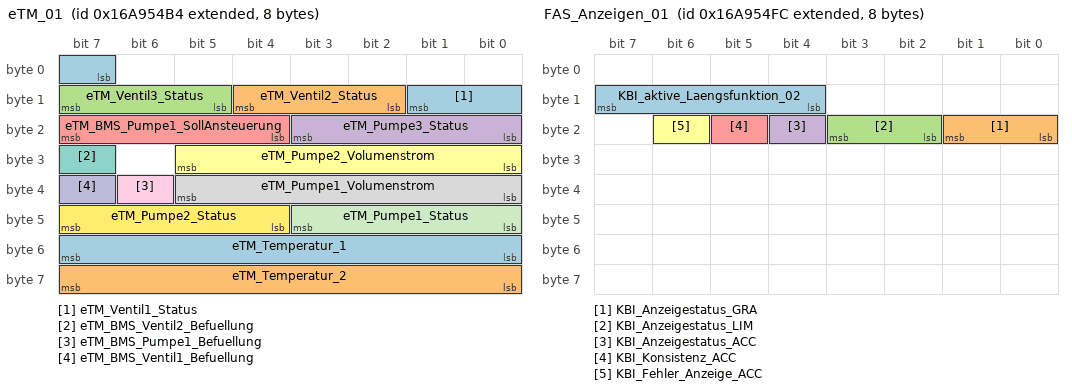
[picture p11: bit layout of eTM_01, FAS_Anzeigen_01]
BO_ 2527679668 eTM_01: 8 Motor_BEV
 SG_ eTM_Ventil1_Status  : 7|3@1+ (1.000000,0.000000) [0.000000|7.000000] "" ICAS1_Gateway
 SG_ eTM_Ventil2_Status  : 10|3@1+ (1.000000,0.000000) [0.000000|7.000000] "" ICAS1_Gateway
 SG_ eTM_Ventil3_Status  : 13|3@1+ (1.000000,0.000000) [0.000000|7.000000] "" ICAS1_Gateway
 SG_ eTM_Pumpe3_Status  : 16|4@1+ (10.000000,0.000000) [0.000000|130.000000] "Unit_PerCent" ICAS1_Gateway
 SG_ eTM_BMS_Pumpe1_SollAnsteuerung  : 20|4@1+ (10.000000,0.000000) [0.000000|130.000000] "Unit_PerCent" ICAS1_Gateway
 SG_ eTM_Pumpe2_Volumenstrom  : 24|6@1+ (0.500000,0.000000) [0.000000|30.500000] "Unit_LiterPerMinut" ICAS1_Gateway LE1 LE2
 SG_ eTM_BMS_Ventil2_Befuellung  : 31|1@1+ (1.000000,0.000000) [0.000000|1.000000] "" ICAS1_Gateway
 SG_ eTM_Pumpe1_Volumenstrom  : 32|6@1+ (0.500000,0.000000) [0.000000|30.500000] "Unit_LiterPerMinut" ICAS1_Gateway LE1 LE2
 SG_ eTM_BMS_Pumpe1_Befuellung  : 38|1@1+ (1.000000,0.000000) [0.000000|1.000000] "" ICAS1_Gateway
 SG_ eTM_BMS_Ventil1_Befuellung  : 39|1@1+ (1.000000,0.000000) [0.000000|1.000000] "" ICAS1_Gateway
 SG_ eTM_Pumpe1_Status  : 40|4@1+ (10.000000,0.000000) [0.000000|130.000000] "Unit_PerCent" ICAS1_Gateway LE1 LE2
 SG_ eTM_Pumpe2_Status  : 44|4@1+ (10.000000,0.000000) [0.000000|130.000000] "Unit_PerCent" ICAS1_Gateway LE1 LE2
 SG_ eTM_Temperatur_1  : 48|8@1+ (0.750000,-40.000000) [-40.000000|149.750000] "Unit_DegreCelsi" ICAS1_Gateway LE1 LE2
 SG_ eTM_Temperatur_2  : 56|8@1+ (0.750000,-40.000000) [-40.000000|149.750000] "Unit_DegreCelsi" ICAS1_Gateway LE1 LE2

BO_ 2527679740 FAS_Anzeigen_01: 8 ICAS1_KommunikationsServer
 SG_ KBI_aktive_Laengsfunktion_02  : 12|4@1+ (1.000000,0.000000) [0.000000|15.000000] "" Motor_BEV
 SG_ KBI_Anzeigestatus_GRA  : 16|2@1+ (1.000000,0.000000) [0.000000|3.000000] "" Motor_BEV
 SG_ KBI_Anzeigestatus_LIM  : 18|2@1+ (1.000000,0.000000) [0.000000|3.000000] "" Motor_BEV
 SG_ KBI_Anzeigestatus_ACC  : 20|1@1+ (1.000000,0.000000) [0.000000|1.000000] "" Vector__XXX
 SG_ KBI_Konsistenz_ACC  : 21|1@1+ (1.000000,0.000000) [0.000000|1.000000] "" Vector__XXX
 SG_ KBI_Fehler_Anzeige_ACC  : 22|1@1+ (1.000000,0.000000) [0.000000|1.000000] "" Vector__XXX

BO_ 2589283684 FoD_01: 8 ICAS1_Gateway
 SG_ GRA_FoD_Status  : 58|2@1+ (1.000000,0.000000) [0.000000|3.000000] "" Vector__XXX
 SG_ FoD_Transmission_Info  : 60|2@1+ (1.000000,0.000000) [0.000000|3.000000] "" Motor_BEV

BO_ 2549875574 FoD_MO_01_Req: 8 ICAS1_Gateway
 SG_ FoD_MO_01_Req_Data  : 0|64@1+ (1.000000,0.000000) [0.000000|18446744073709551616.000000] "" Motor_BEV

BO_ 2550006646 FoD_MO_01_Resp: 8 Motor_BEV
 SG_ FoD_MO_01_Resp_Data  : 0|64@1+ (1.000000,0.000000) [0.000000|18446744073709551616.000000] "" ICAS1_Gateway

BO_ 987 Gateway_72: 8 ICAS1_Gateway
 SG_ BCM_01_alt  : 0|1@1+ (1.000000,0.000000) [0.000000|1.000000] "" Airbag
 SG_ SMLS_01_alt  : 1|1@1+ (1.000000,0.000000) [0.000000|1.000000] "" Vector__XXX
 SG_ ZV_02_alt  : 2|1@1+ (1.000000,0.000000) [0.000000|1.000000] "" Vector__XXX
 SG_ Wischer_01_alt  : 3|1@1+ (1.000000,0.000000) [0.000000|1.000000] "" Vector__XXX
 SG_ Anhaenger_01_alt  : 4|1@1+ (1.000000,0.000000) [0.000000|1.000000] "" Airbag
 SG_ Klima_Sensor_02_alt  : 5|1@1+ (1.000000,0.000000) [0.000000|1.000000] "" Vector__XXX
 SG_ Verdeck_01_alt  : 6|1@1+ (1.000000,0.000000) [0.000000|1.000000] "" Vector__XXX
 SG_ Klima_11_alt  : 7|1@1+ (1.000000,0.000000) [0.000000|1.000000] "" Vector__XXX
 SG_ WFS_01_alt  : 8|1@1+ (1.000000,0.000000) [0.000000|1.000000] "" Vector__XXX
 SG_ Licht_Anf_01_alt  : 9|1@1+ (1.000000,0.000000) [0.000000|1.000000] "" Vector__XXX
 SG_ ZV_verriegelt_extern_soll  : 10|1@1+ (1.000000,0.000000) [0.000000|1.000000] "" Vector__XXX
 SG_ BH_Lichthupe  : 11|1@1+ (1.000000,0.000000) [0.000000|1.000000] "" Vector__XXX
 SG_ WFS_Klemmenfreigabe  : 12|1@1+ (1.000000,0.000000) [0.000000|1.000000] "" Vector__XXX
 SG_ ZV_Tankklappe_offen  : 13|1@1+ (1.000000,0.000000) [0.000000|1.000000] "" Vector__XXX
 SG_ AAG_Anhaenger_abgesteckt  : 14|1@1+ (1.000000,0.000000) [0.000000|1.000000] "" Vector__XXX
 SG_ BCM1_LDS_Stellung  : 15|3@1+ (1.000000,0.000000) [0.000000|7.000000] "" Vector__XXX
 SG_ VS_Verdeck_Anf  : 18|1@1+ (1.000000,0.000000) [0.000000|1.000000] "" Vector__XXX
 SG_ VS_VD_entriegelt  : 19|1@1+ (1.000000,0.000000) [0.000000|1.000000] "" Vector__XXX
 SG_ ZV_HFS_offen  : 20|1@1+ (1.000000,0.000000) [0.000000|1.000000] "" Vector__XXX
 SG_ ZV_HBFS_offen  : 21|1@1+ (1.000000,0.000000) [0.000000|1.000000] "" Vector__XXX
 SG_ VS_VD_offen_ver  : 22|1@1+ (1.000000,0.000000) [0.000000|1.000000] "" Vector__XXX
 SG_ VS_VD_zu_ver  : 23|1@1+ (1.000000,0.000000) [0.000000|1.000000] "" Vector__XXX
 SG_ ZV_BT_offen  : 24|1@1+ (1.000000,0.000000) [0.000000|1.000000] "" Vector__XXX
 SG_ BCM1_Rueckfahrlicht_Schalter  : 25|1@1+ (1.000000,0.000000) [0.000000|1.000000] "" Airbag Motor_BEV
 SG_ ZV_FT_offen  : 26|1@1+ (1.000000,0.000000) [0.000000|1.000000] "" Vector__XXX
 SG_ Wischer_vorne_aktiv  : 27|1@1+ (1.000000,0.000000) [0.000000|1.000000] "" Vector__XXX
 SG_ AAG_Anhaenger_erkannt  : 28|1@1+ (1.000000,0.000000) [0.000000|1.000000] "" Airbag
 SG_ BCM1_MH_Schalter  : 29|1@1+ (1.000000,0.000000) [0.000000|1.000000] "" Vector__XXX
 SG_ ZV_HD_offen  : 30|1@1+ (1.000000,0.000000) [0.000000|1.000000] "" Vector__XXX
 SG_ Waschen_vorne_aktiv  : 31|1@1+ (1.000000,0.000000) [0.000000|1.000000] "" Vector__XXX
 SG_ KL_Thermomanagement  : 32|2@1+ (1.000000,0.000000) [0.000000|3.000000] "" Vector__XXX
 SG_ WFS_Schluessel_Fahrberecht  : 34|4@1+ (1.000000,0.000000) [0.000000|15.000000] "" Vector__XXX
 SG_ BCM_Rueckfahrlicht_Anf  : 38|1@1+ (1.000000,0.000000) [0.000000|1.000000] "" Vector__XXX
 SG_ WWSs_01_alt  : 39|1@1+ (1.000000,0.000000) [0.000000|1.000000] "" Vector__XXX
 SG_ BCM_Tankklappensteller_Fehler  : 40|1@1+ (1.000000,0.000000) [0.000000|1.000000] "" Vector__XXX
 SG_ AAG_LED_aktiv  : 41|1@1+ (1.000000,0.000000) [0.000000|1.000000] "" Vector__XXX
 SG_ ZV_verriegelt_soll  : 42|2@1+ (1.000000,0.000000) [0.000000|3.000000] "" Vector__XXX
 SG_ ZV_Schluessel_Zugang  : 44|4@1+ (1.000000,0.000000) [0.000000|15.000000] "" Vector__XXX
 SG_ WFS_ID_Geb_autorisiert_in_Kl15  : 48|1@1+ (1.000000,0.000000) [0.000000|1.000000] "" Vector__XXX
 SG_ BH_Fernlicht  : 49|1@1+ (1.000000,0.000000) [0.000000|1.000000] "" Vector__XXX
 SG_ BH_Blinker_li  : 50|1@1+ (1.000000,0.000000) [0.000000|1.000000] "" Vector__XXX
 SG_ BH_Blinker_re  : 51|1@1+ (1.000000,0.000000) [0.000000|1.000000] "" Vector__XXX
 SG_ BCM1_OBD_FStatus_ATemp  : 52|4@1+ (1.000000,0.000000) [0.000000|15.000000] "" Vector__XXX
 SG_ BCM1_Aussen_Temp_ungef  : 56|8@1+ (0.500000,-50.000000) [-50.000000|76.000000] "Unit_DegreCelsi" Vector__XXX

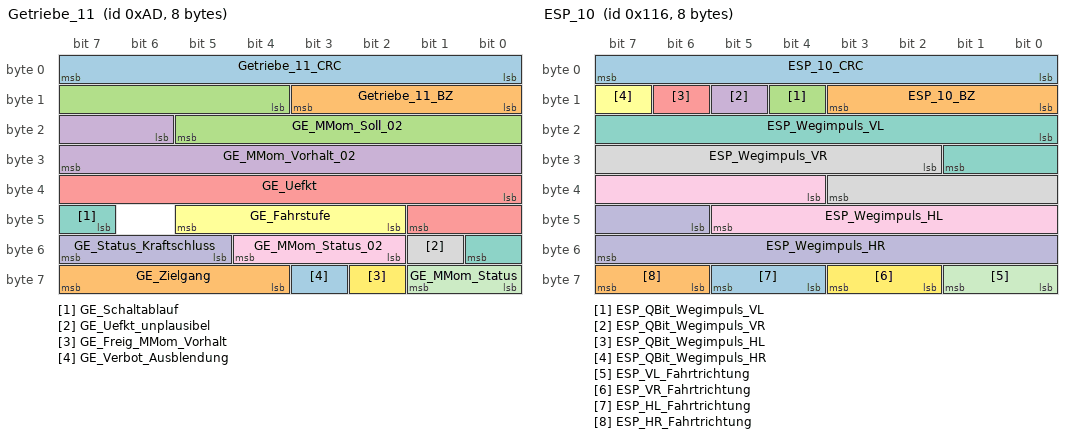
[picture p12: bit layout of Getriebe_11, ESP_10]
BO_ 173 Getriebe_11: 8 Motor_BEV
 SG_ Getriebe_11_CRC  : 0|8@1+ (1.000000,0.000000) [0.000000|255.000000] "" ICAS1_Gateway
 SG_ Getriebe_11_BZ  : 8|4@1+ (1.000000,0.000000) [0.000000|15.000000] "" ICAS1_Gateway
 SG_ GE_MMom_Soll_02  : 12|10@1+ (1.000000,-509.000000) [-509.000000|509.000000] "" ICAS1_Gateway
 SG_ GE_MMom_Vorhalt_02  : 22|10@1+ (1.000000,-509.000000) [-509.000000|509.000000] "" ICAS1_Gateway
 SG_ GE_Uefkt  : 32|10@1+ (0.100000,0.000000) [0.000000|102.200000] "" ICAS1_Gateway
 SG_ GE_Fahrstufe  : 42|4@1+ (1.000000,0.000000) [0.000000|15.000000] "" ICAS1_Gateway
 SG_ GE_Schaltablauf  : 47|2@1+ (1.000000,0.000000) [0.000000|3.000000] "" ICAS1_Gateway
 SG_ GE_Uefkt_unplausibel  : 49|1@1+ (1.000000,0.000000) [0.000000|1.000000] "" ICAS1_Gateway
 SG_ GE_MMom_Status_02  : 50|3@1+ (1.000000,0.000000) [0.000000|7.000000] "" ICAS1_Gateway
 SG_ GE_Status_Kraftschluss  : 53|3@1+ (1.000000,0.000000) [0.000000|7.000000] "" ICAS1_Gateway
 SG_ GE_MMom_Status  : 56|2@1+ (1.000000,0.000000) [0.000000|3.000000] "" ICAS1_Gateway
 SG_ GE_Freig_MMom_Vorhalt  : 58|1@1+ (1.000000,0.000000) [0.000000|1.000000] "" ICAS1_Gateway
 SG_ GE_Verbot_Ausblendung  : 59|1@1+ (1.000000,0.000000) [0.000000|1.000000] "" ICAS1_Gateway
 SG_ GE_Zielgang  : 60|4@1+ (1.000000,0.000000) [0.000000|15.000000] "" ICAS1_Gateway

BU_:  Airbag BAP_Tester ICAS1_Gateway ICAS1_KommunikationsServer LE1 LE2 Motor_BEV Schaltbetaetigung

BO_ 252 ESC_51: 48 ICAS1_Gateway
 SG_ ESC_51_CRC  : 0|8@1+ (1.000000,0.000000) [0.000000|255.000000] "" Motor_BEV
 SG_ ESC_51_BZ  : 8|4@1+ (1.000000,0.000000) [0.000000|15.000000] "" Motor_BEV
 SG_ ESC_aktBr_Modus  : 12|2@1+ (1.000000,0.000000) [0.000000|3.000000] "" Vector__XXX
 SG_ ESC_Blending_Solldruck  : 14|10@1+ (0.250000,0.000000) [0.000000|250.000000] "Unit_Bar" Vector__XXX
 SG_ ESC_aktBr_Volumenstrom  : 24|16@1+ (0.007812,-252.000000) [-252.000000|252.000000] "Unit_MilliLiterPerSec" Vector__XXX
 SG_ ESC_EBKV_Kraftblending_Modus  : 40|2@1+ (1.000000,0.000000) [0.000000|3.000000] "" Vector__XXX
 SG_ ESC_Bremsdruck_Modell  : 42|10@1+ (0.250000,0.000000) [0.000000|250.000000] "Unit_Bar" Motor_BEV
 SG_ ESC_Bremsdruck_02  : 52|10@1+ (0.300000,-30.000000) [-30.000000|276.600000] "Unit_Bar" Vector__XXX
 SG_ ESC_QBit_Bremsdruck_02  : 62|1@1+ (1.000000,0.000000) [0.000000|1.000000] "" Vector__XXX
 SG_ ESP_HL_Radgeschw_02  : 64|16@1+ (0.007500,0.000000) [0.000000|491.490000] "Unit_KiloMeterPerHour" Airbag LE1 LE2 Motor_BEV
 SG_ ESP_HR_Radgeschw_02  : 80|16@1+ (0.007500,0.000000) [0.000000|491.490000] "Unit_KiloMeterPerHour" Airbag LE1 LE2 Motor_BEV
 SG_ ESP_VL_Radgeschw_02  : 96|16@1+ (0.007500,0.000000) [0.000000|491.490000] "Unit_KiloMeterPerHour" Airbag LE1 LE2 Motor_BEV
 SG_ ESP_VR_Radgeschw_02  : 112|16@1+ (0.007500,0.000000) [0.000000|491.490000] "Unit_KiloMeterPerHour" Airbag LE1 LE2 Motor_BEV
 SG_ ESP_FZR_uebersteuern  : 128|8@1+ (0.004000,0.000000) [0.000000|1.000000] "" Vector__XXX
 SG_ ESP_FZR_untersteuern  : 136|8@1+ (0.004000,0.000000) [0.000000|1.000000] "" Vector__XXX
 SG_ ESC_Anf_Mindestreku  : 144|1@1+ (1.000000,0.000000) [0.000000|1.000000] "" Motor_BEV
 SG_ ESC_GMV_aktiv  : 145|3@1+ (1.000000,0.000000) [0.000000|7.000000] "" Vector__XXX
 SG_ ESC_GMV_nicht_verfuegbar  : 148|1@1+ (1.000000,0.000000) [0.000000|1.000000] "" Vector__XXX
 SG_ ESC_Status_vRef_Stuetzeingriff  : 149|1@1+ (1.000000,0.000000) [0.000000|1.000000] "" Motor_BEV
 SG_ FDR_Allradverteilung_aktiv  : 150|1@1+ (1.000000,0.000000) [0.000000|1.000000] "" Vector__XXX
 SG_ FDR_Anf_Allradbetrieb  : 151|1@1+ (1.000000,0.000000) [0.000000|1.000000] "" Vector__XXX
 SG_ ESP_HL_Bremsmoment  : 152|8@1+ (20.000000,0.000000) [0.000000|5060.000000] "Unit_NewtoMeter" Motor_BEV
 SG_ ESP_HR_Bremsmoment  : 160|8@1+ (20.000000,0.000000) [0.000000|5060.000000] "Unit_NewtoMeter" Motor_BEV
 SG_ ESP_VR_Bremsmoment  : 168|8@1+ (40.000000,0.000000) [0.000000|10120.000000] "Unit_NewtoMeter" Motor_BEV
 SG_ ESP_VL_Bremsmoment  : 176|8@1+ (40.000000,0.000000) [0.000000|10120.000000] "Unit_NewtoMeter" Motor_BEV
 SG_ ESP_FDR_uebersteuern  : 184|8@1+ (0.004000,0.000000) [0.000000|1.000000] "" Motor_BEV
 SG_ ESP_FDR_untersteuern  : 192|8@1+ (0.004000,0.000000) [0.000000|1.000000] "" Motor_BEV
 SG_ TSMomBegrenzung  : 268|12@1+ (3.000000,-12279.000000) [-12279.000000|0.000000] "" Motor_BEV
 SG_ ESC_Allrad_Anteil_max_sek  : 280|9@1+ (0.200000,0.000000) [0.000000|100.000000] "Unit_PerCent" Motor_BEV
 SG_ ESC_Allrad_Anteil_min_sek  : 289|9@1+ (0.200000,0.000000) [0.000000|100.000000] "Unit_PerCent" Motor_BEV
 SG_ ESC_Status_Eingriff  : 298|2@1+ (1.000000,0.000000) [0.000000|3.000000] "" Motor_BEV
 SG_ ESC_Status_Eingriff_sek  : 300|2@1+ (1.000000,0.000000) [0.000000|3.000000] "" Motor_BEV
 SG_ ESC_MomRad_Eingriff  : 302|13@1+ (3.000000,-12279.000000) [-12279.000000|12279.000000] "Unit_None" Motor_BEV
 SG_ ESC_MomRad_Eingriff_sek  : 315|13@1+ (3.000000,-12279.000000) [-12279.000000|12279.000000] "Unit_None" Motor_BEV
 SG_ ESC_Achsdrehzahl_Max  : 328|14@1+ (0.400000,-800.000000) [-800.000000|5752.400000] "Unit_MinutInver" Motor_BEV
 SG_ ESC_Achsdrehzahl_Min  : 342|14@1+ (0.400000,-800.000000) [-800.000000|5752.400000] "Unit_MinutInver" Motor_BEV
 SG_ ESC_Achsdrehzahl_Max_sek  : 356|14@1+ (0.400000,-800.000000) [-800.000000|5752.400000] "Unit_MinutInver" Motor_BEV
 SG_ ESC_Achsdrehzahl_Min_sek  : 370|14@1+ (0.400000,-800.000000) [-800.000000|5752.400000] "Unit_MinutInver" Motor_BEV

BO_ 2463978647 ESC_52: 16 ICAS1_Gateway
 SG_ ESP_ACC_LDE  : 12|1@1+ (1.000000,0.000000) [0.000000|1.000000] "" Vector__XXX
 SG_ ESP_Allrad_Antrieb  : 13|1@1+ (1.000000,0.000000) [0.000000|1.000000] "" Vector__XXX
 SG_ ESP_Codierung_ADS  : 14|2@1+ (1.000000,0.000000) [0.000000|3.000000] "" Vector__XXX
 SG_ ESP_RTA_HL  : 16|8@1+ (0.048828,-6.201170) [-6.201170|6.152346] "Unit_PerCent" Motor_BEV
 SG_ ESP_RTA_HR  : 24|8@1+ (0.048828,-6.201170) [-6.201170|6.152346] "Unit_PerCent" Motor_BEV
 SG_ ESP_RTA_VR  : 32|8@1+ (0.048828,-6.201170) [-6.201170|6.152346] "Unit_PerCent" Motor_BEV
 SG_ OBD_Fehler_Radsensor_HL  : 40|4@1+ (1.000000,0.000000) [0.000000|15.000000] "" Motor_BEV
 SG_ OBD_Fehler_Radsensor_HR  : 44|4@1+ (1.000000,0.000000) [0.000000|15.000000] "" Motor_BEV
 SG_ OBD_Fehler_Radsensor_VL  : 48|4@1+ (1.000000,0.000000) [0.000000|15.000000] "" Motor_BEV
 SG_ OBD_Fehler_Radsensor_VR  : 52|4@1+ (1.000000,0.000000) [0.000000|15.000000] "" Motor_BEV
 SG_ ESP_Qualifizierung_Antriebsart  : 56|1@1+ (1.000000,0.000000) [0.000000|1.000000] "" Vector__XXX
 SG_ ESP_Offroad_Modus  : 57|1@1+ (1.000000,0.000000) [0.000000|1.000000] "" Vector__XXX
 SG_ ESP_MKB_ausloesbar  : 58|1@1+ (1.000000,0.000000) [0.000000|1.000000] "" Vector__XXX
 SG_ ESP_Stat_FallBack_eBKV  : 59|1@1+ (1.000000,0.000000) [0.000000|1.000000] "" Vector__XXX
 SG_ ESP_CM_Variante  : 60|1@1+ (1.000000,0.000000) [0.000000|1.000000] "" Vector__XXX
 SG_ ESP_OBD_Status  : 61|1@1+ (1.000000,0.000000) [0.000000|1.000000] "" Motor_BEV
 SG_ ESP_Rollenmodus_Deaktivieren  : 62|1@1+ (1.000000,0.000000) [0.000000|1.000000] "" Motor_BEV
 SG_ ESP_nachtr_Stopp_Anf  : 63|1@1+ (1.000000,0.000000) [0.000000|1.000000] "" Vector__XXX

BO_ 2527679683 ESC_ASM_01: 8 ICAS1_Gateway
 SG_ ESC_ASM_Ereignis  : 0|8@1+ (1.000000,0.000000) [1.000000|254.000000] "Unit_None" Airbag
 SG_ ESC_ASM_Zeitstempel  : 8|8@1+ (0.080000,0.000000) [0.000000|20.320000] "Unit_Secon" Airbag
 SG_ ESC_ASM_Data_1  : 16|8@1+ (1.000000,0.000000) [0.000000|255.000000] "" Airbag
 SG_ ESC_ASM_Data_2  : 24|8@1+ (1.000000,0.000000) [0.000000|255.000000] "" Airbag
 SG_ ESC_ASM_Data_3  : 32|8@1+ (1.000000,0.000000) [0.000000|255.000000] "" Airbag
 SG_ ESC_ASM_Data_4  : 40|8@1+ (1.000000,0.000000) [0.000000|255.000000] "" Airbag
 SG_ ESC_ASM_Data_5  : 48|8@1+ (1.000000,0.000000) [0.000000|255.000000] "" Airbag
 SG_ ESC_ASM_Data_6  : 56|8@1+ (1.000000,0.000000) [0.000000|255.000000] "" Airbag

BO_ 278 ESP_10: 8 ICAS1_Gateway
 SG_ ESP_10_CRC  : 0|8@1+ (1.000000,0.000000) [0.000000|255.000000] "" Vector__XXX
 SG_ ESP_10_BZ  : 8|4@1+ (1.000000,0.000000) [0.000000|15.000000] "" Vector__XXX
 SG_ ESP_QBit_Wegimpuls_VL  : 12|1@1+ (1.000000,0.000000) [0.000000|1.000000] "" Motor_BEV
 SG_ ESP_QBit_Wegimpuls_VR  : 13|1@1+ (1.000000,0.000000) [0.000000|1.000000] "" Motor_BEV
 SG_ ESP_QBit_Wegimpuls_HL  : 14|1@1+ (1.000000,0.000000) [0.000000|1.000000] "" Motor_BEV
 SG_ ESP_QBit_Wegimpuls_HR  : 15|1@1+ (1.000000,0.000000) [0.000000|1.000000] "" Motor_BEV
 SG_ ESP_Wegimpuls_VL  : 16|10@1+ (1.000000,0.000000) [0.000000|1000.000000] "" Motor_BEV
 SG_ ESP_Wegimpuls_VR  : 26|10@1+ (1.000000,0.000000) [0.000000|1000.000000] "" Motor_BEV
 SG_ ESP_Wegimpuls_HL  : 36|10@1+ (1.000000,0.000000) [0.000000|1000.000000] "" Motor_BEV
 SG_ ESP_Wegimpuls_HR  : 46|10@1+ (1.000000,0.000000) [0.000000|1000.000000] "" Motor_BEV
 SG_ ESP_VL_Fahrtrichtung  : 56|2@1+ (1.000000,0.000000) [0.000000|3.000000] "" Motor_BEV
 SG_ ESP_VR_Fahrtrichtung  : 58|2@1+ (1.000000,0.000000) [0.000000|3.000000] "" Motor_BEV
 SG_ ESP_HL_Fahrtrichtung  : 60|2@1+ (1.000000,0.000000) [0.000000|3.000000] "" Motor_BEV
 SG_ ESP_HR_Fahrtrichtung  : 62|2@1+ (1.000000,0.000000) [0.000000|3.000000] "" Motor_BEV

BO_ 1629 ESP_20: 8 ICAS1_Gateway
 SG_ ESP_20_CRC  : 0|8@1+ (1.000000,0.000000) [0.000000|255.000000] "" Vector__XXX
 SG_ ESP_20_BZ  : 8|4@1+ (1.000000,0.000000) [0.000000|15.000000] "" Vector__XXX
 SG_ BR_Systemart  : 12|2@1+ (1.000000,0.000000) [0.000000|3.000000] "" Vector__XXX
 SG_ ESP_SpannungsAnf_02  : 14|2@1+ (1.000000,0.000000) [0.000000|3.000000] "" Vector__XXX
 SG_ ESP_Zaehnezahl  : 16|8@1+ (1.000000,0.000000) [0.000000|255.000000] "" Vector__XXX
 SG_ ESP_Charisma_FahrPr  : 24|4@1+ (1.000000,0.000000) [0.000000|15.000000] "" Vector__XXX
 SG_ ESP_Charisma_Status  : 28|2@1+ (1.000000,0.000000) [0.000000|3.000000] "" Vector__XXX
 SG_ ESP_Wiederstart_Anz_01  : 30|1@1+ (1.000000,0.000000) [0.000000|1.000000] "" Vector__XXX
 SG_ ESP_Wiederstart_Anz_02  : 31|1@1+ (1.000000,0.000000) [0.000000|1.000000] "" Vector__XXX
 SG_ ESP_Wiederstart_Anz_03  : 32|1@1+ (1.000000,0.000000) [0.000000|1.000000] "" Vector__XXX
 SG_ ESP_Wiederstart_Anz_04  : 33|1@1+ (1.000000,0.000000) [0.000000|1.000000] "" Vector__XXX
 SG_ ESP_Stoppverbot_Anz_01  : 34|1@1+ (1.000000,0.000000) [0.000000|1.000000] "" Vector__XXX
 SG_ ESP_Stoppverbot_Anz_02  : 35|1@1+ (1.000000,0.000000) [0.000000|1.000000] "" Vector__XXX
 SG_ ESP_Stoppverbot_Anz_03  : 36|1@1+ (1.000000,0.000000) [0.000000|1.000000] "" Vector__XXX
 SG_ ESP_Stoppverbot_Anz_04  : 37|1@1+ (1.000000,0.000000) [0.000000|1.000000] "" Vector__XXX
 SG_ ESP_Stoppverbot_Anz_05  : 38|1@1+ (1.000000,0.000000) [0.000000|1.000000] "" Vector__XXX
 SG_ ESP_Stoppverbot_Anz_06  : 39|1@1+ (1.000000,0.000000) [0.000000|1.000000] "" Vector__XXX
 SG_ ESP_Stoppverbot_Anz_07  : 40|1@1+ (1.000000,0.000000) [0.000000|1.000000] "" Vector__XXX
 SG_ ESP_Stoppverbot_Anz_Std  : 41|1@1+ (1.000000,0.000000) [0.000000|1.000000] "" Vector__XXX
 SG_ ESP_Dachrelingsensor  : 42|2@1+ (1.000000,0.000000) [0.000000|3.000000] "" Vector__XXX
 SG_ ESP_Stoppverbot_Anz_08  : 44|1@1+ (1.000000,0.000000) [0.000000|1.000000] "" Vector__XXX
 SG_ HDC_Charisma_FahrPr  : 45|4@1+ (1.000000,0.000000) [0.000000|15.000000] "" Vector__XXX
 SG_ HDC_Charisma_Status  : 49|2@1+ (1.000000,0.000000) [0.000000|3.000000] "" Vector__XXX
 SG_ BR_QBit_Reifenumfang  : 51|1@1+ (1.000000,0.000000) [0.000000|1.000000] "" LE1 LE2
 SG_ BR_Reifenumfang  : 52|12@1+ (1.000000,0.000000) [0.000000|4095.000000] "Unit_MilliMeter" LE1 LE2

BO_ 253 ESP_21: 8 ICAS1_Gateway
 SG_ ESP_21_CRC  : 0|8@1+ (1.000000,0.000000) [0.000000|255.000000] "" Airbag LE1 LE2 Motor_BEV
 SG_ ESP_21_BZ  : 8|4@1+ (1.000000,0.000000) [0.000000|15.000000] "" Airbag LE1 LE2 Motor_BEV
 SG_ BR_Eingriffsmoment  : 12|10@1+ (1.000000,-509.000000) [-509.000000|509.000000] "" Vector__XXX
 SG_ ESP_PLA_Bremseingriff  : 22|1@1+ (1.000000,0.000000) [0.000000|1.000000] "" Vector__XXX
 SG_ ESP_Diagnose  : 23|1@1+ (1.000000,0.000000) [0.000000|1.000000] "" Vector__XXX
 SG_ ESC_Reku_Freigabe  : 24|1@1+ (1.000000,0.000000) [0.000000|1.000000] "" Motor_BEV
 SG_ ESC_v_Signal_Qualifier_High_Low  : 25|3@1+ (1.000000,0.000000) [0.000000|7.000000] "" Airbag
 SG_ ESP_Vorsteuerung  : 28|1@1+ (1.000000,0.000000) [0.000000|1.000000] "" Motor_BEV
 SG_ ESP_AWV3_Brems_aktiv  : 29|1@1+ (1.000000,0.000000) [0.000000|1.000000] "" Vector__XXX
 SG_ OBD_Schlechtweg  : 30|1@1+ (1.000000,0.000000) [0.000000|1.000000] "" Vector__XXX
 SG_ OBD_QBit_Schlechtweg  : 31|1@1+ (1.000000,0.000000) [0.000000|1.000000] "" Vector__XXX
 SG_ ESP_v_Signal  : 32|16@1+ (0.010000,0.000000) [0.000000|655.320000] "Unit_KiloMeterPerHour" Airbag LE1 LE2 Motor_BEV
 SG_ ASR_Tastung_passiv  : 48|1@1+ (1.000000,0.000000) [0.000000|1.000000] "" Airbag Motor_BEV
 SG_ ESP_Tastung_passiv  : 49|1@1+ (1.000000,0.000000) [0.000000|1.000000] "" Airbag Motor_BEV
 SG_ ESP_Systemstatus  : 50|1@1+ (1.000000,0.000000) [0.000000|1.000000] "" Motor_BEV
 SG_ ASR_Schalteingriff  : 51|2@1+ (1.000000,0.000000) [0.000000|3.000000] "" Vector__XXX
 SG_ ESP_Haltebestaetigung  : 53|1@1+ (1.000000,0.000000) [0.000000|1.000000] "" Vector__XXX
 SG_ ESP_MKB_Abbruch_Geschw  : 54|1@1+ (1.000000,0.000000) [0.000000|1.000000] "" Vector__XXX
 SG_ ESP_QBit_v_Signal  : 55|1@1+ (1.000000,0.000000) [0.000000|1.000000] "" LE1 LE2 Motor_BEV
 SG_ ABS_Bremsung  : 56|1@1+ (1.000000,0.000000) [0.000000|1.000000] "" Airbag Motor_BEV
 SG_ ASR_Anf  : 57|1@1+ (1.000000,0.000000) [0.000000|1.000000] "" Vector__XXX
 SG_ MSR_Anf  : 58|1@1+ (1.000000,0.000000) [0.000000|1.000000] "" Vector__XXX
 SG_ EBV_Eingriff  : 59|1@1+ (1.000000,0.000000) [0.000000|1.000000] "" Vector__XXX
 SG_ EDS_Eingriff  : 60|1@1+ (1.000000,0.000000) [0.000000|1.000000] "" Motor_BEV
 SG_ ESP_Eingriff  : 61|1@1+ (1.000000,0.000000) [0.000000|1.000000] "" Airbag Motor_BEV
 SG_ ESP_ASP  : 62|1@1+ (1.000000,0.000000) [0.000000|1.000000] "" Vector__XXX
 SG_ ESP_Anhaltevorgang_ACC_aktiv  : 63|1@1+ (1.000000,0.000000) [0.000000|1.000000] "" Vector__XXX

BO_ 795 ESP_24: 8 ICAS1_Gateway
 SG_ ESP_24_CRC  : 0|8@1+ (1.000000,0.000000) [0.000000|255.000000] "" Vector__XXX
 SG_ ESP_24_BZ  : 8|4@1+ (1.000000,0.000000) [0.000000|15.000000] "" Vector__XXX
 SG_ ESP_Lampe  : 12|1@1+ (1.000000,0.000000) [0.000000|1.000000] "" Motor_BEV
 SG_ ABS_Lampe  : 13|1@1+ (1.000000,0.000000) [0.000000|1.000000] "" Vector__XXX
 SG_ BK_Lampe_02  : 14|2@1+ (1.000000,0.000000) [0.000000|3.000000] "" Vector__XXX
 SG_ TC_Lampe  : 16|1@1+ (1.000000,0.000000) [0.000000|1.000000] "" Vector__XXX
 SG_ ESP_m_Raddrehz  : 17|15@1+ (0.002000,0.000000) [0.000000|65.278000] "Unit_Hertz" Vector__XXX
 SG_ ESP_Textanzeigen_03  : 32|5@1+ (1.000000,0.000000) [0.000000|31.000000] "" Vector__XXX
 SG_ ESP_Meldungen  : 37|3@1+ (1.000000,0.000000) [0.000000|7.000000] "" Vector__XXX
 SG_ ESP_Wegimp_VA  : 40|11@1+ (1.000000,0.000000) [0.000000|2047.000000] "" Vector__XXX
 SG_ ESP_Fehlerstatus_Wegimp  : 51|1@1+ (1.000000,0.000000) [0.000000|1.000000] "" Vector__XXX
 SG_ ESP_Wegimp_Ueberlauf  : 52|1@1+ (1.000000,0.000000) [0.000000|1.000000] "" Vector__XXX
 SG_ ESP_QBit_Wegimp_VA  : 53|1@1+ (1.000000,0.000000) [0.000000|1.000000] "" Vector__XXX
 SG_ ESP_HDC_FktLampe  : 54|1@1+ (1.000000,0.000000) [0.000000|1.000000] "" Vector__XXX
 SG_ ESP_Off_Lampe  : 55|1@1+ (1.000000,0.000000) [0.000000|1.000000] "" Airbag
 SG_ ESP_HDC_Regelgeschw  : 56|7@1+ (0.320000,0.000000) [0.320000|39.680000] "Unit_KiloMeterPerHour" Vector__XXX
 SG_ ESP_BKV_Warnung  : 63|1@1+ (1.000000,0.000000) [0.000000|1.000000] "" Vector__XXX

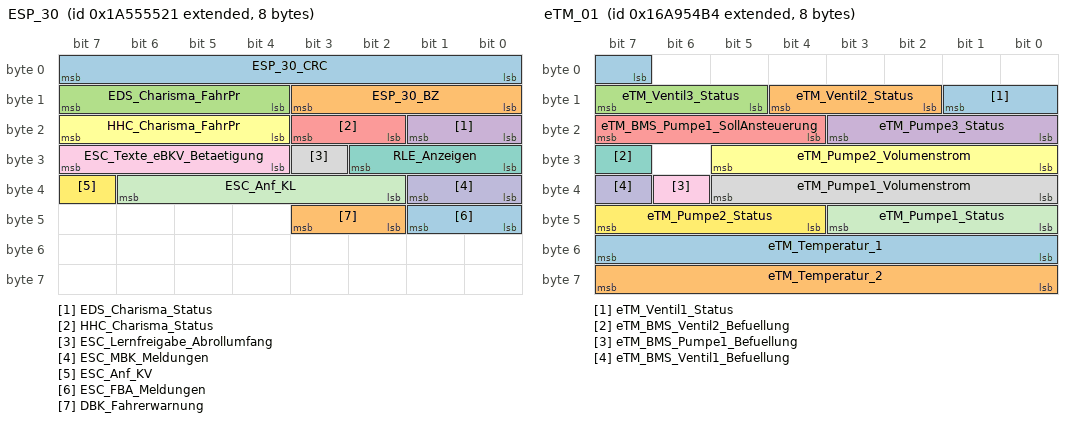
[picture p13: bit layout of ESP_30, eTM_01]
BO_ 2589283617 ESP_30: 8 ICAS1_Gateway
 SG_ ESP_30_CRC  : 0|8@1+ (1.000000,0.000000) [0.000000|255.000000] "" Vector__XXX
 SG_ ESP_30_BZ  : 8|4@1+ (1.000000,0.000000) [0.000000|15.000000] "" Vector__XXX
 SG_ EDS_Charisma_FahrPr  : 12|4@1+ (1.000000,0.000000) [0.000000|15.000000] "" Vector__XXX
 SG_ EDS_Charisma_Status  : 16|2@1+ (1.000000,0.000000) [0.000000|3.000000] "" Vector__XXX
 SG_ HHC_Charisma_Status  : 18|2@1+ (1.000000,0.000000) [0.000000|3.000000] "" Vector__XXX
 SG_ HHC_Charisma_FahrPr  : 20|4@1+ (1.000000,0.000000) [0.000000|15.000000] "" Vector__XXX
 SG_ RLE_Anzeigen  : 24|3@1+ (1.000000,0.000000) [0.000000|7.000000] "" Vector__XXX
 SG_ ESC_Lernfreigabe_Abrollumfang  : 27|1@1+ (1.000000,0.000000) [0.000000|1.000000] "" Vector__XXX
 SG_ ESC_Texte_eBKV_Betaetigung  : 28|4@1+ (1.000000,0.000000) [0.000000|15.000000] "" Vector__XXX
 SG_ ESC_MBK_Meldungen  : 32|2@1+ (1.000000,0.000000) [0.000000|3.000000] "" Vector__XXX
 SG_ ESC_Anf_KL  : 34|5@1+ (3.225806,0.000000) [0.000000|100.000000] "Unit_PerCent" Motor_BEV
 SG_ ESC_Anf_KV  : 39|1@1+ (1.000000,0.000000) [0.000000|1.000000] "" Motor_BEV
 SG_ ESC_FBA_Meldungen  : 40|2@1+ (1.000000,0.000000) [0.000000|3.000000] "" Vector__XXX
 SG_ DBK_Fahrerwarnung  : 42|2@1+ (1.000000,0.000000) [0.000000|3.000000] "" Vector__XXX

BO_ 2527679668 eTM_01: 8 Motor_BEV
 SG_ eTM_Ventil1_Status  : 7|3@1+ (1.000000,0.000000) [0.000000|7.000000] "" ICAS1_Gateway
 SG_ eTM_Ventil2_Status  : 10|3@1+ (1.000000,0.000000) [0.000000|7.000000] "" ICAS1_Gateway
 SG_ eTM_Ventil3_Status  : 13|3@1+ (1.000000,0.000000) [0.000000|7.000000] "" ICAS1_Gateway
 SG_ eTM_Pumpe3_Status  : 16|4@1+ (10.000000,0.000000) [0.000000|130.000000] "Unit_PerCent" ICAS1_Gateway
 SG_ eTM_BMS_Pumpe1_SollAnsteuerung  : 20|4@1+ (10.000000,0.000000) [0.000000|130.000000] "Unit_PerCent" ICAS1_Gateway
 SG_ eTM_Pumpe2_Volumenstrom  : 24|6@1+ (0.500000,0.000000) [0.000000|30.500000] "Unit_LiterPerMinut" ICAS1_Gateway LE1 LE2
 SG_ eTM_BMS_Ventil2_Befuellung  : 31|1@1+ (1.000000,0.000000) [0.000000|1.000000] "" ICAS1_Gateway
 SG_ eTM_Pumpe1_Volumenstrom  : 32|6@1+ (0.500000,0.000000) [0.000000|30.500000] "Unit_LiterPerMinut" ICAS1_Gateway LE1 LE2
 SG_ eTM_BMS_Pumpe1_Befuellung  : 38|1@1+ (1.000000,0.000000) [0.000000|1.000000] "" ICAS1_Gateway
 SG_ eTM_BMS_Ventil1_Befuellung  : 39|1@1+ (1.000000,0.000000) [0.000000|1.000000] "" ICAS1_Gateway
 SG_ eTM_Pumpe1_Status  : 40|4@1+ (10.000000,0.000000) [0.000000|130.000000] "Unit_PerCent" ICAS1_Gateway LE1 LE2
 SG_ eTM_Pumpe2_Status  : 44|4@1+ (10.000000,0.000000) [0.000000|130.000000] "Unit_PerCent" ICAS1_Gateway LE1 LE2
 SG_ eTM_Temperatur_1  : 48|8@1+ (0.750000,-40.000000) [-40.000000|149.750000] "Unit_DegreCelsi" ICAS1_Gateway LE1 LE2
 SG_ eTM_Temperatur_2  : 56|8@1+ (0.750000,-40.000000) [-40.000000|149.750000] "Unit_DegreCelsi" ICAS1_Gateway LE1 LE2

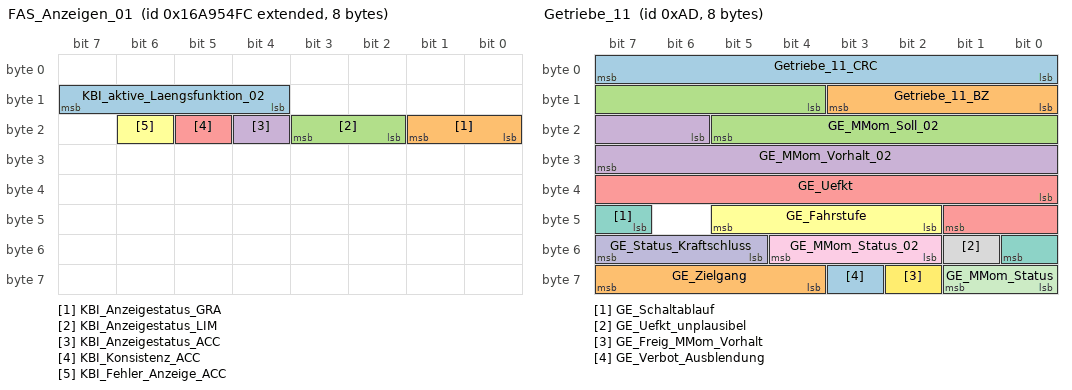
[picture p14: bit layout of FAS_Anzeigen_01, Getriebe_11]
BO_ 2527679740 FAS_Anzeigen_01: 8 ICAS1_KommunikationsServer
 SG_ KBI_aktive_Laengsfunktion_02  : 12|4@1+ (1.000000,0.000000) [0.000000|15.000000] "" Motor_BEV
 SG_ KBI_Anzeigestatus_GRA  : 16|2@1+ (1.000000,0.000000) [0.000000|3.000000] "" Motor_BEV
 SG_ KBI_Anzeigestatus_LIM  : 18|2@1+ (1.000000,0.000000) [0.000000|3.000000] "" Motor_BEV
 SG_ KBI_Anzeigestatus_ACC  : 20|1@1+ (1.000000,0.000000) [0.000000|1.000000] "" Vector__XXX
 SG_ KBI_Konsistenz_ACC  : 21|1@1+ (1.000000,0.000000) [0.000000|1.000000] "" Vector__XXX
 SG_ KBI_Fehler_Anzeige_ACC  : 22|1@1+ (1.000000,0.000000) [0.000000|1.000000] "" Vector__XXX

BO_ 2589283684 FoD_01: 8 ICAS1_Gateway
 SG_ GRA_FoD_Status  : 58|2@1+ (1.000000,0.000000) [0.000000|3.000000] "" Vector__XXX
 SG_ FoD_Transmission_Info  : 60|2@1+ (1.000000,0.000000) [0.000000|3.000000] "" Motor_BEV

BO_ 2549875574 FoD_MO_01_Req: 8 ICAS1_Gateway
 SG_ FoD_MO_01_Req_Data  : 0|64@1+ (1.000000,0.000000) [0.000000|18446744073709551616.000000] "" Motor_BEV

BO_ 2550006646 FoD_MO_01_Resp: 8 Motor_BEV
 SG_ FoD_MO_01_Resp_Data  : 0|64@1+ (1.000000,0.000000) [0.000000|18446744073709551616.000000] "" ICAS1_Gateway

BO_ 987 Gateway_72: 8 ICAS1_Gateway
 SG_ BCM_01_alt  : 0|1@1+ (1.000000,0.000000) [0.000000|1.000000] "" Airbag
 SG_ SMLS_01_alt  : 1|1@1+ (1.000000,0.000000) [0.000000|1.000000] "" Vector__XXX
 SG_ ZV_02_alt  : 2|1@1+ (1.000000,0.000000) [0.000000|1.000000] "" Vector__XXX
 SG_ Wischer_01_alt  : 3|1@1+ (1.000000,0.000000) [0.000000|1.000000] "" Vector__XXX
 SG_ Anhaenger_01_alt  : 4|1@1+ (1.000000,0.000000) [0.000000|1.000000] "" Airbag
 SG_ Klima_Sensor_02_alt  : 5|1@1+ (1.000000,0.000000) [0.000000|1.000000] "" Vector__XXX
 SG_ Verdeck_01_alt  : 6|1@1+ (1.000000,0.000000) [0.000000|1.000000] "" Vector__XXX
 SG_ Klima_11_alt  : 7|1@1+ (1.000000,0.000000) [0.000000|1.000000] "" Vector__XXX
 SG_ WFS_01_alt  : 8|1@1+ (1.000000,0.000000) [0.000000|1.000000] "" Vector__XXX
 SG_ Licht_Anf_01_alt  : 9|1@1+ (1.000000,0.000000) [0.000000|1.000000] "" Vector__XXX
 SG_ ZV_verriegelt_extern_soll  : 10|1@1+ (1.000000,0.000000) [0.000000|1.000000] "" Vector__XXX
 SG_ BH_Lichthupe  : 11|1@1+ (1.000000,0.000000) [0.000000|1.000000] "" Vector__XXX
 SG_ WFS_Klemmenfreigabe  : 12|1@1+ (1.000000,0.000000) [0.000000|1.000000] "" Vector__XXX
 SG_ ZV_Tankklappe_offen  : 13|1@1+ (1.000000,0.000000) [0.000000|1.000000] "" Vector__XXX
 SG_ AAG_Anhaenger_abgesteckt  : 14|1@1+ (1.000000,0.000000) [0.000000|1.000000] "" Vector__XXX
 SG_ BCM1_LDS_Stellung  : 15|3@1+ (1.000000,0.000000) [0.000000|7.000000] "" Vector__XXX
 SG_ VS_Verdeck_Anf  : 18|1@1+ (1.000000,0.000000) [0.000000|1.000000] "" Vector__XXX
 SG_ VS_VD_entriegelt  : 19|1@1+ (1.000000,0.000000) [0.000000|1.000000] "" Vector__XXX
 SG_ ZV_HFS_offen  : 20|1@1+ (1.000000,0.000000) [0.000000|1.000000] "" Vector__XXX
 SG_ ZV_HBFS_offen  : 21|1@1+ (1.000000,0.000000) [0.000000|1.000000] "" Vector__XXX
 SG_ VS_VD_offen_ver  : 22|1@1+ (1.000000,0.000000) [0.000000|1.000000] "" Vector__XXX
 SG_ VS_VD_zu_ver  : 23|1@1+ (1.000000,0.000000) [0.000000|1.000000] "" Vector__XXX
 SG_ ZV_BT_offen  : 24|1@1+ (1.000000,0.000000) [0.000000|1.000000] "" Vector__XXX
 SG_ BCM1_Rueckfahrlicht_Schalter  : 25|1@1+ (1.000000,0.000000) [0.000000|1.000000] "" Airbag Motor_BEV
 SG_ ZV_FT_offen  : 26|1@1+ (1.000000,0.000000) [0.000000|1.000000] "" Vector__XXX
 SG_ Wischer_vorne_aktiv  : 27|1@1+ (1.000000,0.000000) [0.000000|1.000000] "" Vector__XXX
 SG_ AAG_Anhaenger_erkannt  : 28|1@1+ (1.000000,0.000000) [0.000000|1.000000] "" Airbag
 SG_ BCM1_MH_Schalter  : 29|1@1+ (1.000000,0.000000) [0.000000|1.000000] "" Vector__XXX
 SG_ ZV_HD_offen  : 30|1@1+ (1.000000,0.000000) [0.000000|1.000000] "" Vector__XXX
 SG_ Waschen_vorne_aktiv  : 31|1@1+ (1.000000,0.000000) [0.000000|1.000000] "" Vector__XXX
 SG_ KL_Thermomanagement  : 32|2@1+ (1.000000,0.000000) [0.000000|3.000000] "" Vector__XXX
 SG_ WFS_Schluessel_Fahrberecht  : 34|4@1+ (1.000000,0.000000) [0.000000|15.000000] "" Vector__XXX
 SG_ BCM_Rueckfahrlicht_Anf  : 38|1@1+ (1.000000,0.000000) [0.000000|1.000000] "" Vector__XXX
 SG_ WWSs_01_alt  : 39|1@1+ (1.000000,0.000000) [0.000000|1.000000] "" Vector__XXX
 SG_ BCM_Tankklappensteller_Fehler  : 40|1@1+ (1.000000,0.000000) [0.000000|1.000000] "" Vector__XXX
 SG_ AAG_LED_aktiv  : 41|1@1+ (1.000000,0.000000) [0.000000|1.000000] "" Vector__XXX
 SG_ ZV_verriegelt_soll  : 42|2@1+ (1.000000,0.000000) [0.000000|3.000000] "" Vector__XXX
 SG_ ZV_Schluessel_Zugang  : 44|4@1+ (1.000000,0.000000) [0.000000|15.000000] "" Vector__XXX
 SG_ WFS_ID_Geb_autorisiert_in_Kl15  : 48|1@1+ (1.000000,0.000000) [0.000000|1.000000] "" Vector__XXX
 SG_ BH_Fernlicht  : 49|1@1+ (1.000000,0.000000) [0.000000|1.000000] "" Vector__XXX
 SG_ BH_Blinker_li  : 50|1@1+ (1.000000,0.000000) [0.000000|1.000000] "" Vector__XXX
 SG_ BH_Blinker_re  : 51|1@1+ (1.000000,0.000000) [0.000000|1.000000] "" Vector__XXX
 SG_ BCM1_OBD_FStatus_ATemp  : 52|4@1+ (1.000000,0.000000) [0.000000|15.000000] "" Vector__XXX
 SG_ BCM1_Aussen_Temp_ungef  : 56|8@1+ (0.500000,-50.000000) [-50.000000|76.000000] "Unit_DegreCelsi" Vector__XXX

BO_ 173 Getriebe_11: 8 Motor_BEV
 SG_ Getriebe_11_CRC  : 0|8@1+ (1.000000,0.000000) [0.000000|255.000000] "" ICAS1_Gateway
 SG_ Getriebe_11_BZ  : 8|4@1+ (1.000000,0.000000) [0.000000|15.000000] "" ICAS1_Gateway
 SG_ GE_MMom_Soll_02  : 12|10@1+ (1.000000,-509.000000) [-509.000000|509.000000] "" ICAS1_Gateway
 SG_ GE_MMom_Vorhalt_02  : 22|10@1+ (1.000000,-509.000000) [-509.000000|509.000000] "" ICAS1_Gateway
 SG_ GE_Uefkt  : 32|10@1+ (0.100000,0.000000) [0.000000|102.200000] "" ICAS1_Gateway
 SG_ GE_Fahrstufe  : 42|4@1+ (1.000000,0.000000) [0.000000|15.000000] "" ICAS1_Gateway
 SG_ GE_Schaltablauf  : 47|2@1+ (1.000000,0.000000) [0.000000|3.000000] "" ICAS1_Gateway
 SG_ GE_Uefkt_unplausibel  : 49|1@1+ (1.000000,0.000000) [0.000000|1.000000] "" ICAS1_Gateway
 SG_ GE_MMom_Status_02  : 50|3@1+ (1.000000,0.000000) [0.000000|7.000000] "" ICAS1_Gateway
 SG_ GE_Status_Kraftschluss  : 53|3@1+ (1.000000,0.000000) [0.000000|7.000000] "" ICAS1_Gateway
 SG_ GE_MMom_Status  : 56|2@1+ (1.000000,0.000000) [0.000000|3.000000] "" ICAS1_Gateway
 SG_ GE_Freig_MMom_Vorhalt  : 58|1@1+ (1.000000,0.000000) [0.000000|1.000000] "" ICAS1_Gateway
 SG_ GE_Verbot_Ausblendung  : 59|1@1+ (1.000000,0.000000) [0.000000|1.000000] "" ICAS1_Gateway
 SG_ GE_Zielgang  : 60|4@1+ (1.000000,0.000000) [0.000000|15.000000] "" ICAS1_Gateway

BU_:  Airbag BAP_Tester ICAS1_Gateway ICAS1_KommunikationsServer LE1 LE2 Motor_BEV Schaltbetaetigung

BO_ 252 ESC_51: 48 ICAS1_Gateway
 SG_ ESC_51_CRC  : 0|8@1+ (1.000000,0.000000) [0.000000|255.000000] "" Motor_BEV
 SG_ ESC_51_BZ  : 8|4@1+ (1.000000,0.000000) [0.000000|15.000000] "" Motor_BEV
 SG_ ESC_aktBr_Modus  : 12|2@1+ (1.000000,0.000000) [0.000000|3.000000] "" Vector__XXX
 SG_ ESC_Blending_Solldruck  : 14|10@1+ (0.250000,0.000000) [0.000000|250.000000] "Unit_Bar" Vector__XXX
 SG_ ESC_aktBr_Volumenstrom  : 24|16@1+ (0.007812,-252.000000) [-252.000000|252.000000] "Unit_MilliLiterPerSec" Vector__XXX
 SG_ ESC_EBKV_Kraftblending_Modus  : 40|2@1+ (1.000000,0.000000) [0.000000|3.000000] "" Vector__XXX
 SG_ ESC_Bremsdruck_Modell  : 42|10@1+ (0.250000,0.000000) [0.000000|250.000000] "Unit_Bar" Motor_BEV
 SG_ ESC_Bremsdruck_02  : 52|10@1+ (0.300000,-30.000000) [-30.000000|276.600000] "Unit_Bar" Vector__XXX
 SG_ ESC_QBit_Bremsdruck_02  : 62|1@1+ (1.000000,0.000000) [0.000000|1.000000] "" Vector__XXX
 SG_ ESP_HL_Radgeschw_02  : 64|16@1+ (0.007500,0.000000) [0.000000|491.490000] "Unit_KiloMeterPerHour" Airbag LE1 LE2 Motor_BEV
 SG_ ESP_HR_Radgeschw_02  : 80|16@1+ (0.007500,0.000000) [0.000000|491.490000] "Unit_KiloMeterPerHour" Airbag LE1 LE2 Motor_BEV
 SG_ ESP_VL_Radgeschw_02  : 96|16@1+ (0.007500,0.000000) [0.000000|491.490000] "Unit_KiloMeterPerHour" Airbag LE1 LE2 Motor_BEV
 SG_ ESP_VR_Radgeschw_02  : 112|16@1+ (0.007500,0.000000) [0.000000|491.490000] "Unit_KiloMeterPerHour" Airbag LE1 LE2 Motor_BEV
 SG_ ESP_FZR_uebersteuern  : 128|8@1+ (0.004000,0.000000) [0.000000|1.000000] "" Vector__XXX
 SG_ ESP_FZR_untersteuern  : 136|8@1+ (0.004000,0.000000) [0.000000|1.000000] "" Vector__XXX
 SG_ ESC_Anf_Mindestreku  : 144|1@1+ (1.000000,0.000000) [0.000000|1.000000] "" Motor_BEV
 SG_ ESC_GMV_aktiv  : 145|3@1+ (1.000000,0.000000) [0.000000|7.000000] "" Vector__XXX
 SG_ ESC_GMV_nicht_verfuegbar  : 148|1@1+ (1.000000,0.000000) [0.000000|1.000000] "" Vector__XXX
 SG_ ESC_Status_vRef_Stuetzeingriff  : 149|1@1+ (1.000000,0.000000) [0.000000|1.000000] "" Motor_BEV
 SG_ FDR_Allradverteilung_aktiv  : 150|1@1+ (1.000000,0.000000) [0.000000|1.000000] "" Vector__XXX
 SG_ FDR_Anf_Allradbetrieb  : 151|1@1+ (1.000000,0.000000) [0.000000|1.000000] "" Vector__XXX
 SG_ ESP_HL_Bremsmoment  : 152|8@1+ (20.000000,0.000000) [0.000000|5060.000000] "Unit_NewtoMeter" Motor_BEV
 SG_ ESP_HR_Bremsmoment  : 160|8@1+ (20.000000,0.000000) [0.000000|5060.000000] "Unit_NewtoMeter" Motor_BEV
 SG_ ESP_VR_Bremsmoment  : 168|8@1+ (40.000000,0.000000) [0.000000|10120.000000] "Unit_NewtoMeter" Motor_BEV
 SG_ ESP_VL_Bremsmoment  : 176|8@1+ (40.000000,0.000000) [0.000000|10120.000000] "Unit_NewtoMeter" Motor_BEV
 SG_ ESP_FDR_uebersteuern  : 184|8@1+ (0.004000,0.000000) [0.000000|1.000000] "" Motor_BEV
 SG_ ESP_FDR_untersteuern  : 192|8@1+ (0.004000,0.000000) [0.000000|1.000000] "" Motor_BEV
 SG_ TSMomBegrenzung  : 268|12@1+ (3.000000,-12279.000000) [-12279.000000|0.000000] "" Motor_BEV
 SG_ ESC_Allrad_Anteil_max_sek  : 280|9@1+ (0.200000,0.000000) [0.000000|100.000000] "Unit_PerCent" Motor_BEV
 SG_ ESC_Allrad_Anteil_min_sek  : 289|9@1+ (0.200000,0.000000) [0.000000|100.000000] "Unit_PerCent" Motor_BEV
 SG_ ESC_Status_Eingriff  : 298|2@1+ (1.000000,0.000000) [0.000000|3.000000] "" Motor_BEV
 SG_ ESC_Status_Eingriff_sek  : 300|2@1+ (1.000000,0.000000) [0.000000|3.000000] "" Motor_BEV
 SG_ ESC_MomRad_Eingriff  : 302|13@1+ (3.000000,-12279.000000) [-12279.000000|12279.000000] "Unit_None" Motor_BEV
 SG_ ESC_MomRad_Eingriff_sek  : 315|13@1+ (3.000000,-12279.000000) [-12279.000000|12279.000000] "Unit_None" Motor_BEV
 SG_ ESC_Achsdrehzahl_Max  : 328|14@1+ (0.400000,-800.000000) [-800.000000|5752.400000] "Unit_MinutInver" Motor_BEV
 SG_ ESC_Achsdrehzahl_Min  : 342|14@1+ (0.400000,-800.000000) [-800.000000|5752.400000] "Unit_MinutInver" Motor_BEV
 SG_ ESC_Achsdrehzahl_Max_sek  : 356|14@1+ (0.400000,-800.000000) [-800.000000|5752.400000] "Unit_MinutInver" Motor_BEV
 SG_ ESC_Achsdrehzahl_Min_sek  : 370|14@1+ (0.400000,-800.000000) [-800.000000|5752.400000] "Unit_MinutInver" Motor_BEV

BO_ 2463978647 ESC_52: 16 ICAS1_Gateway
 SG_ ESP_ACC_LDE  : 12|1@1+ (1.000000,0.000000) [0.000000|1.000000] "" Vector__XXX
 SG_ ESP_Allrad_Antrieb  : 13|1@1+ (1.000000,0.000000) [0.000000|1.000000] "" Vector__XXX
 SG_ ESP_Codierung_ADS  : 14|2@1+ (1.000000,0.000000) [0.000000|3.000000] "" Vector__XXX
 SG_ ESP_RTA_HL  : 16|8@1+ (0.048828,-6.201170) [-6.201170|6.152346] "Unit_PerCent" Motor_BEV
 SG_ ESP_RTA_HR  : 24|8@1+ (0.048828,-6.201170) [-6.201170|6.152346] "Unit_PerCent" Motor_BEV
 SG_ ESP_RTA_VR  : 32|8@1+ (0.048828,-6.201170) [-6.201170|6.152346] "Unit_PerCent" Motor_BEV
 SG_ OBD_Fehler_Radsensor_HL  : 40|4@1+ (1.000000,0.000000) [0.000000|15.000000] "" Motor_BEV
 SG_ OBD_Fehler_Radsensor_HR  : 44|4@1+ (1.000000,0.000000) [0.000000|15.000000] "" Motor_BEV
 SG_ OBD_Fehler_Radsensor_VL  : 48|4@1+ (1.000000,0.000000) [0.000000|15.000000] "" Motor_BEV
 SG_ OBD_Fehler_Radsensor_VR  : 52|4@1+ (1.000000,0.000000) [0.000000|15.000000] "" Motor_BEV
 SG_ ESP_Qualifizierung_Antriebsart  : 56|1@1+ (1.000000,0.000000) [0.000000|1.000000] "" Vector__XXX
 SG_ ESP_Offroad_Modus  : 57|1@1+ (1.000000,0.000000) [0.000000|1.000000] "" Vector__XXX
 SG_ ESP_MKB_ausloesbar  : 58|1@1+ (1.000000,0.000000) [0.000000|1.000000] "" Vector__XXX
 SG_ ESP_Stat_FallBack_eBKV  : 59|1@1+ (1.000000,0.000000) [0.000000|1.000000] "" Vector__XXX
 SG_ ESP_CM_Variante  : 60|1@1+ (1.000000,0.000000) [0.000000|1.000000] "" Vector__XXX
 SG_ ESP_OBD_Status  : 61|1@1+ (1.000000,0.000000) [0.000000|1.000000] "" Motor_BEV
 SG_ ESP_Rollenmodus_Deaktivieren  : 62|1@1+ (1.000000,0.000000) [0.000000|1.000000] "" Motor_BEV
 SG_ ESP_nachtr_Stopp_Anf  : 63|1@1+ (1.000000,0.000000) [0.000000|1.000000] "" Vector__XXX

BO_ 2527679683 ESC_ASM_01: 8 ICAS1_Gateway
 SG_ ESC_ASM_Ereignis  : 0|8@1+ (1.000000,0.000000) [1.000000|254.000000] "Unit_None" Airbag
 SG_ ESC_ASM_Zeitstempel  : 8|8@1+ (0.080000,0.000000) [0.000000|20.320000] "Unit_Secon" Airbag
 SG_ ESC_ASM_Data_1  : 16|8@1+ (1.000000,0.000000) [0.000000|255.000000] "" Airbag
 SG_ ESC_ASM_Data_2  : 24|8@1+ (1.000000,0.000000) [0.000000|255.000000] "" Airbag
 SG_ ESC_ASM_Data_3  : 32|8@1+ (1.000000,0.000000) [0.000000|255.000000] "" Airbag
 SG_ ESC_ASM_Data_4  : 40|8@1+ (1.000000,0.000000) [0.000000|255.000000] "" Airbag
 SG_ ESC_ASM_Data_5  : 48|8@1+ (1.000000,0.000000) [0.000000|255.000000] "" Airbag
 SG_ ESC_ASM_Data_6  : 56|8@1+ (1.000000,0.000000) [0.000000|255.000000] "" Airbag

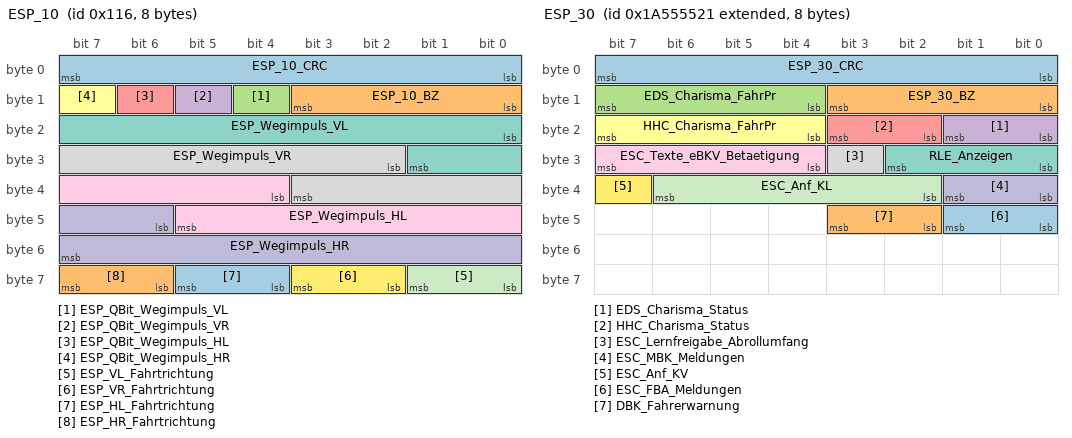
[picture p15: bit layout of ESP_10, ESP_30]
BO_ 278 ESP_10: 8 ICAS1_Gateway
 SG_ ESP_10_CRC  : 0|8@1+ (1.000000,0.000000) [0.000000|255.000000] "" Vector__XXX
 SG_ ESP_10_BZ  : 8|4@1+ (1.000000,0.000000) [0.000000|15.000000] "" Vector__XXX
 SG_ ESP_QBit_Wegimpuls_VL  : 12|1@1+ (1.000000,0.000000) [0.000000|1.000000] "" Motor_BEV
 SG_ ESP_QBit_Wegimpuls_VR  : 13|1@1+ (1.000000,0.000000) [0.000000|1.000000] "" Motor_BEV
 SG_ ESP_QBit_Wegimpuls_HL  : 14|1@1+ (1.000000,0.000000) [0.000000|1.000000] "" Motor_BEV
 SG_ ESP_QBit_Wegimpuls_HR  : 15|1@1+ (1.000000,0.000000) [0.000000|1.000000] "" Motor_BEV
 SG_ ESP_Wegimpuls_VL  : 16|10@1+ (1.000000,0.000000) [0.000000|1000.000000] "" Motor_BEV
 SG_ ESP_Wegimpuls_VR  : 26|10@1+ (1.000000,0.000000) [0.000000|1000.000000] "" Motor_BEV
 SG_ ESP_Wegimpuls_HL  : 36|10@1+ (1.000000,0.000000) [0.000000|1000.000000] "" Motor_BEV
 SG_ ESP_Wegimpuls_HR  : 46|10@1+ (1.000000,0.000000) [0.000000|1000.000000] "" Motor_BEV
 SG_ ESP_VL_Fahrtrichtung  : 56|2@1+ (1.000000,0.000000) [0.000000|3.000000] "" Motor_BEV
 SG_ ESP_VR_Fahrtrichtung  : 58|2@1+ (1.000000,0.000000) [0.000000|3.000000] "" Motor_BEV
 SG_ ESP_HL_Fahrtrichtung  : 60|2@1+ (1.000000,0.000000) [0.000000|3.000000] "" Motor_BEV
 SG_ ESP_HR_Fahrtrichtung  : 62|2@1+ (1.000000,0.000000) [0.000000|3.000000] "" Motor_BEV

BO_ 1629 ESP_20: 8 ICAS1_Gateway
 SG_ ESP_20_CRC  : 0|8@1+ (1.000000,0.000000) [0.000000|255.000000] "" Vector__XXX
 SG_ ESP_20_BZ  : 8|4@1+ (1.000000,0.000000) [0.000000|15.000000] "" Vector__XXX
 SG_ BR_Systemart  : 12|2@1+ (1.000000,0.000000) [0.000000|3.000000] "" Vector__XXX
 SG_ ESP_SpannungsAnf_02  : 14|2@1+ (1.000000,0.000000) [0.000000|3.000000] "" Vector__XXX
 SG_ ESP_Zaehnezahl  : 16|8@1+ (1.000000,0.000000) [0.000000|255.000000] "" Vector__XXX
 SG_ ESP_Charisma_FahrPr  : 24|4@1+ (1.000000,0.000000) [0.000000|15.000000] "" Vector__XXX
 SG_ ESP_Charisma_Status  : 28|2@1+ (1.000000,0.000000) [0.000000|3.000000] "" Vector__XXX
 SG_ ESP_Wiederstart_Anz_01  : 30|1@1+ (1.000000,0.000000) [0.000000|1.000000] "" Vector__XXX
 SG_ ESP_Wiederstart_Anz_02  : 31|1@1+ (1.000000,0.000000) [0.000000|1.000000] "" Vector__XXX
 SG_ ESP_Wiederstart_Anz_03  : 32|1@1+ (1.000000,0.000000) [0.000000|1.000000] "" Vector__XXX
 SG_ ESP_Wiederstart_Anz_04  : 33|1@1+ (1.000000,0.000000) [0.000000|1.000000] "" Vector__XXX
 SG_ ESP_Stoppverbot_Anz_01  : 34|1@1+ (1.000000,0.000000) [0.000000|1.000000] "" Vector__XXX
 SG_ ESP_Stoppverbot_Anz_02  : 35|1@1+ (1.000000,0.000000) [0.000000|1.000000] "" Vector__XXX
 SG_ ESP_Stoppverbot_Anz_03  : 36|1@1+ (1.000000,0.000000) [0.000000|1.000000] "" Vector__XXX
 SG_ ESP_Stoppverbot_Anz_04  : 37|1@1+ (1.000000,0.000000) [0.000000|1.000000] "" Vector__XXX
 SG_ ESP_Stoppverbot_Anz_05  : 38|1@1+ (1.000000,0.000000) [0.000000|1.000000] "" Vector__XXX
 SG_ ESP_Stoppverbot_Anz_06  : 39|1@1+ (1.000000,0.000000) [0.000000|1.000000] "" Vector__XXX
 SG_ ESP_Stoppverbot_Anz_07  : 40|1@1+ (1.000000,0.000000) [0.000000|1.000000] "" Vector__XXX
 SG_ ESP_Stoppverbot_Anz_Std  : 41|1@1+ (1.000000,0.000000) [0.000000|1.000000] "" Vector__XXX
 SG_ ESP_Dachrelingsensor  : 42|2@1+ (1.000000,0.000000) [0.000000|3.000000] "" Vector__XXX
 SG_ ESP_Stoppverbot_Anz_08  : 44|1@1+ (1.000000,0.000000) [0.000000|1.000000] "" Vector__XXX
 SG_ HDC_Charisma_FahrPr  : 45|4@1+ (1.000000,0.000000) [0.000000|15.000000] "" Vector__XXX
 SG_ HDC_Charisma_Status  : 49|2@1+ (1.000000,0.000000) [0.000000|3.000000] "" Vector__XXX
 SG_ BR_QBit_Reifenumfang  : 51|1@1+ (1.000000,0.000000) [0.000000|1.000000] "" LE1 LE2
 SG_ BR_Reifenumfang  : 52|12@1+ (1.000000,0.000000) [0.000000|4095.000000] "Unit_MilliMeter" LE1 LE2

BO_ 253 ESP_21: 8 ICAS1_Gateway
 SG_ ESP_21_CRC  : 0|8@1+ (1.000000,0.000000) [0.000000|255.000000] "" Airbag LE1 LE2 Motor_BEV
 SG_ ESP_21_BZ  : 8|4@1+ (1.000000,0.000000) [0.000000|15.000000] "" Airbag LE1 LE2 Motor_BEV
 SG_ BR_Eingriffsmoment  : 12|10@1+ (1.000000,-509.000000) [-509.000000|509.000000] "" Vector__XXX
 SG_ ESP_PLA_Bremseingriff  : 22|1@1+ (1.000000,0.000000) [0.000000|1.000000] "" Vector__XXX
 SG_ ESP_Diagnose  : 23|1@1+ (1.000000,0.000000) [0.000000|1.000000] "" Vector__XXX
 SG_ ESC_Reku_Freigabe  : 24|1@1+ (1.000000,0.000000) [0.000000|1.000000] "" Motor_BEV
 SG_ ESC_v_Signal_Qualifier_High_Low  : 25|3@1+ (1.000000,0.000000) [0.000000|7.000000] "" Airbag
 SG_ ESP_Vorsteuerung  : 28|1@1+ (1.000000,0.000000) [0.000000|1.000000] "" Motor_BEV
 SG_ ESP_AWV3_Brems_aktiv  : 29|1@1+ (1.000000,0.000000) [0.000000|1.000000] "" Vector__XXX
 SG_ OBD_Schlechtweg  : 30|1@1+ (1.000000,0.000000) [0.000000|1.000000] "" Vector__XXX
 SG_ OBD_QBit_Schlechtweg  : 31|1@1+ (1.000000,0.000000) [0.000000|1.000000] "" Vector__XXX
 SG_ ESP_v_Signal  : 32|16@1+ (0.010000,0.000000) [0.000000|655.320000] "Unit_KiloMeterPerHour" Airbag LE1 LE2 Motor_BEV
 SG_ ASR_Tastung_passiv  : 48|1@1+ (1.000000,0.000000) [0.000000|1.000000] "" Airbag Motor_BEV
 SG_ ESP_Tastung_passiv  : 49|1@1+ (1.000000,0.000000) [0.000000|1.000000] "" Airbag Motor_BEV
 SG_ ESP_Systemstatus  : 50|1@1+ (1.000000,0.000000) [0.000000|1.000000] "" Motor_BEV
 SG_ ASR_Schalteingriff  : 51|2@1+ (1.000000,0.000000) [0.000000|3.000000] "" Vector__XXX
 SG_ ESP_Haltebestaetigung  : 53|1@1+ (1.000000,0.000000) [0.000000|1.000000] "" Vector__XXX
 SG_ ESP_MKB_Abbruch_Geschw  : 54|1@1+ (1.000000,0.000000) [0.000000|1.000000] "" Vector__XXX
 SG_ ESP_QBit_v_Signal  : 55|1@1+ (1.000000,0.000000) [0.000000|1.000000] "" LE1 LE2 Motor_BEV
 SG_ ABS_Bremsung  : 56|1@1+ (1.000000,0.000000) [0.000000|1.000000] "" Airbag Motor_BEV
 SG_ ASR_Anf  : 57|1@1+ (1.000000,0.000000) [0.000000|1.000000] "" Vector__XXX
 SG_ MSR_Anf  : 58|1@1+ (1.000000,0.000000) [0.000000|1.000000] "" Vector__XXX
 SG_ EBV_Eingriff  : 59|1@1+ (1.000000,0.000000) [0.000000|1.000000] "" Vector__XXX
 SG_ EDS_Eingriff  : 60|1@1+ (1.000000,0.000000) [0.000000|1.000000] "" Motor_BEV
 SG_ ESP_Eingriff  : 61|1@1+ (1.000000,0.000000) [0.000000|1.000000] "" Airbag Motor_BEV
 SG_ ESP_ASP  : 62|1@1+ (1.000000,0.000000) [0.000000|1.000000] "" Vector__XXX
 SG_ ESP_Anhaltevorgang_ACC_aktiv  : 63|1@1+ (1.000000,0.000000) [0.000000|1.000000] "" Vector__XXX

BO_ 795 ESP_24: 8 ICAS1_Gateway
 SG_ ESP_24_CRC  : 0|8@1+ (1.000000,0.000000) [0.000000|255.000000] "" Vector__XXX
 SG_ ESP_24_BZ  : 8|4@1+ (1.000000,0.000000) [0.000000|15.000000] "" Vector__XXX
 SG_ ESP_Lampe  : 12|1@1+ (1.000000,0.000000) [0.000000|1.000000] "" Motor_BEV
 SG_ ABS_Lampe  : 13|1@1+ (1.000000,0.000000) [0.000000|1.000000] "" Vector__XXX
 SG_ BK_Lampe_02  : 14|2@1+ (1.000000,0.000000) [0.000000|3.000000] "" Vector__XXX
 SG_ TC_Lampe  : 16|1@1+ (1.000000,0.000000) [0.000000|1.000000] "" Vector__XXX
 SG_ ESP_m_Raddrehz  : 17|15@1+ (0.002000,0.000000) [0.000000|65.278000] "Unit_Hertz" Vector__XXX
 SG_ ESP_Textanzeigen_03  : 32|5@1+ (1.000000,0.000000) [0.000000|31.000000] "" Vector__XXX
 SG_ ESP_Meldungen  : 37|3@1+ (1.000000,0.000000) [0.000000|7.000000] "" Vector__XXX
 SG_ ESP_Wegimp_VA  : 40|11@1+ (1.000000,0.000000) [0.000000|2047.000000] "" Vector__XXX
 SG_ ESP_Fehlerstatus_Wegimp  : 51|1@1+ (1.000000,0.000000) [0.000000|1.000000] "" Vector__XXX
 SG_ ESP_Wegimp_Ueberlauf  : 52|1@1+ (1.000000,0.000000) [0.000000|1.000000] "" Vector__XXX
 SG_ ESP_QBit_Wegimp_VA  : 53|1@1+ (1.000000,0.000000) [0.000000|1.000000] "" Vector__XXX
 SG_ ESP_HDC_FktLampe  : 54|1@1+ (1.000000,0.000000) [0.000000|1.000000] "" Vector__XXX
 SG_ ESP_Off_Lampe  : 55|1@1+ (1.000000,0.000000) [0.000000|1.000000] "" Airbag
 SG_ ESP_HDC_Regelgeschw  : 56|7@1+ (0.320000,0.000000) [0.320000|39.680000] "Unit_KiloMeterPerHour" Vector__XXX
 SG_ ESP_BKV_Warnung  : 63|1@1+ (1.000000,0.000000) [0.000000|1.000000] "" Vector__XXX

BO_ 2589283617 ESP_30: 8 ICAS1_Gateway
 SG_ ESP_30_CRC  : 0|8@1+ (1.000000,0.000000) [0.000000|255.000000] "" Vector__XXX
 SG_ ESP_30_BZ  : 8|4@1+ (1.000000,0.000000) [0.000000|15.000000] "" Vector__XXX
 SG_ EDS_Charisma_FahrPr  : 12|4@1+ (1.000000,0.000000) [0.000000|15.000000] "" Vector__XXX
 SG_ EDS_Charisma_Status  : 16|2@1+ (1.000000,0.000000) [0.000000|3.000000] "" Vector__XXX
 SG_ HHC_Charisma_Status  : 18|2@1+ (1.000000,0.000000) [0.000000|3.000000] "" Vector__XXX
 SG_ HHC_Charisma_FahrPr  : 20|4@1+ (1.000000,0.000000) [0.000000|15.000000] "" Vector__XXX
 SG_ RLE_Anzeigen  : 24|3@1+ (1.000000,0.000000) [0.000000|7.000000] "" Vector__XXX
 SG_ ESC_Lernfreigabe_Abrollumfang  : 27|1@1+ (1.000000,0.000000) [0.000000|1.000000] "" Vector__XXX
 SG_ ESC_Texte_eBKV_Betaetigung  : 28|4@1+ (1.000000,0.000000) [0.000000|15.000000] "" Vector__XXX
 SG_ ESC_MBK_Meldungen  : 32|2@1+ (1.000000,0.000000) [0.000000|3.000000] "" Vector__XXX
 SG_ ESC_Anf_KL  : 34|5@1+ (3.225806,0.000000) [0.000000|100.000000] "Unit_PerCent" Motor_BEV
 SG_ ESC_Anf_KV  : 39|1@1+ (1.000000,0.000000) [0.000000|1.000000] "" Motor_BEV
 SG_ ESC_FBA_Meldungen  : 40|2@1+ (1.000000,0.000000) [0.000000|3.000000] "" Vector__XXX
 SG_ DBK_Fahrerwarnung  : 42|2@1+ (1.000000,0.000000) [0.000000|3.000000] "" Vector__XXX

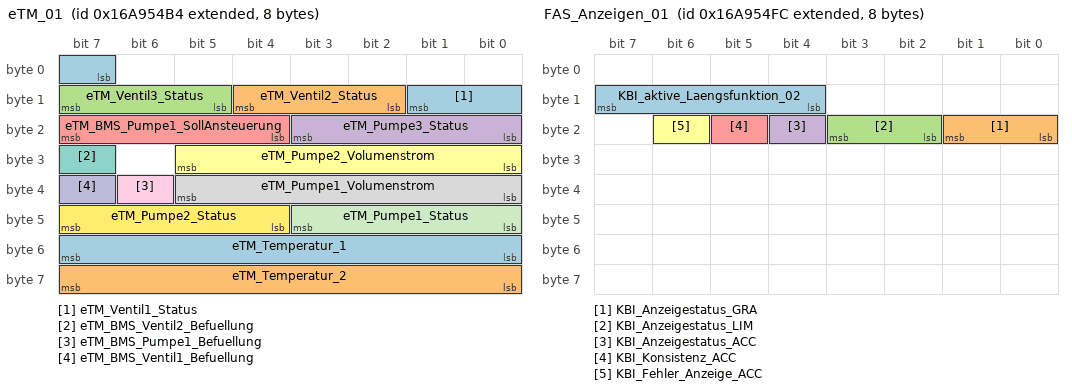
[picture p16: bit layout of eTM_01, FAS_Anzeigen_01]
BO_ 2527679668 eTM_01: 8 Motor_BEV
 SG_ eTM_Ventil1_Status  : 7|3@1+ (1.000000,0.000000) [0.000000|7.000000] "" ICAS1_Gateway
 SG_ eTM_Ventil2_Status  : 10|3@1+ (1.000000,0.000000) [0.000000|7.000000] "" ICAS1_Gateway
 SG_ eTM_Ventil3_Status  : 13|3@1+ (1.000000,0.000000) [0.000000|7.000000] "" ICAS1_Gateway
 SG_ eTM_Pumpe3_Status  : 16|4@1+ (10.000000,0.000000) [0.000000|130.000000] "Unit_PerCent" ICAS1_Gateway
 SG_ eTM_BMS_Pumpe1_SollAnsteuerung  : 20|4@1+ (10.000000,0.000000) [0.000000|130.000000] "Unit_PerCent" ICAS1_Gateway
 SG_ eTM_Pumpe2_Volumenstrom  : 24|6@1+ (0.500000,0.000000) [0.000000|30.500000] "Unit_LiterPerMinut" ICAS1_Gateway LE1 LE2
 SG_ eTM_BMS_Ventil2_Befuellung  : 31|1@1+ (1.000000,0.000000) [0.000000|1.000000] "" ICAS1_Gateway
 SG_ eTM_Pumpe1_Volumenstrom  : 32|6@1+ (0.500000,0.000000) [0.000000|30.500000] "Unit_LiterPerMinut" ICAS1_Gateway LE1 LE2
 SG_ eTM_BMS_Pumpe1_Befuellung  : 38|1@1+ (1.000000,0.000000) [0.000000|1.000000] "" ICAS1_Gateway
 SG_ eTM_BMS_Ventil1_Befuellung  : 39|1@1+ (1.000000,0.000000) [0.000000|1.000000] "" ICAS1_Gateway
 SG_ eTM_Pumpe1_Status  : 40|4@1+ (10.000000,0.000000) [0.000000|130.000000] "Unit_PerCent" ICAS1_Gateway LE1 LE2
 SG_ eTM_Pumpe2_Status  : 44|4@1+ (10.000000,0.000000) [0.000000|130.000000] "Unit_PerCent" ICAS1_Gateway LE1 LE2
 SG_ eTM_Temperatur_1  : 48|8@1+ (0.750000,-40.000000) [-40.000000|149.750000] "Unit_DegreCelsi" ICAS1_Gateway LE1 LE2
 SG_ eTM_Temperatur_2  : 56|8@1+ (0.750000,-40.000000) [-40.000000|149.750000] "Unit_DegreCelsi" ICAS1_Gateway LE1 LE2

BO_ 2527679740 FAS_Anzeigen_01: 8 ICAS1_KommunikationsServer
 SG_ KBI_aktive_Laengsfunktion_02  : 12|4@1+ (1.000000,0.000000) [0.000000|15.000000] "" Motor_BEV
 SG_ KBI_Anzeigestatus_GRA  : 16|2@1+ (1.000000,0.000000) [0.000000|3.000000] "" Motor_BEV
 SG_ KBI_Anzeigestatus_LIM  : 18|2@1+ (1.000000,0.000000) [0.000000|3.000000] "" Motor_BEV
 SG_ KBI_Anzeigestatus_ACC  : 20|1@1+ (1.000000,0.000000) [0.000000|1.000000] "" Vector__XXX
 SG_ KBI_Konsistenz_ACC  : 21|1@1+ (1.000000,0.000000) [0.000000|1.000000] "" Vector__XXX
 SG_ KBI_Fehler_Anzeige_ACC  : 22|1@1+ (1.000000,0.000000) [0.000000|1.000000] "" Vector__XXX

BO_ 2589283684 FoD_01: 8 ICAS1_Gateway
 SG_ GRA_FoD_Status  : 58|2@1+ (1.000000,0.000000) [0.000000|3.000000] "" Vector__XXX
 SG_ FoD_Transmission_Info  : 60|2@1+ (1.000000,0.000000) [0.000000|3.000000] "" Motor_BEV

BO_ 2549875574 FoD_MO_01_Req: 8 ICAS1_Gateway
 SG_ FoD_MO_01_Req_Data  : 0|64@1+ (1.000000,0.000000) [0.000000|18446744073709551616.000000] "" Motor_BEV

BO_ 2550006646 FoD_MO_01_Resp: 8 Motor_BEV
 SG_ FoD_MO_01_Resp_Data  : 0|64@1+ (1.000000,0.000000) [0.000000|18446744073709551616.000000] "" ICAS1_Gateway

BO_ 987 Gateway_72: 8 ICAS1_Gateway
 SG_ BCM_01_alt  : 0|1@1+ (1.000000,0.000000) [0.000000|1.000000] "" Airbag
 SG_ SMLS_01_alt  : 1|1@1+ (1.000000,0.000000) [0.000000|1.000000] "" Vector__XXX
 SG_ ZV_02_alt  : 2|1@1+ (1.000000,0.000000) [0.000000|1.000000] "" Vector__XXX
 SG_ Wischer_01_alt  : 3|1@1+ (1.000000,0.000000) [0.000000|1.000000] "" Vector__XXX
 SG_ Anhaenger_01_alt  : 4|1@1+ (1.000000,0.000000) [0.000000|1.000000] "" Airbag
 SG_ Klima_Sensor_02_alt  : 5|1@1+ (1.000000,0.000000) [0.000000|1.000000] "" Vector__XXX
 SG_ Verdeck_01_alt  : 6|1@1+ (1.000000,0.000000) [0.000000|1.000000] "" Vector__XXX
 SG_ Klima_11_alt  : 7|1@1+ (1.000000,0.000000) [0.000000|1.000000] "" Vector__XXX
 SG_ WFS_01_alt  : 8|1@1+ (1.000000,0.000000) [0.000000|1.000000] "" Vector__XXX
 SG_ Licht_Anf_01_alt  : 9|1@1+ (1.000000,0.000000) [0.000000|1.000000] "" Vector__XXX
 SG_ ZV_verriegelt_extern_soll  : 10|1@1+ (1.000000,0.000000) [0.000000|1.000000] "" Vector__XXX
 SG_ BH_Lichthupe  : 11|1@1+ (1.000000,0.000000) [0.000000|1.000000] "" Vector__XXX
 SG_ WFS_Klemmenfreigabe  : 12|1@1+ (1.000000,0.000000) [0.000000|1.000000] "" Vector__XXX
 SG_ ZV_Tankklappe_offen  : 13|1@1+ (1.000000,0.000000) [0.000000|1.000000] "" Vector__XXX
 SG_ AAG_Anhaenger_abgesteckt  : 14|1@1+ (1.000000,0.000000) [0.000000|1.000000] "" Vector__XXX
 SG_ BCM1_LDS_Stellung  : 15|3@1+ (1.000000,0.000000) [0.000000|7.000000] "" Vector__XXX
 SG_ VS_Verdeck_Anf  : 18|1@1+ (1.000000,0.000000) [0.000000|1.000000] "" Vector__XXX
 SG_ VS_VD_entriegelt  : 19|1@1+ (1.000000,0.000000) [0.000000|1.000000] "" Vector__XXX
 SG_ ZV_HFS_offen  : 20|1@1+ (1.000000,0.000000) [0.000000|1.000000] "" Vector__XXX
 SG_ ZV_HBFS_offen  : 21|1@1+ (1.000000,0.000000) [0.000000|1.000000] "" Vector__XXX
 SG_ VS_VD_offen_ver  : 22|1@1+ (1.000000,0.000000) [0.000000|1.000000] "" Vector__XXX
 SG_ VS_VD_zu_ver  : 23|1@1+ (1.000000,0.000000) [0.000000|1.000000] "" Vector__XXX
 SG_ ZV_BT_offen  : 24|1@1+ (1.000000,0.000000) [0.000000|1.000000] "" Vector__XXX
 SG_ BCM1_Rueckfahrlicht_Schalter  : 25|1@1+ (1.000000,0.000000) [0.000000|1.000000] "" Airbag Motor_BEV
 SG_ ZV_FT_offen  : 26|1@1+ (1.000000,0.000000) [0.000000|1.000000] "" Vector__XXX
 SG_ Wischer_vorne_aktiv  : 27|1@1+ (1.000000,0.000000) [0.000000|1.000000] "" Vector__XXX
 SG_ AAG_Anhaenger_erkannt  : 28|1@1+ (1.000000,0.000000) [0.000000|1.000000] "" Airbag
 SG_ BCM1_MH_Schalter  : 29|1@1+ (1.000000,0.000000) [0.000000|1.000000] "" Vector__XXX
 SG_ ZV_HD_offen  : 30|1@1+ (1.000000,0.000000) [0.000000|1.000000] "" Vector__XXX
 SG_ Waschen_vorne_aktiv  : 31|1@1+ (1.000000,0.000000) [0.000000|1.000000] "" Vector__XXX
 SG_ KL_Thermomanagement  : 32|2@1+ (1.000000,0.000000) [0.000000|3.000000] "" Vector__XXX
 SG_ WFS_Schluessel_Fahrberecht  : 34|4@1+ (1.000000,0.000000) [0.000000|15.000000] "" Vector__XXX
 SG_ BCM_Rueckfahrlicht_Anf  : 38|1@1+ (1.000000,0.000000) [0.000000|1.000000] "" Vector__XXX
 SG_ WWSs_01_alt  : 39|1@1+ (1.000000,0.000000) [0.000000|1.000000] "" Vector__XXX
 SG_ BCM_Tankklappensteller_Fehler  : 40|1@1+ (1.000000,0.000000) [0.000000|1.000000] "" Vector__XXX
 SG_ AAG_LED_aktiv  : 41|1@1+ (1.000000,0.000000) [0.000000|1.000000] "" Vector__XXX
 SG_ ZV_verriegelt_soll  : 42|2@1+ (1.000000,0.000000) [0.000000|3.000000] "" Vector__XXX
 SG_ ZV_Schluessel_Zugang  : 44|4@1+ (1.000000,0.000000) [0.000000|15.000000] "" Vector__XXX
 SG_ WFS_ID_Geb_autorisiert_in_Kl15  : 48|1@1+ (1.000000,0.000000) [0.000000|1.000000] "" Vector__XXX
 SG_ BH_Fernlicht  : 49|1@1+ (1.000000,0.000000) [0.000000|1.000000] "" Vector__XXX
 SG_ BH_Blinker_li  : 50|1@1+ (1.000000,0.000000) [0.000000|1.000000] "" Vector__XXX
 SG_ BH_Blinker_re  : 51|1@1+ (1.000000,0.000000) [0.000000|1.000000] "" Vector__XXX
 SG_ BCM1_OBD_FStatus_ATemp  : 52|4@1+ (1.000000,0.000000) [0.000000|15.000000] "" Vector__XXX
 SG_ BCM1_Aussen_Temp_ungef  : 56|8@1+ (0.500000,-50.000000) [-50.000000|76.000000] "Unit_DegreCelsi" Vector__XXX

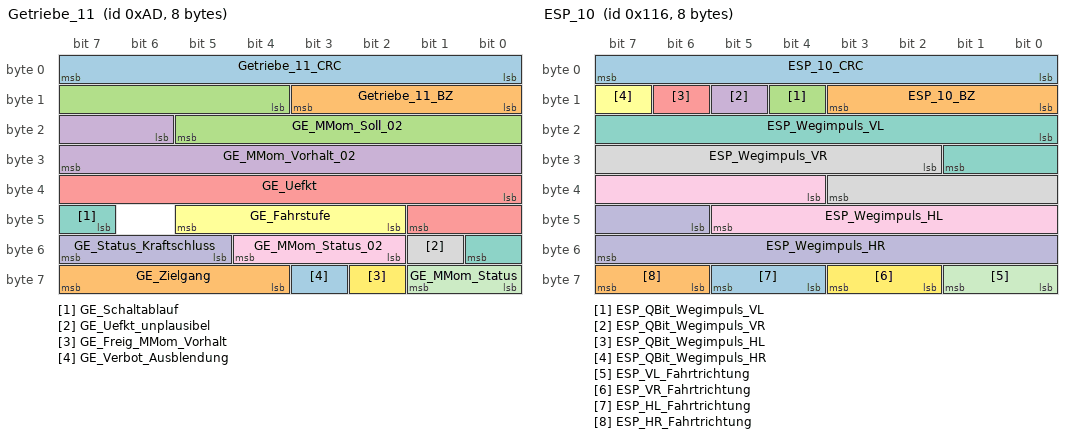
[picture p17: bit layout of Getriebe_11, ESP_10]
BO_ 173 Getriebe_11: 8 Motor_BEV
 SG_ Getriebe_11_CRC  : 0|8@1+ (1.000000,0.000000) [0.000000|255.000000] "" ICAS1_Gateway
 SG_ Getriebe_11_BZ  : 8|4@1+ (1.000000,0.000000) [0.000000|15.000000] "" ICAS1_Gateway
 SG_ GE_MMom_Soll_02  : 12|10@1+ (1.000000,-509.000000) [-509.000000|509.000000] "" ICAS1_Gateway
 SG_ GE_MMom_Vorhalt_02  : 22|10@1+ (1.000000,-509.000000) [-509.000000|509.000000] "" ICAS1_Gateway
 SG_ GE_Uefkt  : 32|10@1+ (0.100000,0.000000) [0.000000|102.200000] "" ICAS1_Gateway
 SG_ GE_Fahrstufe  : 42|4@1+ (1.000000,0.000000) [0.000000|15.000000] "" ICAS1_Gateway
 SG_ GE_Schaltablauf  : 47|2@1+ (1.000000,0.000000) [0.000000|3.000000] "" ICAS1_Gateway
 SG_ GE_Uefkt_unplausibel  : 49|1@1+ (1.000000,0.000000) [0.000000|1.000000] "" ICAS1_Gateway
 SG_ GE_MMom_Status_02  : 50|3@1+ (1.000000,0.000000) [0.000000|7.000000] "" ICAS1_Gateway
 SG_ GE_Status_Kraftschluss  : 53|3@1+ (1.000000,0.000000) [0.000000|7.000000] "" ICAS1_Gateway
 SG_ GE_MMom_Status  : 56|2@1+ (1.000000,0.000000) [0.000000|3.000000] "" ICAS1_Gateway
 SG_ GE_Freig_MMom_Vorhalt  : 58|1@1+ (1.000000,0.000000) [0.000000|1.000000] "" ICAS1_Gateway
 SG_ GE_Verbot_Ausblendung  : 59|1@1+ (1.000000,0.000000) [0.000000|1.000000] "" ICAS1_Gateway
 SG_ GE_Zielgang  : 60|4@1+ (1.000000,0.000000) [0.000000|15.000000] "" ICAS1_Gateway

BU_:  Airbag BAP_Tester ICAS1_Gateway ICAS1_KommunikationsServer LE1 LE2 Motor_BEV Schaltbetaetigung

BO_ 252 ESC_51: 48 ICAS1_Gateway
 SG_ ESC_51_CRC  : 0|8@1+ (1.000000,0.000000) [0.000000|255.000000] "" Motor_BEV
 SG_ ESC_51_BZ  : 8|4@1+ (1.000000,0.000000) [0.000000|15.000000] "" Motor_BEV
 SG_ ESC_aktBr_Modus  : 12|2@1+ (1.000000,0.000000) [0.000000|3.000000] "" Vector__XXX
 SG_ ESC_Blending_Solldruck  : 14|10@1+ (0.250000,0.000000) [0.000000|250.000000] "Unit_Bar" Vector__XXX
 SG_ ESC_aktBr_Volumenstrom  : 24|16@1+ (0.007812,-252.000000) [-252.000000|252.000000] "Unit_MilliLiterPerSec" Vector__XXX
 SG_ ESC_EBKV_Kraftblending_Modus  : 40|2@1+ (1.000000,0.000000) [0.000000|3.000000] "" Vector__XXX
 SG_ ESC_Bremsdruck_Modell  : 42|10@1+ (0.250000,0.000000) [0.000000|250.000000] "Unit_Bar" Motor_BEV
 SG_ ESC_Bremsdruck_02  : 52|10@1+ (0.300000,-30.000000) [-30.000000|276.600000] "Unit_Bar" Vector__XXX
 SG_ ESC_QBit_Bremsdruck_02  : 62|1@1+ (1.000000,0.000000) [0.000000|1.000000] "" Vector__XXX
 SG_ ESP_HL_Radgeschw_02  : 64|16@1+ (0.007500,0.000000) [0.000000|491.490000] "Unit_KiloMeterPerHour" Airbag LE1 LE2 Motor_BEV
 SG_ ESP_HR_Radgeschw_02  : 80|16@1+ (0.007500,0.000000) [0.000000|491.490000] "Unit_KiloMeterPerHour" Airbag LE1 LE2 Motor_BEV
 SG_ ESP_VL_Radgeschw_02  : 96|16@1+ (0.007500,0.000000) [0.000000|491.490000] "Unit_KiloMeterPerHour" Airbag LE1 LE2 Motor_BEV
 SG_ ESP_VR_Radgeschw_02  : 112|16@1+ (0.007500,0.000000) [0.000000|491.490000] "Unit_KiloMeterPerHour" Airbag LE1 LE2 Motor_BEV
 SG_ ESP_FZR_uebersteuern  : 128|8@1+ (0.004000,0.000000) [0.000000|1.000000] "" Vector__XXX
 SG_ ESP_FZR_untersteuern  : 136|8@1+ (0.004000,0.000000) [0.000000|1.000000] "" Vector__XXX
 SG_ ESC_Anf_Mindestreku  : 144|1@1+ (1.000000,0.000000) [0.000000|1.000000] "" Motor_BEV
 SG_ ESC_GMV_aktiv  : 145|3@1+ (1.000000,0.000000) [0.000000|7.000000] "" Vector__XXX
 SG_ ESC_GMV_nicht_verfuegbar  : 148|1@1+ (1.000000,0.000000) [0.000000|1.000000] "" Vector__XXX
 SG_ ESC_Status_vRef_Stuetzeingriff  : 149|1@1+ (1.000000,0.000000) [0.000000|1.000000] "" Motor_BEV
 SG_ FDR_Allradverteilung_aktiv  : 150|1@1+ (1.000000,0.000000) [0.000000|1.000000] "" Vector__XXX
 SG_ FDR_Anf_Allradbetrieb  : 151|1@1+ (1.000000,0.000000) [0.000000|1.000000] "" Vector__XXX
 SG_ ESP_HL_Bremsmoment  : 152|8@1+ (20.000000,0.000000) [0.000000|5060.000000] "Unit_NewtoMeter" Motor_BEV
 SG_ ESP_HR_Bremsmoment  : 160|8@1+ (20.000000,0.000000) [0.000000|5060.000000] "Unit_NewtoMeter" Motor_BEV
 SG_ ESP_VR_Bremsmoment  : 168|8@1+ (40.000000,0.000000) [0.000000|10120.000000] "Unit_NewtoMeter" Motor_BEV
 SG_ ESP_VL_Bremsmoment  : 176|8@1+ (40.000000,0.000000) [0.000000|10120.000000] "Unit_NewtoMeter" Motor_BEV
 SG_ ESP_FDR_uebersteuern  : 184|8@1+ (0.004000,0.000000) [0.000000|1.000000] "" Motor_BEV
 SG_ ESP_FDR_untersteuern  : 192|8@1+ (0.004000,0.000000) [0.000000|1.000000] "" Motor_BEV
 SG_ TSMomBegrenzung  : 268|12@1+ (3.000000,-12279.000000) [-12279.000000|0.000000] "" Motor_BEV
 SG_ ESC_Allrad_Anteil_max_sek  : 280|9@1+ (0.200000,0.000000) [0.000000|100.000000] "Unit_PerCent" Motor_BEV
 SG_ ESC_Allrad_Anteil_min_sek  : 289|9@1+ (0.200000,0.000000) [0.000000|100.000000] "Unit_PerCent" Motor_BEV
 SG_ ESC_Status_Eingriff  : 298|2@1+ (1.000000,0.000000) [0.000000|3.000000] "" Motor_BEV
 SG_ ESC_Status_Eingriff_sek  : 300|2@1+ (1.000000,0.000000) [0.000000|3.000000] "" Motor_BEV
 SG_ ESC_MomRad_Eingriff  : 302|13@1+ (3.000000,-12279.000000) [-12279.000000|12279.000000] "Unit_None" Motor_BEV
 SG_ ESC_MomRad_Eingriff_sek  : 315|13@1+ (3.000000,-12279.000000) [-12279.000000|12279.000000] "Unit_None" Motor_BEV
 SG_ ESC_Achsdrehzahl_Max  : 328|14@1+ (0.400000,-800.000000) [-800.000000|5752.400000] "Unit_MinutInver" Motor_BEV
 SG_ ESC_Achsdrehzahl_Min  : 342|14@1+ (0.400000,-800.000000) [-800.000000|5752.400000] "Unit_MinutInver" Motor_BEV
 SG_ ESC_Achsdrehzahl_Max_sek  : 356|14@1+ (0.400000,-800.000000) [-800.000000|5752.400000] "Unit_MinutInver" Motor_BEV
 SG_ ESC_Achsdrehzahl_Min_sek  : 370|14@1+ (0.400000,-800.000000) [-800.000000|5752.400000] "Unit_MinutInver" Motor_BEV

BO_ 2463978647 ESC_52: 16 ICAS1_Gateway
 SG_ ESP_ACC_LDE  : 12|1@1+ (1.000000,0.000000) [0.000000|1.000000] "" Vector__XXX
 SG_ ESP_Allrad_Antrieb  : 13|1@1+ (1.000000,0.000000) [0.000000|1.000000] "" Vector__XXX
 SG_ ESP_Codierung_ADS  : 14|2@1+ (1.000000,0.000000) [0.000000|3.000000] "" Vector__XXX
 SG_ ESP_RTA_HL  : 16|8@1+ (0.048828,-6.201170) [-6.201170|6.152346] "Unit_PerCent" Motor_BEV
 SG_ ESP_RTA_HR  : 24|8@1+ (0.048828,-6.201170) [-6.201170|6.152346] "Unit_PerCent" Motor_BEV
 SG_ ESP_RTA_VR  : 32|8@1+ (0.048828,-6.201170) [-6.201170|6.152346] "Unit_PerCent" Motor_BEV
 SG_ OBD_Fehler_Radsensor_HL  : 40|4@1+ (1.000000,0.000000) [0.000000|15.000000] "" Motor_BEV
 SG_ OBD_Fehler_Radsensor_HR  : 44|4@1+ (1.000000,0.000000) [0.000000|15.000000] "" Motor_BEV
 SG_ OBD_Fehler_Radsensor_VL  : 48|4@1+ (1.000000,0.000000) [0.000000|15.000000] "" Motor_BEV
 SG_ OBD_Fehler_Radsensor_VR  : 52|4@1+ (1.000000,0.000000) [0.000000|15.000000] "" Motor_BEV
 SG_ ESP_Qualifizierung_Antriebsart  : 56|1@1+ (1.000000,0.000000) [0.000000|1.000000] "" Vector__XXX
 SG_ ESP_Offroad_Modus  : 57|1@1+ (1.000000,0.000000) [0.000000|1.000000] "" Vector__XXX
 SG_ ESP_MKB_ausloesbar  : 58|1@1+ (1.000000,0.000000) [0.000000|1.000000] "" Vector__XXX
 SG_ ESP_Stat_FallBack_eBKV  : 59|1@1+ (1.000000,0.000000) [0.000000|1.000000] "" Vector__XXX
 SG_ ESP_CM_Variante  : 60|1@1+ (1.000000,0.000000) [0.000000|1.000000] "" Vector__XXX
 SG_ ESP_OBD_Status  : 61|1@1+ (1.000000,0.000000) [0.000000|1.000000] "" Motor_BEV
 SG_ ESP_Rollenmodus_Deaktivieren  : 62|1@1+ (1.000000,0.000000) [0.000000|1.000000] "" Motor_BEV
 SG_ ESP_nachtr_Stopp_Anf  : 63|1@1+ (1.000000,0.000000) [0.000000|1.000000] "" Vector__XXX

BO_ 2527679683 ESC_ASM_01: 8 ICAS1_Gateway
 SG_ ESC_ASM_Ereignis  : 0|8@1+ (1.000000,0.000000) [1.000000|254.000000] "Unit_None" Airbag
 SG_ ESC_ASM_Zeitstempel  : 8|8@1+ (0.080000,0.000000) [0.000000|20.320000] "Unit_Secon" Airbag
 SG_ ESC_ASM_Data_1  : 16|8@1+ (1.000000,0.000000) [0.000000|255.000000] "" Airbag
 SG_ ESC_ASM_Data_2  : 24|8@1+ (1.000000,0.000000) [0.000000|255.000000] "" Airbag
 SG_ ESC_ASM_Data_3  : 32|8@1+ (1.000000,0.000000) [0.000000|255.000000] "" Airbag
 SG_ ESC_ASM_Data_4  : 40|8@1+ (1.000000,0.000000) [0.000000|255.000000] "" Airbag
 SG_ ESC_ASM_Data_5  : 48|8@1+ (1.000000,0.000000) [0.000000|255.000000] "" Airbag
 SG_ ESC_ASM_Data_6  : 56|8@1+ (1.000000,0.000000) [0.000000|255.000000] "" Airbag

BO_ 278 ESP_10: 8 ICAS1_Gateway
 SG_ ESP_10_CRC  : 0|8@1+ (1.000000,0.000000) [0.000000|255.000000] "" Vector__XXX
 SG_ ESP_10_BZ  : 8|4@1+ (1.000000,0.000000) [0.000000|15.000000] "" Vector__XXX
 SG_ ESP_QBit_Wegimpuls_VL  : 12|1@1+ (1.000000,0.000000) [0.000000|1.000000] "" Motor_BEV
 SG_ ESP_QBit_Wegimpuls_VR  : 13|1@1+ (1.000000,0.000000) [0.000000|1.000000] "" Motor_BEV
 SG_ ESP_QBit_Wegimpuls_HL  : 14|1@1+ (1.000000,0.000000) [0.000000|1.000000] "" Motor_BEV
 SG_ ESP_QBit_Wegimpuls_HR  : 15|1@1+ (1.000000,0.000000) [0.000000|1.000000] "" Motor_BEV
 SG_ ESP_Wegimpuls_VL  : 16|10@1+ (1.000000,0.000000) [0.000000|1000.000000] "" Motor_BEV
 SG_ ESP_Wegimpuls_VR  : 26|10@1+ (1.000000,0.000000) [0.000000|1000.000000] "" Motor_BEV
 SG_ ESP_Wegimpuls_HL  : 36|10@1+ (1.000000,0.000000) [0.000000|1000.000000] "" Motor_BEV
 SG_ ESP_Wegimpuls_HR  : 46|10@1+ (1.000000,0.000000) [0.000000|1000.000000] "" Motor_BEV
 SG_ ESP_VL_Fahrtrichtung  : 56|2@1+ (1.000000,0.000000) [0.000000|3.000000] "" Motor_BEV
 SG_ ESP_VR_Fahrtrichtung  : 58|2@1+ (1.000000,0.000000) [0.000000|3.000000] "" Motor_BEV
 SG_ ESP_HL_Fahrtrichtung  : 60|2@1+ (1.000000,0.000000) [0.000000|3.000000] "" Motor_BEV
 SG_ ESP_HR_Fahrtrichtung  : 62|2@1+ (1.000000,0.000000) [0.000000|3.000000] "" Motor_BEV

BO_ 1629 ESP_20: 8 ICAS1_Gateway
 SG_ ESP_20_CRC  : 0|8@1+ (1.000000,0.000000) [0.000000|255.000000] "" Vector__XXX
 SG_ ESP_20_BZ  : 8|4@1+ (1.000000,0.000000) [0.000000|15.000000] "" Vector__XXX
 SG_ BR_Systemart  : 12|2@1+ (1.000000,0.000000) [0.000000|3.000000] "" Vector__XXX
 SG_ ESP_SpannungsAnf_02  : 14|2@1+ (1.000000,0.000000) [0.000000|3.000000] "" Vector__XXX
 SG_ ESP_Zaehnezahl  : 16|8@1+ (1.000000,0.000000) [0.000000|255.000000] "" Vector__XXX
 SG_ ESP_Charisma_FahrPr  : 24|4@1+ (1.000000,0.000000) [0.000000|15.000000] "" Vector__XXX
 SG_ ESP_Charisma_Status  : 28|2@1+ (1.000000,0.000000) [0.000000|3.000000] "" Vector__XXX
 SG_ ESP_Wiederstart_Anz_01  : 30|1@1+ (1.000000,0.000000) [0.000000|1.000000] "" Vector__XXX
 SG_ ESP_Wiederstart_Anz_02  : 31|1@1+ (1.000000,0.000000) [0.000000|1.000000] "" Vector__XXX
 SG_ ESP_Wiederstart_Anz_03  : 32|1@1+ (1.000000,0.000000) [0.000000|1.000000] "" Vector__XXX
 SG_ ESP_Wiederstart_Anz_04  : 33|1@1+ (1.000000,0.000000) [0.000000|1.000000] "" Vector__XXX
 SG_ ESP_Stoppverbot_Anz_01  : 34|1@1+ (1.000000,0.000000) [0.000000|1.000000] "" Vector__XXX
 SG_ ESP_Stoppverbot_Anz_02  : 35|1@1+ (1.000000,0.000000) [0.000000|1.000000] "" Vector__XXX
 SG_ ESP_Stoppverbot_Anz_03  : 36|1@1+ (1.000000,0.000000) [0.000000|1.000000] "" Vector__XXX
 SG_ ESP_Stoppverbot_Anz_04  : 37|1@1+ (1.000000,0.000000) [0.000000|1.000000] "" Vector__XXX
 SG_ ESP_Stoppverbot_Anz_05  : 38|1@1+ (1.000000,0.000000) [0.000000|1.000000] "" Vector__XXX
 SG_ ESP_Stoppverbot_Anz_06  : 39|1@1+ (1.000000,0.000000) [0.000000|1.000000] "" Vector__XXX
 SG_ ESP_Stoppverbot_Anz_07  : 40|1@1+ (1.000000,0.000000) [0.000000|1.000000] "" Vector__XXX
 SG_ ESP_Stoppverbot_Anz_Std  : 41|1@1+ (1.000000,0.000000) [0.000000|1.000000] "" Vector__XXX
 SG_ ESP_Dachrelingsensor  : 42|2@1+ (1.000000,0.000000) [0.000000|3.000000] "" Vector__XXX
 SG_ ESP_Stoppverbot_Anz_08  : 44|1@1+ (1.000000,0.000000) [0.000000|1.000000] "" Vector__XXX
 SG_ HDC_Charisma_FahrPr  : 45|4@1+ (1.000000,0.000000) [0.000000|15.000000] "" Vector__XXX
 SG_ HDC_Charisma_Status  : 49|2@1+ (1.000000,0.000000) [0.000000|3.000000] "" Vector__XXX
 SG_ BR_QBit_Reifenumfang  : 51|1@1+ (1.000000,0.000000) [0.000000|1.000000] "" LE1 LE2
 SG_ BR_Reifenumfang  : 52|12@1+ (1.000000,0.000000) [0.000000|4095.000000] "Unit_MilliMeter" LE1 LE2

BO_ 253 ESP_21: 8 ICAS1_Gateway
 SG_ ESP_21_CRC  : 0|8@1+ (1.000000,0.000000) [0.000000|255.000000] "" Airbag LE1 LE2 Motor_BEV
 SG_ ESP_21_BZ  : 8|4@1+ (1.000000,0.000000) [0.000000|15.000000] "" Airbag LE1 LE2 Motor_BEV
 SG_ BR_Eingriffsmoment  : 12|10@1+ (1.000000,-509.000000) [-509.000000|509.000000] "" Vector__XXX
 SG_ ESP_PLA_Bremseingriff  : 22|1@1+ (1.000000,0.000000) [0.000000|1.000000] "" Vector__XXX
 SG_ ESP_Diagnose  : 23|1@1+ (1.000000,0.000000) [0.000000|1.000000] "" Vector__XXX
 SG_ ESC_Reku_Freigabe  : 24|1@1+ (1.000000,0.000000) [0.000000|1.000000] "" Motor_BEV
 SG_ ESC_v_Signal_Qualifier_High_Low  : 25|3@1+ (1.000000,0.000000) [0.000000|7.000000] "" Airbag
 SG_ ESP_Vorsteuerung  : 28|1@1+ (1.000000,0.000000) [0.000000|1.000000] "" Motor_BEV
 SG_ ESP_AWV3_Brems_aktiv  : 29|1@1+ (1.000000,0.000000) [0.000000|1.000000] "" Vector__XXX
 SG_ OBD_Schlechtweg  : 30|1@1+ (1.000000,0.000000) [0.000000|1.000000] "" Vector__XXX
 SG_ OBD_QBit_Schlechtweg  : 31|1@1+ (1.000000,0.000000) [0.000000|1.000000] "" Vector__XXX
 SG_ ESP_v_Signal  : 32|16@1+ (0.010000,0.000000) [0.000000|655.320000] "Unit_KiloMeterPerHour" Airbag LE1 LE2 Motor_BEV
 SG_ ASR_Tastung_passiv  : 48|1@1+ (1.000000,0.000000) [0.000000|1.000000] "" Airbag Motor_BEV
 SG_ ESP_Tastung_passiv  : 49|1@1+ (1.000000,0.000000) [0.000000|1.000000] "" Airbag Motor_BEV
 SG_ ESP_Systemstatus  : 50|1@1+ (1.000000,0.000000) [0.000000|1.000000] "" Motor_BEV
 SG_ ASR_Schalteingriff  : 51|2@1+ (1.000000,0.000000) [0.000000|3.000000] "" Vector__XXX
 SG_ ESP_Haltebestaetigung  : 53|1@1+ (1.000000,0.000000) [0.000000|1.000000] "" Vector__XXX
 SG_ ESP_MKB_Abbruch_Geschw  : 54|1@1+ (1.000000,0.000000) [0.000000|1.000000] "" Vector__XXX
 SG_ ESP_QBit_v_Signal  : 55|1@1+ (1.000000,0.000000) [0.000000|1.000000] "" LE1 LE2 Motor_BEV
 SG_ ABS_Bremsung  : 56|1@1+ (1.000000,0.000000) [0.000000|1.000000] "" Airbag Motor_BEV
 SG_ ASR_Anf  : 57|1@1+ (1.000000,0.000000) [0.000000|1.000000] "" Vector__XXX
 SG_ MSR_Anf  : 58|1@1+ (1.000000,0.000000) [0.000000|1.000000] "" Vector__XXX
 SG_ EBV_Eingriff  : 59|1@1+ (1.000000,0.000000) [0.000000|1.000000] "" Vector__XXX
 SG_ EDS_Eingriff  : 60|1@1+ (1.000000,0.000000) [0.000000|1.000000] "" Motor_BEV
 SG_ ESP_Eingriff  : 61|1@1+ (1.000000,0.000000) [0.000000|1.000000] "" Airbag Motor_BEV
 SG_ ESP_ASP  : 62|1@1+ (1.000000,0.000000) [0.000000|1.000000] "" Vector__XXX
 SG_ ESP_Anhaltevorgang_ACC_aktiv  : 63|1@1+ (1.000000,0.000000) [0.000000|1.000000] "" Vector__XXX

BO_ 795 ESP_24: 8 ICAS1_Gateway
 SG_ ESP_24_CRC  : 0|8@1+ (1.000000,0.000000) [0.000000|255.000000] "" Vector__XXX
 SG_ ESP_24_BZ  : 8|4@1+ (1.000000,0.000000) [0.000000|15.000000] "" Vector__XXX
 SG_ ESP_Lampe  : 12|1@1+ (1.000000,0.000000) [0.000000|1.000000] "" Motor_BEV
 SG_ ABS_Lampe  : 13|1@1+ (1.000000,0.000000) [0.000000|1.000000] "" Vector__XXX
 SG_ BK_Lampe_02  : 14|2@1+ (1.000000,0.000000) [0.000000|3.000000] "" Vector__XXX
 SG_ TC_Lampe  : 16|1@1+ (1.000000,0.000000) [0.000000|1.000000] "" Vector__XXX
 SG_ ESP_m_Raddrehz  : 17|15@1+ (0.002000,0.000000) [0.000000|65.278000] "Unit_Hertz" Vector__XXX
 SG_ ESP_Textanzeigen_03  : 32|5@1+ (1.000000,0.000000) [0.000000|31.000000] "" Vector__XXX
 SG_ ESP_Meldungen  : 37|3@1+ (1.000000,0.000000) [0.000000|7.000000] "" Vector__XXX
 SG_ ESP_Wegimp_VA  : 40|11@1+ (1.000000,0.000000) [0.000000|2047.000000] "" Vector__XXX
 SG_ ESP_Fehlerstatus_Wegimp  : 51|1@1+ (1.000000,0.000000) [0.000000|1.000000] "" Vector__XXX
 SG_ ESP_Wegimp_Ueberlauf  : 52|1@1+ (1.000000,0.000000) [0.000000|1.000000] "" Vector__XXX
 SG_ ESP_QBit_Wegimp_VA  : 53|1@1+ (1.000000,0.000000) [0.000000|1.000000] "" Vector__XXX
 SG_ ESP_HDC_FktLampe  : 54|1@1+ (1.000000,0.000000) [0.000000|1.000000] "" Vector__XXX
 SG_ ESP_Off_Lampe  : 55|1@1+ (1.000000,0.000000) [0.000000|1.000000] "" Airbag
 SG_ ESP_HDC_Regelgeschw  : 56|7@1+ (0.320000,0.000000) [0.320000|39.680000] "Unit_KiloMeterPerHour" Vector__XXX
 SG_ ESP_BKV_Warnung  : 63|1@1+ (1.000000,0.000000) [0.000000|1.000000] "" Vector__XXX

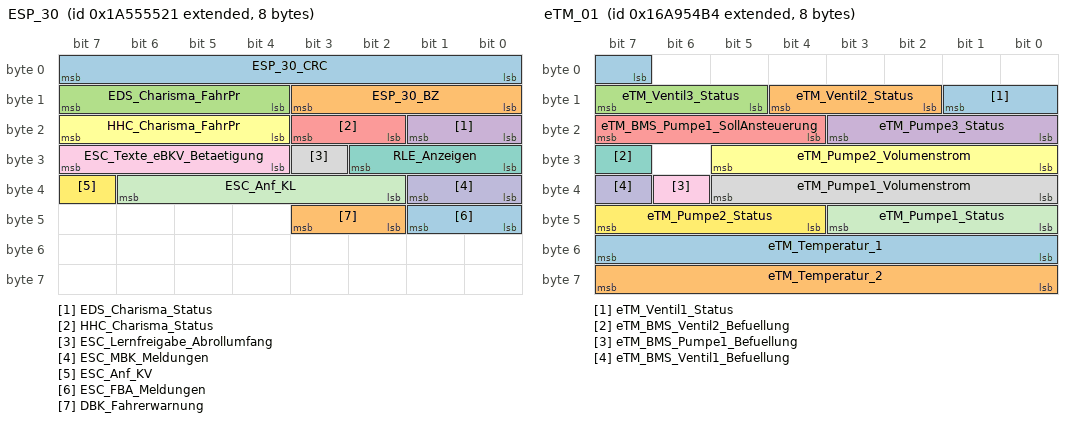
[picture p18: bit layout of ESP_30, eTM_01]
BO_ 2589283617 ESP_30: 8 ICAS1_Gateway
 SG_ ESP_30_CRC  : 0|8@1+ (1.000000,0.000000) [0.000000|255.000000] "" Vector__XXX
 SG_ ESP_30_BZ  : 8|4@1+ (1.000000,0.000000) [0.000000|15.000000] "" Vector__XXX
 SG_ EDS_Charisma_FahrPr  : 12|4@1+ (1.000000,0.000000) [0.000000|15.000000] "" Vector__XXX
 SG_ EDS_Charisma_Status  : 16|2@1+ (1.000000,0.000000) [0.000000|3.000000] "" Vector__XXX
 SG_ HHC_Charisma_Status  : 18|2@1+ (1.000000,0.000000) [0.000000|3.000000] "" Vector__XXX
 SG_ HHC_Charisma_FahrPr  : 20|4@1+ (1.000000,0.000000) [0.000000|15.000000] "" Vector__XXX
 SG_ RLE_Anzeigen  : 24|3@1+ (1.000000,0.000000) [0.000000|7.000000] "" Vector__XXX
 SG_ ESC_Lernfreigabe_Abrollumfang  : 27|1@1+ (1.000000,0.000000) [0.000000|1.000000] "" Vector__XXX
 SG_ ESC_Texte_eBKV_Betaetigung  : 28|4@1+ (1.000000,0.000000) [0.000000|15.000000] "" Vector__XXX
 SG_ ESC_MBK_Meldungen  : 32|2@1+ (1.000000,0.000000) [0.000000|3.000000] "" Vector__XXX
 SG_ ESC_Anf_KL  : 34|5@1+ (3.225806,0.000000) [0.000000|100.000000] "Unit_PerCent" Motor_BEV
 SG_ ESC_Anf_KV  : 39|1@1+ (1.000000,0.000000) [0.000000|1.000000] "" Motor_BEV
 SG_ ESC_FBA_Meldungen  : 40|2@1+ (1.000000,0.000000) [0.000000|3.000000] "" Vector__XXX
 SG_ DBK_Fahrerwarnung  : 42|2@1+ (1.000000,0.000000) [0.000000|3.000000] "" Vector__XXX

BO_ 2527679668 eTM_01: 8 Motor_BEV
 SG_ eTM_Ventil1_Status  : 7|3@1+ (1.000000,0.000000) [0.000000|7.000000] "" ICAS1_Gateway
 SG_ eTM_Ventil2_Status  : 10|3@1+ (1.000000,0.000000) [0.000000|7.000000] "" ICAS1_Gateway
 SG_ eTM_Ventil3_Status  : 13|3@1+ (1.000000,0.000000) [0.000000|7.000000] "" ICAS1_Gateway
 SG_ eTM_Pumpe3_Status  : 16|4@1+ (10.000000,0.000000) [0.000000|130.000000] "Unit_PerCent" ICAS1_Gateway
 SG_ eTM_BMS_Pumpe1_SollAnsteuerung  : 20|4@1+ (10.000000,0.000000) [0.000000|130.000000] "Unit_PerCent" ICAS1_Gateway
 SG_ eTM_Pumpe2_Volumenstrom  : 24|6@1+ (0.500000,0.000000) [0.000000|30.500000] "Unit_LiterPerMinut" ICAS1_Gateway LE1 LE2
 SG_ eTM_BMS_Ventil2_Befuellung  : 31|1@1+ (1.000000,0.000000) [0.000000|1.000000] "" ICAS1_Gateway
 SG_ eTM_Pumpe1_Volumenstrom  : 32|6@1+ (0.500000,0.000000) [0.000000|30.500000] "Unit_LiterPerMinut" ICAS1_Gateway LE1 LE2
 SG_ eTM_BMS_Pumpe1_Befuellung  : 38|1@1+ (1.000000,0.000000) [0.000000|1.000000] "" ICAS1_Gateway
 SG_ eTM_BMS_Ventil1_Befuellung  : 39|1@1+ (1.000000,0.000000) [0.000000|1.000000] "" ICAS1_Gateway
 SG_ eTM_Pumpe1_Status  : 40|4@1+ (10.000000,0.000000) [0.000000|130.000000] "Unit_PerCent" ICAS1_Gateway LE1 LE2
 SG_ eTM_Pumpe2_Status  : 44|4@1+ (10.000000,0.000000) [0.000000|130.000000] "Unit_PerCent" ICAS1_Gateway LE1 LE2
 SG_ eTM_Temperatur_1  : 48|8@1+ (0.750000,-40.000000) [-40.000000|149.750000] "Unit_DegreCelsi" ICAS1_Gateway LE1 LE2
 SG_ eTM_Temperatur_2  : 56|8@1+ (0.750000,-40.000000) [-40.000000|149.750000] "Unit_DegreCelsi" ICAS1_Gateway LE1 LE2

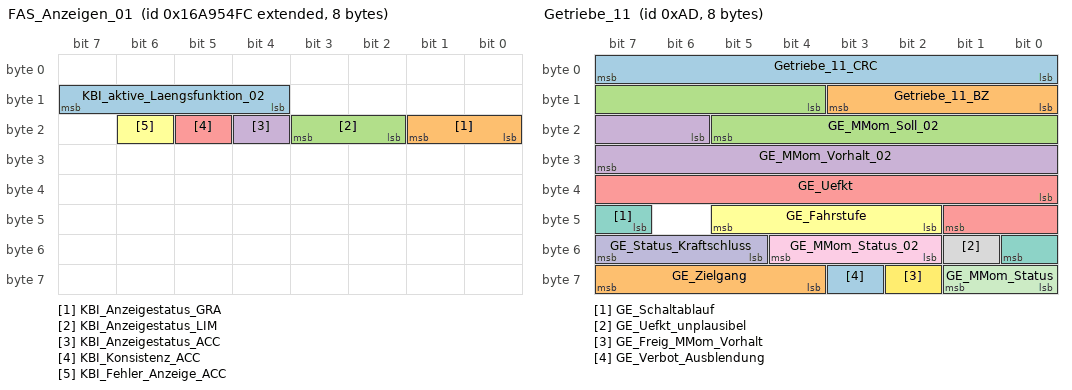
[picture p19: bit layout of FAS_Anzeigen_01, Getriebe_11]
BO_ 2527679740 FAS_Anzeigen_01: 8 ICAS1_KommunikationsServer
 SG_ KBI_aktive_Laengsfunktion_02  : 12|4@1+ (1.000000,0.000000) [0.000000|15.000000] "" Motor_BEV
 SG_ KBI_Anzeigestatus_GRA  : 16|2@1+ (1.000000,0.000000) [0.000000|3.000000] "" Motor_BEV
 SG_ KBI_Anzeigestatus_LIM  : 18|2@1+ (1.000000,0.000000) [0.000000|3.000000] "" Motor_BEV
 SG_ KBI_Anzeigestatus_ACC  : 20|1@1+ (1.000000,0.000000) [0.000000|1.000000] "" Vector__XXX
 SG_ KBI_Konsistenz_ACC  : 21|1@1+ (1.000000,0.000000) [0.000000|1.000000] "" Vector__XXX
 SG_ KBI_Fehler_Anzeige_ACC  : 22|1@1+ (1.000000,0.000000) [0.000000|1.000000] "" Vector__XXX

BO_ 2589283684 FoD_01: 8 ICAS1_Gateway
 SG_ GRA_FoD_Status  : 58|2@1+ (1.000000,0.000000) [0.000000|3.000000] "" Vector__XXX
 SG_ FoD_Transmission_Info  : 60|2@1+ (1.000000,0.000000) [0.000000|3.000000] "" Motor_BEV

BO_ 2549875574 FoD_MO_01_Req: 8 ICAS1_Gateway
 SG_ FoD_MO_01_Req_Data  : 0|64@1+ (1.000000,0.000000) [0.000000|18446744073709551616.000000] "" Motor_BEV

BO_ 2550006646 FoD_MO_01_Resp: 8 Motor_BEV
 SG_ FoD_MO_01_Resp_Data  : 0|64@1+ (1.000000,0.000000) [0.000000|18446744073709551616.000000] "" ICAS1_Gateway

BO_ 987 Gateway_72: 8 ICAS1_Gateway
 SG_ BCM_01_alt  : 0|1@1+ (1.000000,0.000000) [0.000000|1.000000] "" Airbag
 SG_ SMLS_01_alt  : 1|1@1+ (1.000000,0.000000) [0.000000|1.000000] "" Vector__XXX
 SG_ ZV_02_alt  : 2|1@1+ (1.000000,0.000000) [0.000000|1.000000] "" Vector__XXX
 SG_ Wischer_01_alt  : 3|1@1+ (1.000000,0.000000) [0.000000|1.000000] "" Vector__XXX
 SG_ Anhaenger_01_alt  : 4|1@1+ (1.000000,0.000000) [0.000000|1.000000] "" Airbag
 SG_ Klima_Sensor_02_alt  : 5|1@1+ (1.000000,0.000000) [0.000000|1.000000] "" Vector__XXX
 SG_ Verdeck_01_alt  : 6|1@1+ (1.000000,0.000000) [0.000000|1.000000] "" Vector__XXX
 SG_ Klima_11_alt  : 7|1@1+ (1.000000,0.000000) [0.000000|1.000000] "" Vector__XXX
 SG_ WFS_01_alt  : 8|1@1+ (1.000000,0.000000) [0.000000|1.000000] "" Vector__XXX
 SG_ Licht_Anf_01_alt  : 9|1@1+ (1.000000,0.000000) [0.000000|1.000000] "" Vector__XXX
 SG_ ZV_verriegelt_extern_soll  : 10|1@1+ (1.000000,0.000000) [0.000000|1.000000] "" Vector__XXX
 SG_ BH_Lichthupe  : 11|1@1+ (1.000000,0.000000) [0.000000|1.000000] "" Vector__XXX
 SG_ WFS_Klemmenfreigabe  : 12|1@1+ (1.000000,0.000000) [0.000000|1.000000] "" Vector__XXX
 SG_ ZV_Tankklappe_offen  : 13|1@1+ (1.000000,0.000000) [0.000000|1.000000] "" Vector__XXX
 SG_ AAG_Anhaenger_abgesteckt  : 14|1@1+ (1.000000,0.000000) [0.000000|1.000000] "" Vector__XXX
 SG_ BCM1_LDS_Stellung  : 15|3@1+ (1.000000,0.000000) [0.000000|7.000000] "" Vector__XXX
 SG_ VS_Verdeck_Anf  : 18|1@1+ (1.000000,0.000000) [0.000000|1.000000] "" Vector__XXX
 SG_ VS_VD_entriegelt  : 19|1@1+ (1.000000,0.000000) [0.000000|1.000000] "" Vector__XXX
 SG_ ZV_HFS_offen  : 20|1@1+ (1.000000,0.000000) [0.000000|1.000000] "" Vector__XXX
 SG_ ZV_HBFS_offen  : 21|1@1+ (1.000000,0.000000) [0.000000|1.000000] "" Vector__XXX
 SG_ VS_VD_offen_ver  : 22|1@1+ (1.000000,0.000000) [0.000000|1.000000] "" Vector__XXX
 SG_ VS_VD_zu_ver  : 23|1@1+ (1.000000,0.000000) [0.000000|1.000000] "" Vector__XXX
 SG_ ZV_BT_offen  : 24|1@1+ (1.000000,0.000000) [0.000000|1.000000] "" Vector__XXX
 SG_ BCM1_Rueckfahrlicht_Schalter  : 25|1@1+ (1.000000,0.000000) [0.000000|1.000000] "" Airbag Motor_BEV
 SG_ ZV_FT_offen  : 26|1@1+ (1.000000,0.000000) [0.000000|1.000000] "" Vector__XXX
 SG_ Wischer_vorne_aktiv  : 27|1@1+ (1.000000,0.000000) [0.000000|1.000000] "" Vector__XXX
 SG_ AAG_Anhaenger_erkannt  : 28|1@1+ (1.000000,0.000000) [0.000000|1.000000] "" Airbag
 SG_ BCM1_MH_Schalter  : 29|1@1+ (1.000000,0.000000) [0.000000|1.000000] "" Vector__XXX
 SG_ ZV_HD_offen  : 30|1@1+ (1.000000,0.000000) [0.000000|1.000000] "" Vector__XXX
 SG_ Waschen_vorne_aktiv  : 31|1@1+ (1.000000,0.000000) [0.000000|1.000000] "" Vector__XXX
 SG_ KL_Thermomanagement  : 32|2@1+ (1.000000,0.000000) [0.000000|3.000000] "" Vector__XXX
 SG_ WFS_Schluessel_Fahrberecht  : 34|4@1+ (1.000000,0.000000) [0.000000|15.000000] "" Vector__XXX
 SG_ BCM_Rueckfahrlicht_Anf  : 38|1@1+ (1.000000,0.000000) [0.000000|1.000000] "" Vector__XXX
 SG_ WWSs_01_alt  : 39|1@1+ (1.000000,0.000000) [0.000000|1.000000] "" Vector__XXX
 SG_ BCM_Tankklappensteller_Fehler  : 40|1@1+ (1.000000,0.000000) [0.000000|1.000000] "" Vector__XXX
 SG_ AAG_LED_aktiv  : 41|1@1+ (1.000000,0.000000) [0.000000|1.000000] "" Vector__XXX
 SG_ ZV_verriegelt_soll  : 42|2@1+ (1.000000,0.000000) [0.000000|3.000000] "" Vector__XXX
 SG_ ZV_Schluessel_Zugang  : 44|4@1+ (1.000000,0.000000) [0.000000|15.000000] "" Vector__XXX
 SG_ WFS_ID_Geb_autorisiert_in_Kl15  : 48|1@1+ (1.000000,0.000000) [0.000000|1.000000] "" Vector__XXX
 SG_ BH_Fernlicht  : 49|1@1+ (1.000000,0.000000) [0.000000|1.000000] "" Vector__XXX
 SG_ BH_Blinker_li  : 50|1@1+ (1.000000,0.000000) [0.000000|1.000000] "" Vector__XXX
 SG_ BH_Blinker_re  : 51|1@1+ (1.000000,0.000000) [0.000000|1.000000] "" Vector__XXX
 SG_ BCM1_OBD_FStatus_ATemp  : 52|4@1+ (1.000000,0.000000) [0.000000|15.000000] "" Vector__XXX
 SG_ BCM1_Aussen_Temp_ungef  : 56|8@1+ (0.500000,-50.000000) [-50.000000|76.000000] "Unit_DegreCelsi" Vector__XXX

BO_ 173 Getriebe_11: 8 Motor_BEV
 SG_ Getriebe_11_CRC  : 0|8@1+ (1.000000,0.000000) [0.000000|255.000000] "" ICAS1_Gateway
 SG_ Getriebe_11_BZ  : 8|4@1+ (1.000000,0.000000) [0.000000|15.000000] "" ICAS1_Gateway
 SG_ GE_MMom_Soll_02  : 12|10@1+ (1.000000,-509.000000) [-509.000000|509.000000] "" ICAS1_Gateway
 SG_ GE_MMom_Vorhalt_02  : 22|10@1+ (1.000000,-509.000000) [-509.000000|509.000000] "" ICAS1_Gateway
 SG_ GE_Uefkt  : 32|10@1+ (0.100000,0.000000) [0.000000|102.200000] "" ICAS1_Gateway
 SG_ GE_Fahrstufe  : 42|4@1+ (1.000000,0.000000) [0.000000|15.000000] "" ICAS1_Gateway
 SG_ GE_Schaltablauf  : 47|2@1+ (1.000000,0.000000) [0.000000|3.000000] "" ICAS1_Gateway
 SG_ GE_Uefkt_unplausibel  : 49|1@1+ (1.000000,0.000000) [0.000000|1.000000] "" ICAS1_Gateway
 SG_ GE_MMom_Status_02  : 50|3@1+ (1.000000,0.000000) [0.000000|7.000000] "" ICAS1_Gateway
 SG_ GE_Status_Kraftschluss  : 53|3@1+ (1.000000,0.000000) [0.000000|7.000000] "" ICAS1_Gateway
 SG_ GE_MMom_Status  : 56|2@1+ (1.000000,0.000000) [0.000000|3.000000] "" ICAS1_Gateway
 SG_ GE_Freig_MMom_Vorhalt  : 58|1@1+ (1.000000,0.000000) [0.000000|1.000000] "" ICAS1_Gateway
 SG_ GE_Verbot_Ausblendung  : 59|1@1+ (1.000000,0.000000) [0.000000|1.000000] "" ICAS1_Gateway
 SG_ GE_Zielgang  : 60|4@1+ (1.000000,0.000000) [0.000000|15.000000] "" ICAS1_Gateway
